VERSION ""

NS_ :

BS_:

BU_: MVS RCR_R RCR_L SNR ADAS ADAS_GW ENM THM CHR BAT BEV BEV_GW MET C_ECU C_ECU_GW

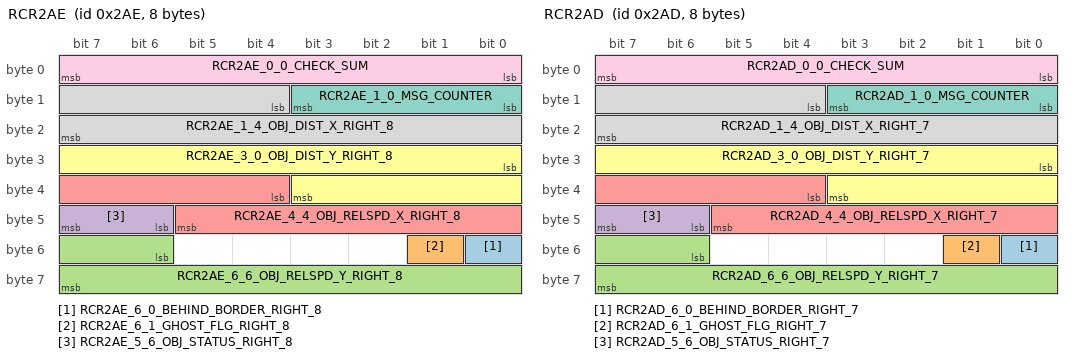
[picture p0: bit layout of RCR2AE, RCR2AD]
BO_ 686 RCR2AE: 8 RCR_R
 SG_ RCR2AE_6_0_BEHIND_BORDER_RIGHT_8 : 48|1@1+ (1,0) [0|1] ""  ADAS
 SG_ RCR2AE_6_1_GHOST_FLG_RIGHT_8 : 49|1@1+ (1,0) [0|1] ""  ADAS
 SG_ RCR2AE_6_6_OBJ_RELSPD_Y_RIGHT_8 : 54|10@1- (0.1,0) [-51.2|51.1] "m/s"  ADAS
 SG_ RCR2AE_5_6_OBJ_STATUS_RIGHT_8 : 46|2@1+ (1,0) [0|3] ""  ADAS
 SG_ RCR2AE_4_4_OBJ_RELSPD_X_RIGHT_8 : 36|10@1- (0.1,0) [-51.2|51.1] "m/s"  ADAS
 SG_ RCR2AE_3_0_OBJ_DIST_Y_RIGHT_8 : 24|12@1- (0.1,0) [-204.8|204.7] "m"  ADAS
 SG_ RCR2AE_1_0_MSG_COUNTER : 8|4@1+ (1,0) [0|15] ""  ADAS
 SG_ RCR2AE_1_4_OBJ_DIST_X_RIGHT_8 : 12|12@1- (0.1,0) [-204.8|204.7] "m"  ADAS
 SG_ RCR2AE_0_0_CHECK_SUM : 0|8@1+ (1,0) [0|255] ""  ADAS

BO_ 685 RCR2AD: 8 RCR_R
 SG_ RCR2AD_6_0_BEHIND_BORDER_RIGHT_7 : 48|1@1+ (1,0) [0|1] ""  ADAS
 SG_ RCR2AD_6_1_GHOST_FLG_RIGHT_7 : 49|1@1+ (1,0) [0|1] ""  ADAS
 SG_ RCR2AD_6_6_OBJ_RELSPD_Y_RIGHT_7 : 54|10@1- (0.1,0) [-51.2|51.1] "m/s"  ADAS
 SG_ RCR2AD_5_6_OBJ_STATUS_RIGHT_7 : 46|2@1+ (1,0) [0|3] ""  ADAS
 SG_ RCR2AD_4_4_OBJ_RELSPD_X_RIGHT_7 : 36|10@1- (0.1,0) [-51.2|51.1] "m/s"  ADAS
 SG_ RCR2AD_3_0_OBJ_DIST_Y_RIGHT_7 : 24|12@1- (0.1,0) [-204.8|204.7] "m"  ADAS
 SG_ RCR2AD_1_0_MSG_COUNTER : 8|4@1+ (1,0) [0|15] ""  ADAS
 SG_ RCR2AD_1_4_OBJ_DIST_X_RIGHT_7 : 12|12@1- (0.1,0) [-204.8|204.7] "m"  ADAS
 SG_ RCR2AD_0_0_CHECK_SUM : 0|8@1+ (1,0) [0|255] ""  ADAS

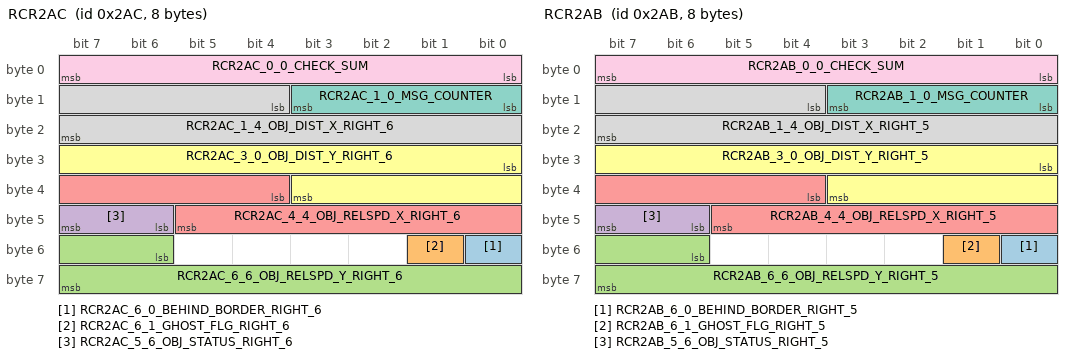
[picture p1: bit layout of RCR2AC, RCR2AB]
BO_ 684 RCR2AC: 8 RCR_R
 SG_ RCR2AC_6_0_BEHIND_BORDER_RIGHT_6 : 48|1@1+ (1,0) [0|1] ""  ADAS
 SG_ RCR2AC_6_1_GHOST_FLG_RIGHT_6 : 49|1@1+ (1,0) [0|1] ""  ADAS
 SG_ RCR2AC_6_6_OBJ_RELSPD_Y_RIGHT_6 : 54|10@1- (0.1,0) [-51.2|51.1] "m/s"  ADAS
 SG_ RCR2AC_5_6_OBJ_STATUS_RIGHT_6 : 46|2@1+ (1,0) [0|3] ""  ADAS
 SG_ RCR2AC_4_4_OBJ_RELSPD_X_RIGHT_6 : 36|10@1- (0.1,0) [-51.2|51.1] "m/s"  ADAS
 SG_ RCR2AC_3_0_OBJ_DIST_Y_RIGHT_6 : 24|12@1- (0.1,0) [-204.8|204.7] "m"  ADAS
 SG_ RCR2AC_1_0_MSG_COUNTER : 8|4@1+ (1,0) [0|15] ""  ADAS
 SG_ RCR2AC_1_4_OBJ_DIST_X_RIGHT_6 : 12|12@1- (0.1,0) [-204.8|204.7] "m"  ADAS
 SG_ RCR2AC_0_0_CHECK_SUM : 0|8@1+ (1,0) [0|255] ""  ADAS

BO_ 683 RCR2AB: 8 RCR_R
 SG_ RCR2AB_6_0_BEHIND_BORDER_RIGHT_5 : 48|1@1+ (1,0) [0|1] ""  ADAS
 SG_ RCR2AB_6_1_GHOST_FLG_RIGHT_5 : 49|1@1+ (1,0) [0|1] ""  ADAS
 SG_ RCR2AB_6_6_OBJ_RELSPD_Y_RIGHT_5 : 54|10@1- (0.1,0) [-51.2|51.1] "m/s"  ADAS
 SG_ RCR2AB_5_6_OBJ_STATUS_RIGHT_5 : 46|2@1+ (1,0) [0|3] ""  ADAS
 SG_ RCR2AB_4_4_OBJ_RELSPD_X_RIGHT_5 : 36|10@1- (0.1,0) [-51.2|51.1] "m/s"  ADAS
 SG_ RCR2AB_3_0_OBJ_DIST_Y_RIGHT_5 : 24|12@1- (0.1,0) [-204.8|204.7] "m"  ADAS
 SG_ RCR2AB_1_0_MSG_COUNTER : 8|4@1+ (1,0) [0|15] ""  ADAS
 SG_ RCR2AB_1_4_OBJ_DIST_X_RIGHT_5 : 12|12@1- (0.1,0) [-204.8|204.7] "m"  ADAS
 SG_ RCR2AB_0_0_CHECK_SUM : 0|8@1+ (1,0) [0|255] ""  ADAS

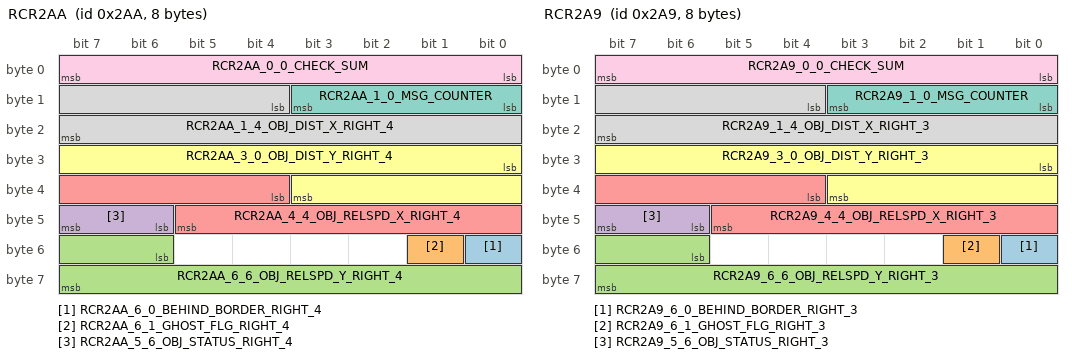
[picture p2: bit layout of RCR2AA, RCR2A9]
BO_ 682 RCR2AA: 8 RCR_R
 SG_ RCR2AA_6_0_BEHIND_BORDER_RIGHT_4 : 48|1@1+ (1,0) [0|1] ""  ADAS
 SG_ RCR2AA_6_1_GHOST_FLG_RIGHT_4 : 49|1@1+ (1,0) [0|1] ""  ADAS
 SG_ RCR2AA_6_6_OBJ_RELSPD_Y_RIGHT_4 : 54|10@1- (0.1,0) [-51.2|51.1] "m/s"  ADAS
 SG_ RCR2AA_5_6_OBJ_STATUS_RIGHT_4 : 46|2@1+ (1,0) [0|3] ""  ADAS
 SG_ RCR2AA_4_4_OBJ_RELSPD_X_RIGHT_4 : 36|10@1- (0.1,0) [-51.2|51.1] "m/s"  ADAS
 SG_ RCR2AA_3_0_OBJ_DIST_Y_RIGHT_4 : 24|12@1- (0.1,0) [-204.8|204.7] "m"  ADAS
 SG_ RCR2AA_1_0_MSG_COUNTER : 8|4@1+ (1,0) [0|15] ""  ADAS
 SG_ RCR2AA_1_4_OBJ_DIST_X_RIGHT_4 : 12|12@1- (0.1,0) [-204.8|204.7] "m"  ADAS
 SG_ RCR2AA_0_0_CHECK_SUM : 0|8@1+ (1,0) [0|255] ""  ADAS

BO_ 681 RCR2A9: 8 RCR_R
 SG_ RCR2A9_6_0_BEHIND_BORDER_RIGHT_3 : 48|1@1+ (1,0) [0|1] ""  ADAS
 SG_ RCR2A9_6_1_GHOST_FLG_RIGHT_3 : 49|1@1+ (1,0) [0|1] ""  ADAS
 SG_ RCR2A9_6_6_OBJ_RELSPD_Y_RIGHT_3 : 54|10@1- (0.1,0) [-51.2|51.1] "m/s"  ADAS
 SG_ RCR2A9_5_6_OBJ_STATUS_RIGHT_3 : 46|2@1+ (1,0) [0|3] ""  ADAS
 SG_ RCR2A9_4_4_OBJ_RELSPD_X_RIGHT_3 : 36|10@1- (0.1,0) [-51.2|51.1] "m/s"  ADAS
 SG_ RCR2A9_3_0_OBJ_DIST_Y_RIGHT_3 : 24|12@1- (0.1,0) [-204.8|204.7] "m"  ADAS
 SG_ RCR2A9_1_0_MSG_COUNTER : 8|4@1+ (1,0) [0|15] ""  ADAS
 SG_ RCR2A9_1_4_OBJ_DIST_X_RIGHT_3 : 12|12@1- (0.1,0) [-204.8|204.7] "m"  ADAS
 SG_ RCR2A9_0_0_CHECK_SUM : 0|8@1+ (1,0) [0|255] ""  ADAS

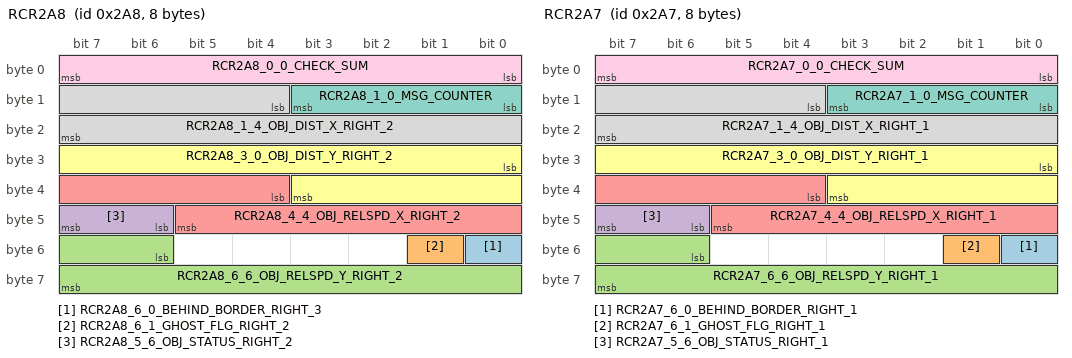
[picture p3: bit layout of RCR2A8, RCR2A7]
BO_ 680 RCR2A8: 8 RCR_R
 SG_ RCR2A8_6_0_BEHIND_BORDER_RIGHT_3 : 48|1@1+ (1,0) [0|1] ""  ADAS
 SG_ RCR2A8_6_1_GHOST_FLG_RIGHT_2 : 49|1@1+ (1,0) [0|1] ""  ADAS
 SG_ RCR2A8_6_6_OBJ_RELSPD_Y_RIGHT_2 : 54|10@1- (0.1,0) [-51.2|51.1] "m/s"  ADAS
 SG_ RCR2A8_5_6_OBJ_STATUS_RIGHT_2 : 46|2@1+ (1,0) [0|3] ""  ADAS
 SG_ RCR2A8_4_4_OBJ_RELSPD_X_RIGHT_2 : 36|10@1- (0.1,0) [-51.2|51.1] "m/s"  ADAS
 SG_ RCR2A8_3_0_OBJ_DIST_Y_RIGHT_2 : 24|12@1- (0.1,0) [-204.8|204.7] "m"  ADAS
 SG_ RCR2A8_1_0_MSG_COUNTER : 8|4@1+ (1,0) [0|15] ""  ADAS
 SG_ RCR2A8_1_4_OBJ_DIST_X_RIGHT_2 : 12|12@1- (0.1,0) [-204.8|204.7] "m"  ADAS
 SG_ RCR2A8_0_0_CHECK_SUM : 0|8@1+ (1,0) [0|255] ""  ADAS

BO_ 679 RCR2A7: 8 RCR_R
 SG_ RCR2A7_6_0_BEHIND_BORDER_RIGHT_1 : 48|1@1+ (1,0) [0|1] ""  ADAS
 SG_ RCR2A7_6_1_GHOST_FLG_RIGHT_1 : 49|1@1+ (1,0) [0|1] ""  ADAS
 SG_ RCR2A7_6_6_OBJ_RELSPD_Y_RIGHT_1 : 54|10@1- (0.1,0) [-51.2|51.1] "m/s"  ADAS
 SG_ RCR2A7_5_6_OBJ_STATUS_RIGHT_1 : 46|2@1+ (1,0) [0|3] ""  ADAS
 SG_ RCR2A7_4_4_OBJ_RELSPD_X_RIGHT_1 : 36|10@1- (0.1,0) [-51.2|51.1] "m/s"  ADAS
 SG_ RCR2A7_3_0_OBJ_DIST_Y_RIGHT_1 : 24|12@1- (0.1,0) [-204.8|204.7] "m"  ADAS
 SG_ RCR2A7_1_0_MSG_COUNTER : 8|4@1+ (1,0) [0|15] ""  ADAS
 SG_ RCR2A7_1_4_OBJ_DIST_X_RIGHT_1 : 12|12@1- (0.1,0) [-204.8|204.7] "m"  ADAS
 SG_ RCR2A7_0_0_CHECK_SUM : 0|8@1+ (1,0) [0|255] ""  ADAS

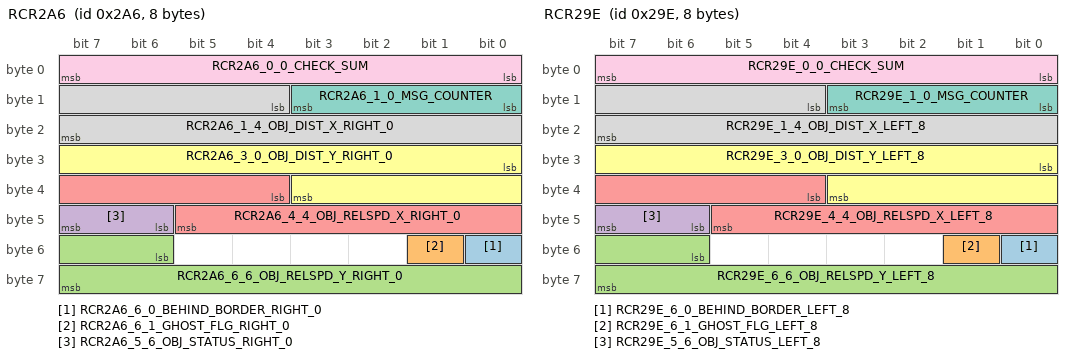
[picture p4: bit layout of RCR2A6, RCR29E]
BO_ 678 RCR2A6: 8 RCR_R
 SG_ RCR2A6_6_0_BEHIND_BORDER_RIGHT_0 : 48|1@1+ (1,0) [0|1] ""  ADAS
 SG_ RCR2A6_6_1_GHOST_FLG_RIGHT_0 : 49|1@1+ (1,0) [0|1] ""  ADAS
 SG_ RCR2A6_6_6_OBJ_RELSPD_Y_RIGHT_0 : 54|10@1- (0.1,0) [-51.2|51.1] "m/s"  ADAS
 SG_ RCR2A6_5_6_OBJ_STATUS_RIGHT_0 : 46|2@1+ (1,0) [0|3] ""  ADAS
 SG_ RCR2A6_4_4_OBJ_RELSPD_X_RIGHT_0 : 36|10@1- (0.1,0) [-51.2|51.1] "m/s"  ADAS
 SG_ RCR2A6_3_0_OBJ_DIST_Y_RIGHT_0 : 24|12@1- (0.1,0) [-204.8|204.7] "m"  ADAS
 SG_ RCR2A6_1_0_MSG_COUNTER : 8|4@1+ (1,0) [0|15] ""  ADAS
 SG_ RCR2A6_1_4_OBJ_DIST_X_RIGHT_0 : 12|12@1- (0.1,0) [-204.8|204.7] "m"  ADAS
 SG_ RCR2A6_0_0_CHECK_SUM : 0|8@1+ (1,0) [0|255] ""  ADAS

BO_ 670 RCR29E: 8 RCR_L
 SG_ RCR29E_6_0_BEHIND_BORDER_LEFT_8 : 48|1@1+ (1,0) [0|1] ""  ADAS
 SG_ RCR29E_6_1_GHOST_FLG_LEFT_8 : 49|1@1+ (1,0) [0|1] ""  ADAS
 SG_ RCR29E_6_6_OBJ_RELSPD_Y_LEFT_8 : 54|10@1- (0.1,0) [-51.2|51.1] "m/s"  ADAS
 SG_ RCR29E_5_6_OBJ_STATUS_LEFT_8 : 46|2@1+ (1,0) [0|3] ""  ADAS
 SG_ RCR29E_4_4_OBJ_RELSPD_X_LEFT_8 : 36|10@1- (0.1,0) [-51.2|51.1] "m/s"  ADAS
 SG_ RCR29E_3_0_OBJ_DIST_Y_LEFT_8 : 24|12@1- (0.1,0) [-204.8|204.7] "m"  ADAS
 SG_ RCR29E_1_0_MSG_COUNTER : 8|4@1+ (1,0) [0|15] ""  ADAS
 SG_ RCR29E_1_4_OBJ_DIST_X_LEFT_8 : 12|12@1- (0.1,0) [-204.8|204.7] "m"  ADAS
 SG_ RCR29E_0_0_CHECK_SUM : 0|8@1+ (1,0) [0|255] ""  ADAS

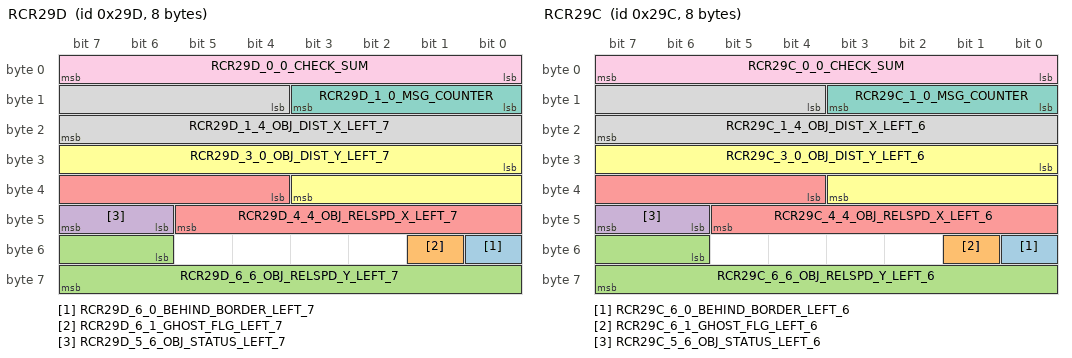
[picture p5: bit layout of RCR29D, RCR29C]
BO_ 669 RCR29D: 8 RCR_L
 SG_ RCR29D_6_0_BEHIND_BORDER_LEFT_7 : 48|1@1+ (1,0) [0|1] ""  ADAS
 SG_ RCR29D_6_1_GHOST_FLG_LEFT_7 : 49|1@1+ (1,0) [0|1] ""  ADAS
 SG_ RCR29D_6_6_OBJ_RELSPD_Y_LEFT_7 : 54|10@1- (0.1,0) [-51.2|51.1] "m/s"  ADAS
 SG_ RCR29D_5_6_OBJ_STATUS_LEFT_7 : 46|2@1+ (1,0) [0|3] ""  ADAS
 SG_ RCR29D_4_4_OBJ_RELSPD_X_LEFT_7 : 36|10@1- (0.1,0) [-51.2|51.1] "m/s"  ADAS
 SG_ RCR29D_3_0_OBJ_DIST_Y_LEFT_7 : 24|12@1- (0.1,0) [-204.8|204.7] "m"  ADAS
 SG_ RCR29D_1_0_MSG_COUNTER : 8|4@1+ (1,0) [0|15] ""  ADAS
 SG_ RCR29D_1_4_OBJ_DIST_X_LEFT_7 : 12|12@1- (0.1,0) [-204.8|204.7] "m"  ADAS
 SG_ RCR29D_0_0_CHECK_SUM : 0|8@1+ (1,0) [0|255] ""  ADAS

BO_ 668 RCR29C: 8 RCR_L
 SG_ RCR29C_6_0_BEHIND_BORDER_LEFT_6 : 48|1@1+ (1,0) [0|1] ""  ADAS
 SG_ RCR29C_6_1_GHOST_FLG_LEFT_6 : 49|1@1+ (1,0) [0|1] ""  ADAS
 SG_ RCR29C_6_6_OBJ_RELSPD_Y_LEFT_6 : 54|10@1- (0.1,0) [-51.2|51.1] "m/s"  ADAS
 SG_ RCR29C_5_6_OBJ_STATUS_LEFT_6 : 46|2@1+ (1,0) [0|3] ""  ADAS
 SG_ RCR29C_4_4_OBJ_RELSPD_X_LEFT_6 : 36|10@1- (0.1,0) [-51.2|51.1] "m/s"  ADAS
 SG_ RCR29C_3_0_OBJ_DIST_Y_LEFT_6 : 24|12@1- (0.1,0) [-204.8|204.7] "m"  ADAS
 SG_ RCR29C_1_0_MSG_COUNTER : 8|4@1+ (1,0) [0|15] ""  ADAS
 SG_ RCR29C_1_4_OBJ_DIST_X_LEFT_6 : 12|12@1- (0.1,0) [-204.8|204.7] "m"  ADAS
 SG_ RCR29C_0_0_CHECK_SUM : 0|8@1+ (1,0) [0|255] ""  ADAS

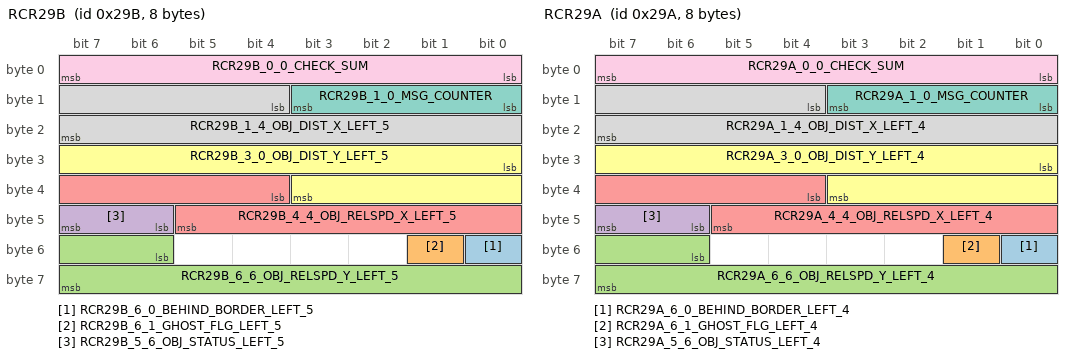
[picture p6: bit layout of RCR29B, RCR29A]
BO_ 667 RCR29B: 8 RCR_L
 SG_ RCR29B_6_0_BEHIND_BORDER_LEFT_5 : 48|1@1+ (1,0) [0|1] ""  ADAS
 SG_ RCR29B_6_1_GHOST_FLG_LEFT_5 : 49|1@1+ (1,0) [0|1] ""  ADAS
 SG_ RCR29B_6_6_OBJ_RELSPD_Y_LEFT_5 : 54|10@1- (0.1,0) [-51.2|51.1] "m/s"  ADAS
 SG_ RCR29B_5_6_OBJ_STATUS_LEFT_5 : 46|2@1+ (1,0) [0|3] ""  ADAS
 SG_ RCR29B_4_4_OBJ_RELSPD_X_LEFT_5 : 36|10@1- (0.1,0) [-51.2|51.1] "m/s"  ADAS
 SG_ RCR29B_3_0_OBJ_DIST_Y_LEFT_5 : 24|12@1- (0.1,0) [-204.8|204.7] "m"  ADAS
 SG_ RCR29B_1_0_MSG_COUNTER : 8|4@1+ (1,0) [0|15] ""  ADAS
 SG_ RCR29B_1_4_OBJ_DIST_X_LEFT_5 : 12|12@1- (0.1,0) [-204.8|204.7] "m"  ADAS
 SG_ RCR29B_0_0_CHECK_SUM : 0|8@1+ (1,0) [0|255] ""  ADAS

BO_ 666 RCR29A: 8 RCR_L
 SG_ RCR29A_6_0_BEHIND_BORDER_LEFT_4 : 48|1@1+ (1,0) [0|1] ""  ADAS
 SG_ RCR29A_6_1_GHOST_FLG_LEFT_4 : 49|1@1+ (1,0) [0|1] ""  ADAS
 SG_ RCR29A_6_6_OBJ_RELSPD_Y_LEFT_4 : 54|10@1- (0.1,0) [-51.2|51.1] "m/s"  ADAS
 SG_ RCR29A_5_6_OBJ_STATUS_LEFT_4 : 46|2@1+ (1,0) [0|3] ""  ADAS
 SG_ RCR29A_4_4_OBJ_RELSPD_X_LEFT_4 : 36|10@1- (0.1,0) [-51.2|51.1] "m/s"  ADAS
 SG_ RCR29A_3_0_OBJ_DIST_Y_LEFT_4 : 24|12@1- (0.1,0) [-204.8|204.7] "m"  ADAS
 SG_ RCR29A_1_0_MSG_COUNTER : 8|4@1+ (1,0) [0|15] ""  ADAS
 SG_ RCR29A_1_4_OBJ_DIST_X_LEFT_4 : 12|12@1- (0.1,0) [-204.8|204.7] "m"  ADAS
 SG_ RCR29A_0_0_CHECK_SUM : 0|8@1+ (1,0) [0|255] ""  ADAS

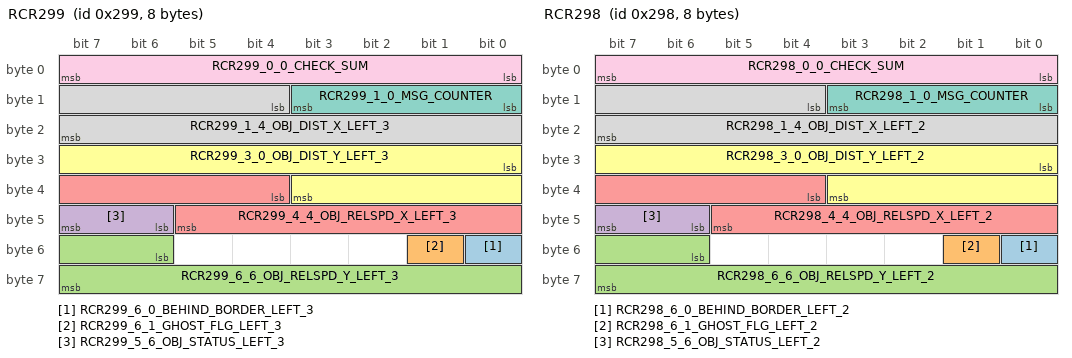
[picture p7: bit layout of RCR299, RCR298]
BO_ 665 RCR299: 8 RCR_L
 SG_ RCR299_6_0_BEHIND_BORDER_LEFT_3 : 48|1@1+ (1,0) [0|1] ""  ADAS
 SG_ RCR299_6_1_GHOST_FLG_LEFT_3 : 49|1@1+ (1,0) [0|1] ""  ADAS
 SG_ RCR299_6_6_OBJ_RELSPD_Y_LEFT_3 : 54|10@1- (0.1,0) [-51.2|51.1] "m/s"  ADAS
 SG_ RCR299_5_6_OBJ_STATUS_LEFT_3 : 46|2@1+ (1,0) [0|3] ""  ADAS
 SG_ RCR299_4_4_OBJ_RELSPD_X_LEFT_3 : 36|10@1- (0.1,0) [-51.2|51.1] "m/s"  ADAS
 SG_ RCR299_3_0_OBJ_DIST_Y_LEFT_3 : 24|12@1- (0.1,0) [-204.8|204.7] "m"  ADAS
 SG_ RCR299_1_0_MSG_COUNTER : 8|4@1+ (1,0) [0|15] ""  ADAS
 SG_ RCR299_1_4_OBJ_DIST_X_LEFT_3 : 12|12@1- (0.1,0) [-204.8|204.7] "m"  ADAS
 SG_ RCR299_0_0_CHECK_SUM : 0|8@1+ (1,0) [0|255] ""  ADAS

BO_ 664 RCR298: 8 RCR_L
 SG_ RCR298_6_0_BEHIND_BORDER_LEFT_2 : 48|1@1+ (1,0) [0|1] ""  ADAS
 SG_ RCR298_6_1_GHOST_FLG_LEFT_2 : 49|1@1+ (1,0) [0|1] ""  ADAS
 SG_ RCR298_6_6_OBJ_RELSPD_Y_LEFT_2 : 54|10@1- (0.1,0) [-51.2|51.1] "m/s"  ADAS
 SG_ RCR298_5_6_OBJ_STATUS_LEFT_2 : 46|2@1+ (1,0) [0|3] ""  ADAS
 SG_ RCR298_4_4_OBJ_RELSPD_X_LEFT_2 : 36|10@1- (0.1,0) [-51.2|51.1] "m/s"  ADAS
 SG_ RCR298_3_0_OBJ_DIST_Y_LEFT_2 : 24|12@1- (0.1,0) [-204.8|204.7] "m"  ADAS
 SG_ RCR298_1_0_MSG_COUNTER : 8|4@1+ (1,0) [0|15] ""  ADAS
 SG_ RCR298_1_4_OBJ_DIST_X_LEFT_2 : 12|12@1- (0.1,0) [-204.8|204.7] "m"  ADAS
 SG_ RCR298_0_0_CHECK_SUM : 0|8@1+ (1,0) [0|255] ""  ADAS

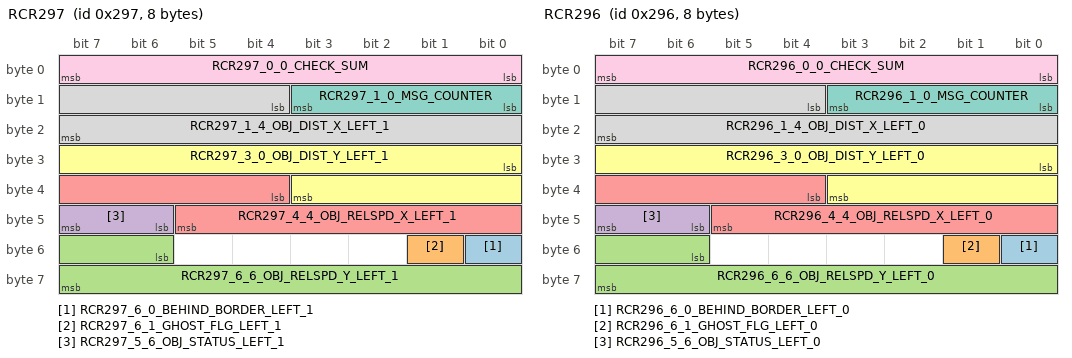
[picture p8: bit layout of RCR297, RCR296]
BO_ 663 RCR297: 8 RCR_L
 SG_ RCR297_6_0_BEHIND_BORDER_LEFT_1 : 48|1@1+ (1,0) [0|1] ""  ADAS
 SG_ RCR297_6_1_GHOST_FLG_LEFT_1 : 49|1@1+ (1,0) [0|1] ""  ADAS
 SG_ RCR297_6_6_OBJ_RELSPD_Y_LEFT_1 : 54|10@1- (0.1,0) [-51.2|51.1] "m/s"  ADAS
 SG_ RCR297_5_6_OBJ_STATUS_LEFT_1 : 46|2@1+ (1,0) [0|3] ""  ADAS
 SG_ RCR297_4_4_OBJ_RELSPD_X_LEFT_1 : 36|10@1- (0.1,0) [-51.2|51.1] "m/s"  ADAS
 SG_ RCR297_3_0_OBJ_DIST_Y_LEFT_1 : 24|12@1- (0.1,0) [-204.8|204.7] "m"  ADAS
 SG_ RCR297_1_0_MSG_COUNTER : 8|4@1+ (1,0) [0|15] ""  ADAS
 SG_ RCR297_1_4_OBJ_DIST_X_LEFT_1 : 12|12@1- (0.1,0) [-204.8|204.7] "m"  ADAS
 SG_ RCR297_0_0_CHECK_SUM : 0|8@1+ (1,0) [0|255] ""  ADAS

BO_ 662 RCR296: 8 RCR_L
 SG_ RCR296_6_0_BEHIND_BORDER_LEFT_0 : 48|1@1+ (1,0) [0|1] ""  ADAS
 SG_ RCR296_6_1_GHOST_FLG_LEFT_0 : 49|1@1+ (1,0) [0|1] ""  ADAS
 SG_ RCR296_6_6_OBJ_RELSPD_Y_LEFT_0 : 54|10@1- (0.1,0) [-51.2|51.1] "m/s"  ADAS
 SG_ RCR296_5_6_OBJ_STATUS_LEFT_0 : 46|2@1+ (1,0) [0|3] ""  ADAS
 SG_ RCR296_4_4_OBJ_RELSPD_X_LEFT_0 : 36|10@1- (0.1,0) [-51.2|51.1] "m/s"  ADAS
 SG_ RCR296_3_0_OBJ_DIST_Y_LEFT_0 : 24|12@1- (0.1,0) [-204.8|204.7] "m"  ADAS
 SG_ RCR296_1_0_MSG_COUNTER : 8|4@1+ (1,0) [0|15] ""  ADAS
 SG_ RCR296_1_4_OBJ_DIST_X_LEFT_0 : 12|12@1- (0.1,0) [-204.8|204.7] "m"  ADAS
 SG_ RCR296_0_0_CHECK_SUM : 0|8@1+ (1,0) [0|255] ""  ADAS

BO_ 552 RDR228: 8 RCR_L
 SG_ RDR228_7_0_EYE_TIMEOUT_ERROR_FLG : 56|1@1+ (1,0) [0|1] ""  C_ECU_GW
 SG_ RDR228_7_1_BLOCKAGE_FORMING_2 : 57|1@1+ (1,0) [0|1] ""  C_ECU_GW
 SG_ RDR228_7_2_WARN_LCA_R_1ST : 58|1@1+ (1,0) [0|1] ""  ADAS,MET,C_ECU_GW
 SG_ RDR228_7_3_WARN_LCA_L_1ST : 59|1@1+ (1,0) [0|1] ""  ADAS,MET,C_ECU_GW
 SG_ RDR228_7_4_WARN_LCA_R_2ND : 60|1@1+ (1,0) [0|1] ""  MET,C_ECU_GW
 SG_ RDR228_7_5_WARN_LCA_L_2ND : 61|1@1+ (1,0) [0|1] ""  MET,C_ECU_GW
 SG_ RDR228_7_6_WARN_RCTA_R : 62|1@1+ (1,0) [0|1] ""  MVS,MET,C_ECU_GW
 SG_ RDR228_7_7_WARN_RCTA_L : 63|1@1+ (1,0) [0|1] ""  MVS,MET,C_ECU_GW
 SG_ RDR228_6_0_WARN_BSD_R_1ST : 48|1@1+ (1,0) [0|1] ""  ADAS,MET,C_ECU_GW
 SG_ RDR228_6_1_WARN_BSD_L_1ST : 49|1@1+ (1,0) [0|1] ""  ADAS,MET,C_ECU_GW
 SG_ RDR228_6_2_WARN_BSD_R_2ND : 50|1@1+ (1,0) [0|1] ""  MET,C_ECU_GW
 SG_ RDR228_6_3_WARN_BSD_L_2ND : 51|1@1+ (1,0) [0|1] ""  MET,C_ECU_GW
 SG_ RDR228_6_5_BLOCKAGE_STS : 53|3@1+ (1,0) [0|5] ""  ADAS,C_ECU_GW
 SG_ RDR228_5_0_BSD_R_E : 40|1@1+ (1,0) [0|1] ""  ADAS,C_ECU_GW
 SG_ RDR228_5_1_BSD_L_E : 41|1@1+ (1,0) [0|1] ""  ADAS,C_ECU_GW
 SG_ RDR228_5_2_LCA_R_E : 42|1@1+ (1,0) [0|1] ""  ADAS,C_ECU_GW
 SG_ RDR228_5_3_LCA_L_E : 43|1@1+ (1,0) [0|1] ""  ADAS,C_ECU_GW
 SG_ RDR228_5_4_BSD_R_A : 44|1@1+ (1,0) [0|1] ""  ADAS,C_ECU_GW
 SG_ RDR228_5_5_BSD_L_A : 45|1@1+ (1,0) [0|1] ""  ADAS,C_ECU_GW
 SG_ RDR228_5_6_LCA_R_A : 46|1@1+ (1,0) [0|1] ""  ADAS,C_ECU_GW
 SG_ RDR228_5_7_LCA_L_A : 47|1@1+ (1,0) [0|1] ""  ADAS,C_ECU_GW
 SG_ RDR228_4_0_DOW_ACTIVELAMP : 32|1@1+ (1,0) [0|1] ""  C_ECU_GW
 SG_ RDR228_4_1_WARN_DOW_1ST_R : 33|1@1+ (1,0) [0|1] ""  C_ECU_GW
 SG_ RDR228_4_2_WARN_DOW_1ST_L : 34|1@1+ (1,0) [0|1] ""  C_ECU_GW
 SG_ RDR228_4_3_WARN_DOW_2ST_R : 35|1@1+ (1,0) [0|1] ""  C_ECU_GW
 SG_ RDR228_4_4_WARN_DOW_2ST_L : 36|1@1+ (1,0) [0|1] ""  C_ECU_GW
 SG_ RDR228_4_5_CSTM_STS_SRVD : 37|1@1+ (1,0) [0|1] ""  C_ECU_GW
 SG_ RDR228_4_6_CSTM_STS_BSD_LCA_2ND : 38|1@1+ (1,0) [0|1] ""  C_ECU_GW
 SG_ RDR228_4_7_CSTM_STS_RCTA : 39|1@1+ (1,0) [0|1] ""  C_ECU_GW
 SG_ RDR228_3_0_WARN_BSD_LCA_R_2ND : 24|1@1+ (1,0) [0|1] ""  MET,C_ECU_GW
 SG_ RDR228_3_1_WARN_BSD_LCA_L_2ND : 25|1@1+ (1,0) [0|1] ""  MET,C_ECU_GW
 SG_ RDR228_3_2_CSTM_STS_DOW : 26|1@1+ (1,0) [0|1] ""  C_ECU_GW
 SG_ RDR228_3_3_CSTM_STS_DOW_SFT_POS : 27|1@1+ (1,0) [0|1] ""  C_ECU_GW
 SG_ RDR228_3_5_CSTM_DSP_BSD_LCA : 29|1@1+ (1,0) [0|1] ""  C_ECU_GW
 SG_ RDR228_3_6_CSTM_DSP_BSD_LCA_2ND : 30|1@1+ (1,0) [0|1] ""  C_ECU_GW
 SG_ RDR228_3_7_CSTM_DSP_RCTA : 31|1@1+ (1,0) [0|1] ""  C_ECU_GW
 SG_ RDR228_2_0_CSTM_DSP_DOW : 16|1@1+ (1,0) [0|1] ""  C_ECU_GW
 SG_ RDR228_2_1_EYE_LOCAL_BUS1_FAIL : 17|1@1+ (1,0) [0|1] ""  C_ECU_GW
 SG_ RDR228_2_2_CSTM_DSP_DOW_SFT_POS : 18|1@1+ (1,0) [0|1] ""  C_ECU_GW
 SG_ RDR228_2_3_ELK_STOP_REQ_FLG : 19|1@1+ (1,0) [0|1] ""  C_ECU_GW
 SG_ RDR228_2_4_FAIL_RDRSYS : 20|1@1+ (1,0) [0|1] ""  ADAS,MET,C_ECU_GW
 SG_ RDR228_2_5_STOP_RDRSYS : 21|1@1+ (1,0) [0|1] ""  ADAS,MET,C_ECU_GW
 SG_ RDR228_2_6_ON_OFF_RDRSYS : 22|1@1+ (1,0) [0|1] ""  ADAS,MET,C_ECU_GW
 SG_ RDR228_2_7_BLOCKAGE_FORMING : 23|1@1+ (1,0) [0|1] ""  ADAS,MET,C_ECU_GW
 SG_ RDR228_1_0_MSG_COUNTER : 8|4@1+ (1,0) [0|15] ""  MVS,ADAS,MET,C_ECU_GW
 SG_ RDR228_1_4_BATT_OFF_CAUSE : 12|1@1+ (1,0) [0|1] ""  C_ECU_GW
 SG_ RDR228_1_5_CSTM_GLO_1 : 13|1@1+ (1,0) [0|1] ""  C_ECU_GW
 SG_ RDR228_1_6_CSTM_GLO_3 : 14|1@1+ (1,0) [0|1] ""  C_ECU_GW
 SG_ RDR228_1_7_CSTM_GLO_2 : 15|1@1+ (1,0) [0|1] ""  C_ECU_GW
 SG_ RDR228_0_0_CHECK_SUM : 0|8@1+ (1,0) [0|255] ""  MVS,ADAS,MET,C_ECU_GW

BO_ 1372 RCR55C: 8 RCR_R
 SG_ RCR55C_7_0_NETWORK_STATUS : 7|64@0+ (1,0) [0|0] ""  C_ECU

BO_ 1371 RCR55B: 8 RCR_L
 SG_ RCR55B_7_0_NETWORK_STATUS : 7|64@0+ (1,0) [0|0] ""  C_ECU

BO_ 1359 SNR54F: 8 SNR
 SG_ SNR54F_0_0_NETWORK_STATUS : 0|64@1+ (1,0) [0|0] ""  C_ECU

BO_ 966 EYE3C6: 8 C_ECU_GW
 SG_ EYE3C6_7_0_VEHICLE_DIST_L_LANE1 : 56|7@1+ (1,0) [0|27] ""  MET
 SG_ EYE3C6_7_7_VEHICLE_L_LANE1 : 63|1@1+ (1,0) [0|1] ""  MET
 SG_ EYE3C6_6_0_VEHICLE_DIST_R_LANE1 : 48|7@1+ (1,0) [0|27] ""  MET
 SG_ EYE3C6_6_7_VEHICLE_R_LANE1 : 55|1@1+ (1,0) [0|1] ""  MET
 SG_ EYE3C6_5_0_VEHICLE_DIST_WY_WAY1 : 40|7@1+ (1,0) [0|27] ""  MET
 SG_ EYE3C6_5_7_VEHICLE_MY_WAY1 : 47|1@1+ (1,0) [0|1] ""  MET
 SG_ EYE3C6_4_0_SIDE_MOVEMENT : 32|8@1- (1,0) [-100|100] ""  MET
 SG_ EYE3C6_3_0_RADER_RR : 24|2@1+ (1,0) [0|3] ""  MET
 SG_ EYE3C6_3_2_RADER_RL : 26|2@1+ (1,0) [0|3] ""  MET
 SG_ EYE3C6_3_4_RADER_FR : 28|2@1+ (1,0) [0|3] "" Vector__XXX
 SG_ EYE3C6_3_6_RADER_FL : 30|2@1+ (1,0) [0|3] "" Vector__XXX
 SG_ EYE3C6_2_0_RADER_R : 16|2@1+ (1,0) [0|3] ""  MET
 SG_ EYE3C6_2_2_MY_WAY_LANE_CAR_COLOR : 18|2@1+ (1,0) [0|3] ""  MET
 SG_ EYE3C6_2_4_TARGET_CAR : 20|3@1+ (1,0) [0|7] ""  MET
 SG_ EYE3C6_2_7_ALC_STS : 23|1@1+ (1,0) [0|1] ""  MET
 SG_ EYE3C6_1_0_MSG_COUNTER : 8|4@1+ (1,0) [0|15] ""  MET
 SG_ EYE3C6_1_4_L_LANE_CAR_COLOR : 12|2@1+ (1,0) [0|3] ""  MET
 SG_ EYE3C6_1_6_R_LANE_CAR_COLOR : 14|2@1+ (1,0) [0|3] ""  MET
 SG_ EYE3C6_0_0_CHECK_SUM : 0|8@1+ (1,0) [0|255] ""  MET

BO_ 965 EYE3C5: 8 C_ECU_GW
 SG_ EYE3C5_7_0_GSR_AEBS_FUNC_INFO : 56|1@1+ (1,0) [0|1] ""  MET
 SG_ EYE3C5_7_1_CSTM_CRV_ADJUST : 57|2@1+ (1,0) [0|3] "" Vector__XXX
 SG_ EYE3C5_7_3_BRAKE_HAPTIC_CURR : 59|2@1+ (1,0) [0|3] "" Vector__XXX
 SG_ EYE3C5_7_5_SAFETY_MODE_FUNC_INFO : 61|1@1+ (1,0) [0|1] "" Vector__XXX
 SG_ EYE3C5_7_6_SAFETY_MODE_CURR : 62|1@1+ (1,0) [0|1] "" Vector__XXX
 SG_ EYE3C5_7_7_GSR_DDAW_FUNC_INFO : 63|1@1+ (1,0) [0|1] ""  MET
 SG_ EYE3C5_6_0_IND_SAFETY_MODE : 48|1@1+ (1,0) [0|1] ""  MET
 SG_ EYE3C5_6_1_ALC_ACTIVE_L : 49|1@1+ (1,0) [0|1] ""  MET
 SG_ EYE3C5_6_2_FLASHING_IND_SAFETY : 50|1@1+ (1,0) [0|1] ""  MET
 SG_ EYE3C5_6_3_OVERTAKE_FUNC_INFO : 51|1@1+ (1,0) [0|1] "" Vector__XXX
 SG_ EYE3C5_6_4_CRV_ADJUST_FUNC_INFO : 52|1@1+ (1,0) [0|1] "" Vector__XXX
 SG_ EYE3C5_6_5_STRG_TOUCHSENSOR_WRNG : 53|1@1+ (1,0) [0|1] ""  MET
 SG_ EYE3C5_6_6_ALC_ACTIVE_R : 54|1@1+ (1,0) [0|1] ""  MET
 SG_ EYE3C5_6_7_CSTM_GSR_ISA : 55|1@1+ (1,0) [0|1] ""  MET
 SG_ EYE3C5_5_0_LANE_COLOR_R : 40|2@1+ (1,0) [0|3] ""  MET
 SG_ EYE3C5_5_2_LINE_LANE_R : 42|2@1+ (1,0) [0|3] ""  MET
 SG_ EYE3C5_5_4_LANE_COLOR_L : 44|2@1+ (1,0) [0|3] ""  MET
 SG_ EYE3C5_5_6_LINE_LANE_L : 46|2@1+ (1,0) [0|3] ""  MET
 SG_ EYE3C5_4_0_ROAD_SHAPE_CURVE : 32|4@1+ (1,0) [0|15] ""  MET
 SG_ EYE3C5_4_4_ROAD_SHAPE_DIRECTION : 36|1@1+ (1,0) [0|1] ""  MET
 SG_ EYE3C5_4_5_CSTM_GSR_ELKS : 37|1@1+ (1,0) [0|1] ""  MET
 SG_ EYE3C5_4_6_MY_WAY_COLOR : 38|2@1+ (1,0) [0|3] ""  MET
 SG_ EYE3C5_3_0_AD_DRV_ICON : 24|2@1+ (1,0) [0|3] ""  MET
 SG_ EYE3C5_3_2_AUTO_HANDLE_ICON : 26|2@1+ (1,0) [0|3] ""  MET
 SG_ EYE3C5_3_4_WITH_HANDS_ICON : 28|1@1+ (1,0) [0|1] ""  MET
 SG_ EYE3C5_3_5_STRG_HAPTIC_WRNG : 29|1@1+ (1,0) [0|1] ""  MET
 SG_ EYE3C5_3_6_BRK_HPTC_FUNC_INFO : 30|1@1+ (1,0) [0|1] "" Vector__XXX
 SG_ EYE3C5_3_7_SPECIAL_DISP_INFO : 31|1@1+ (1,0) [0|1] "" Vector__XXX
 SG_ EYE3C5_2_0_SLOWDWN_CURVE_ICON : 16|3@1+ (1,0) [0|7] ""  MET
 SG_ EYE3C5_2_3_FLASHING_IND : 19|1@1+ (1,0) [0|1] ""  MET
 SG_ EYE3C5_2_4_ATTENTION_TOLLGATE : 20|2@1+ (1,0) [0|3] ""  MET
 SG_ EYE3C5_2_6_MAPLOCATOR_IND : 22|2@1+ (1,0) [0|3] ""  MET
 SG_ EYE3C5_1_0_MSG_COUNTER : 8|4@1+ (1,0) [0|15] ""  MET
 SG_ EYE3C5_1_4_ISA_FAIL_IND : 12|1@1+ (1,0) [0|1] ""  MET
 SG_ EYE3C5_1_5_SLWF_OFF_IND : 13|1@1+ (1,0) [0|1] ""  MET
 SG_ EYE3C5_1_6_CSTM_SLWF_SET : 14|1@1+ (1,0) [0|1] "" Vector__XXX
 SG_ EYE3C5_1_7_CSTM_TSR_SOUND_SET : 15|1@1+ (1,0) [0|1] "" Vector__XXX
 SG_ EYE3C5_0_0_CHECK_SUM : 0|8@1+ (1,0) [0|255] ""  MET

BO_ 964 EYE3C4: 8 C_ECU_GW
 SG_ EYE3C4_7_0_PCR_FAIL_OFF_IND : 56|2@1+ (1,0) [0|3] ""  MET
 SG_ EYE3C4_7_2_AES_FAIL_OFF_IND : 58|2@1+ (1,0) [0|3] ""  MET
 SG_ EYE3C4_7_4_LDP_FAIL_OFF_IND : 60|2@1+ (1,0) [0|3] ""  MET
 SG_ EYE3C4_7_6_ELK_FAIL_OFF_IND : 62|2@1+ (1,0) [0|3] ""  MET
 SG_ EYE3C4_6_0_MCAM_SYS_FAIL_HALT : 48|2@1+ (1,0) [0|3] ""  MET
 SG_ EYE3C4_6_2_MCAM_FUNC_INFO : 50|1@1+ (1,0) [0|1] "" Vector__XXX
 SG_ EYE3C4_6_3_EYE_DRV_ACTION_REQ : 51|3@1+ (1,0) [0|7] ""  MET
 SG_ EYE3C4_6_6_LDW_SND_OFF_FAIL_IND : 54|2@1+ (1,0) [0|3] ""  MET
 SG_ EYE3C4_5_0_EAM_GREEN : 40|2@1+ (1,0) [0|3] "" Vector__XXX
 SG_ EYE3C4_5_2_EAM_BLUE : 42|2@1+ (1,0) [0|3] "" Vector__XXX
 SG_ EYE3C4_5_4_EAM_GREEN_2 : 44|2@1+ (1,0) [0|3] "" Vector__XXX
 SG_ EYE3C4_5_6_FCW_SND_OFF_FAIL_IND : 46|2@1+ (1,0) [0|3] ""  MET
 SG_ EYE3C4_4_0_EAM_YELLOW : 32|4@1+ (1,0) [0|15] "" Vector__XXX
 SG_ EYE3C4_4_4_EAM_RED : 36|4@1+ (1,0) [0|15] "" Vector__XXX
 SG_ EYE3C4_3_0_CODE_NO_BUZZER : 24|8@1+ (1,0) [0|255] ""  MET
 SG_ EYE3C4_2_0_CODE_WARN : 16|8@1+ (1,0) [0|255] ""  MET
 SG_ EYE3C4_1_0_MSG_COUNTER : 8|4@1+ (1,0) [0|15] ""  MET
 SG_ EYE3C4_1_5_SNR_DRV_ACTION_REQ : 13|3@1+ (1,0) [0|7] ""  MET
 SG_ EYE3C4_0_0_CHECK_SUM : 0|8@1+ (1,0) [0|255] ""  MET

BO_ 805 EYE325: 8 C_ECU_GW
 SG_ EYE325_6_5_SONAR_DISP_INT : 53|1@1+ (1,0) [0|1] ""  MET
 SG_ EYE325_5_0_SONAR_R_L_CORNER_4LVL : 40|3@1+ (1,0) [0|7] ""  MET
 SG_ EYE325_5_3_SONAR_R_R_CORNER_4LVL : 43|3@1+ (1,0) [0|7] ""  MET
 SG_ EYE325_4_0_SONAR_R_CENTER : 32|3@1+ (1,0) [0|7] ""  MET
 SG_ EYE325_4_3_SONAR_LEVEL : 35|3@1+ (1,0) [0|7] ""  MET
 SG_ EYE325_4_6_RAB_WARNING : 38|2@1+ (1,0) [0|3] ""  MET
 SG_ EYE325_3_0_SONAR_R_L_CORNER : 24|2@1+ (1,0) [0|3] "" Vector__XXX
 SG_ EYE325_3_2_SONAR_R_R_CORNER : 26|2@1+ (1,0) [0|3] "" Vector__XXX
 SG_ EYE325_3_4_SONAR_R_L_SIDE : 28|2@1+ (1,0) [0|3] "" Vector__XXX
 SG_ EYE325_3_6_SONAR_R_R_SIDE : 30|2@1+ (1,0) [0|3] "" Vector__XXX
 SG_ EYE325_2_0_RAB_OFF : 16|1@1+ (1,0) [0|1] ""  MET
 SG_ EYE325_2_1_SONAR_OFF : 17|1@1+ (1,0) [0|1] ""  MET
 SG_ EYE325_2_2_SONAR_SYS_HALT : 18|2@1+ (1,0) [0|3] ""  MET
 SG_ EYE325_2_4_SONAR_SYS_FAIL : 20|2@1+ (1,0) [0|3] ""  MET
 SG_ EYE325_2_6_RAB_DISABLE : 22|1@1+ (1,0) [0|1] "" Vector__XXX
 SG_ EYE325_2_7_SONAR_DISABLE : 23|1@1+ (1,0) [0|1] "" Vector__XXX
 SG_ EYE325_1_0_MSG_COUNTER : 8|4@1+ (1,0) [0|15] ""  MET
 SG_ EYE325_1_4_CSTM_RAB_SET : 12|1@1+ (1,0) [0|1] "" Vector__XXX
 SG_ EYE325_1_5_CSTM_CLR_SNR_SET : 13|1@1+ (1,0) [0|1] "" Vector__XXX
 SG_ EYE325_1_6_RAB : 14|1@1+ (1,0) [0|1] ""  MET
 SG_ EYE325_1_7_SONAR_NO_DISP : 15|1@1+ (1,0) [0|1] "" Vector__XXX
 SG_ EYE325_0_0_CHECK_SUM : 0|8@1+ (1,0) [0|255] ""  MET

BO_ 804 EYE324: 8 C_ECU_GW
 SG_ EYE324_7_5_TSR_MODE_DISP : 61|2@1+ (1,0) [0|3] ""  MET
 SG_ EYE324_7_7_ICON_IND : 63|1@1+ (1,0) [0|1] "" Vector__XXX
 SG_ EYE324_6_0_COMPLEMENTARY_IND_C : 48|4@1+ (1,0) [0|15] ""  MET
 SG_ EYE324_6_4_COMPLEMENTARY_IND_D : 52|4@1+ (1,0) [0|15] ""  MET
 SG_ EYE324_5_0_SPEEDLIMIT_B : 40|8@1+ (1,0) [0|255] ""  MET
 SG_ EYE324_4_0_TRAFFIC_SIGN_B : 32|5@1+ (1,0) [0|31] ""  MET
 SG_ EYE324_4_5_FLASHING_IND_B : 37|1@1+ (1,0) [0|1] ""  MET
 SG_ EYE324_4_6_FRAME_COLOR_B : 38|2@1+ (1,0) [0|3] ""  MET
 SG_ EYE324_3_0_SPEEDLIMIT_A : 24|8@1+ (1,0) [0|255] ""  MET
 SG_ EYE324_2_0_TRAFFIC_SIGN_A : 16|5@1+ (1,0) [0|31] ""  MET
 SG_ EYE324_2_5_FLASHING_IND_A : 21|1@1+ (1,0) [0|1] ""  MET
 SG_ EYE324_2_6_FRAME_COLOR_A : 22|2@1+ (1,0) [0|3] ""  MET
 SG_ EYE324_1_0_MSG_COUNTER : 8|4@1+ (1,0) [0|15] ""  MET
 SG_ EYE324_1_4_FLASHING_IND_D : 12|1@1+ (1,0) [0|1] ""  MET
 SG_ EYE324_1_5_FLASHING_IND_C : 13|1@1+ (1,0) [0|1] ""  MET
 SG_ EYE324_1_6_ICON_COLOR : 14|2@1+ (1,0) [0|3] ""  MET
 SG_ EYE324_0_0_CHECK_SUM : 0|8@1+ (1,0) [0|255] ""  MET

BO_ 803 EYE323: 8 C_ECU_GW
 SG_ EYE323_7_0_ISA_OFFSET_CURR : 56|5@1+ (1,-10) [-10|10] "" Vector__XXX
 SG_ EYE323_7_5_SLIF_FUNC_INFO : 61|1@1+ (1,0) [0|1] ""  MET
 SG_ EYE323_7_6_ISA_FUNC_INFO : 62|1@1+ (1,0) [0|1] "" Vector__XXX
 SG_ EYE323_7_7_ISA_CUSTOMIZE_CURR : 63|1@1+ (1,0) [0|1] ""  MET
 SG_ EYE323_6_0_LDW_OFFSW_INFO : 48|1@1+ (1,0) [0|1] "" Vector__XXX
 SG_ EYE323_6_1_LDW_ON_OFF_SET : 49|1@1+ (1,0) [0|1] "" Vector__XXX
 SG_ EYE323_6_2_CSTM_DDAW_WARN_SET : 50|1@1+ (1,0) [0|1] "" Vector__XXX
 SG_ EYE323_6_3_IACC_FUNC_INFO : 51|1@1+ (1,0) [0|1] ""  MET
 SG_ EYE323_6_5_CSTM_LDW_TIMING_SET : 53|1@1+ (1,0) [0|1] "" Vector__XXX
 SG_ EYE323_6_6_CSTM_LDW_TIMING : 54|1@1+ (1,0) [0|1] "" Vector__XXX
 SG_ EYE323_6_7_SLOWDOWNL_FUNC_INFO : 55|1@1+ (1,0) [0|1] "" Vector__XXX
 SG_ EYE323_5_0_CNG_GRN_CONT_CURR : 40|1@1+ (1,0) [0|1] "" Vector__XXX
 SG_ EYE323_5_1_TRAFFIC_FUNC_INFO : 41|1@1+ (1,0) [0|1] "" Vector__XXX
 SG_ EYE323_5_2_FCW_OFFSW_INFO : 42|1@1+ (1,0) [0|1] "" Vector__XXX
 SG_ EYE323_5_3_FCW_ON_OFF_SET : 43|1@1+ (1,0) [0|1] "" Vector__XXX
 SG_ EYE323_5_4_WARNING_SEL_CURR : 44|1@1+ (1,0) [0|1] "" Vector__XXX
 SG_ EYE323_5_5_HAPT_FUNC_INFO : 45|1@1+ (1,0) [0|1] "" Vector__XXX
 SG_ EYE323_5_6_TOLLGATE_CONT_CURR : 46|1@1+ (1,0) [0|1] "" Vector__XXX
 SG_ EYE323_5_7_CURVE_CONT_CURR : 47|1@1+ (1,0) [0|1] "" Vector__XXX
 SG_ EYE323_4_0_FCTB_ICON_L : 32|2@1+ (1,0) [0|3] ""  MVS
 SG_ EYE323_4_2_FCTB_ICON_R : 34|2@1+ (1,0) [0|3] ""  MVS
 SG_ EYE323_4_4_FCW_CONT_CURR : 36|2@1+ (1,0) [0|3] "" Vector__XXX
 SG_ EYE323_4_6_FCW_DISPLAY_SEL : 38|2@1+ (1,0) [0|3] "" Vector__XXX
 SG_ EYE323_3_0_AES_FUNC_INFO : 24|1@1+ (1,0) [0|1] ""  MET
 SG_ EYE323_3_1_CSTM_TSR_NO_ENTRY_SET : 25|1@1+ (1,0) [0|1] "" Vector__XXX
 SG_ EYE323_3_2_CSTM_TSR_STOP_SET : 26|1@1+ (1,0) [0|1] "" Vector__XXX
 SG_ EYE323_3_3_CSTM_TSR_GIVE_WAY_SET : 27|1@1+ (1,0) [0|1] "" Vector__XXX
 SG_ EYE323_3_4_WILDERNESS : 28|1@1+ (1,0) [0|1] "" Vector__XXX
 SG_ EYE323_3_5_AES_OFF : 29|1@1+ (1,0) [0|1] ""  MET
 SG_ EYE323_3_6_FCTB_IND : 30|2@1+ (1,0) [0|3] ""  MET
 SG_ EYE323_2_0_CSTM_LDW_ALK_B : 16|2@1+ (1,0) [0|3] "" Vector__XXX
 SG_ EYE323_2_2_CSTM_P_CR : 18|1@1+ (1,0) [0|1] "" Vector__XXX
 SG_ EYE323_2_3_SLOWDOWN_FUNC_INFO2 : 19|1@1+ (1,0) [0|1] "" Vector__XXX
 SG_ EYE323_2_4_CID_CODE_WARN : 20|4@1+ (1,0) [0|15] "" Vector__XXX
 SG_ EYE323_1_0_MSG_COUNTER : 8|4@1+ (1,0) [0|15] ""  MVS,MET
 SG_ EYE323_1_4_DISP_FOLLOW_FORWARD : 12|1@1+ (1,0) [0|1] ""  MET
 SG_ EYE323_1_5_KEEP_LINE_SENTER_ACT : 13|1@1+ (1,0) [0|1] ""  MET
 SG_ EYE323_1_6_DDAW_FAIL_OFF : 14|2@1+ (1,0) [0|3] ""  MET
 SG_ EYE323_0_0_CHECK_SUM : 0|8@1+ (1,0) [0|255] ""  MVS,MET

BO_ 802 EYE322: 8 C_ECU_GW
 SG_ EYE322_7_0_CSTM_ACC_CONT_SET : 56|2@1+ (1,0) [0|3] "" Vector__XXX
 SG_ EYE322_7_2_ELK_OFF_IND : 58|1@1+ (1,0) [0|1] ""  MET
 SG_ EYE322_7_3_LIGHT_EAM_YELLOW : 59|2@1+ (1,0) [0|3] "" Vector__XXX
 SG_ EYE322_7_5_BROKEN_LINE_L : 61|1@1+ (1,0) [0|1] ""  MET
 SG_ EYE322_7_6_TJA_ACTIVE : 62|1@1+ (1,0) [0|1] "" Vector__XXX
 SG_ EYE322_7_7_BROKEN_LINE_R : 63|1@1+ (1,0) [0|1] ""  MET
 SG_ EYE322_6_0_CSTM_MIS_AT_START : 48|2@1+ (1,0) [0|3] ""  MET
 SG_ EYE322_6_2_CSTM_ALK_TJA_SET : 50|1@1+ (1,0) [0|1] "" Vector__XXX
 SG_ EYE322_6_3_CSTM_LANE_SET : 51|1@1+ (1,0) [0|1] "" Vector__XXX
 SG_ EYE322_6_4_LDP_OFF_IND : 52|1@1+ (1,0) [0|1] ""  MET
 SG_ EYE322_6_5_INDICATOR_MODE_L : 53|2@1+ (1,0) [0|3] "" Vector__XXX
 SG_ EYE322_6_7_CSTM_ELK_SET : 55|1@1+ (1,0) [0|1] "" Vector__XXX
 SG_ EYE322_5_0_CSTM_MIS_AT_BACK : 40|1@1+ (1,0) [0|1] "" Vector__XXX
 SG_ EYE322_5_1_CSTM_ALK_TJA : 41|1@1+ (1,0) [0|1] "" Vector__XXX
 SG_ EYE322_5_2_CSTM_SAS : 42|1@1+ (1,0) [0|1] "" Vector__XXX
 SG_ EYE322_5_3_CSTM_HBA : 43|1@1+ (1,0) [0|1] "" Vector__XXX
 SG_ EYE322_5_4_CSTM_ACC_CONT : 44|1@1+ (1,0) [0|1] "" Vector__XXX
 SG_ EYE322_5_5_CSTM_LANE : 45|1@1+ (1,0) [0|1] "" Vector__XXX
 SG_ EYE322_5_6_LDW_SOUND_OFF_IND : 46|1@1+ (1,0) [0|1] ""  MET
 SG_ EYE322_5_7_CSTM_ELK_SET : 47|1@1+ (1,0) [0|1] "" Vector__XXX
 SG_ EYE322_4_0_CODE_WARN : 32|5@1+ (1,0) [0|31] "" Vector__XXX
 SG_ EYE322_4_5_CSTM_GSR : 37|1@1+ (1,0) [0|1] "" Vector__XXX
 SG_ EYE322_3_0_LANE_L : 24|2@1+ (1,0) [0|3] ""  MET
 SG_ EYE322_3_2_LANE_R : 26|2@1+ (1,0) [0|3] ""  MET
 SG_ EYE322_3_4_LANE_L_COLOR : 28|2@1+ (1,0) [0|3] ""  MET
 SG_ EYE322_3_6_LANE_R_COLOR : 30|2@1+ (1,0) [0|3] ""  MET
 SG_ EYE322_2_0_FCW_OFF_IND : 16|1@1+ (1,0) [0|1] ""  MET
 SG_ EYE322_2_1_MOV_EYESIGHT_SCREEN : 17|1@1+ (1,0) [0|1] ""  MET
 SG_ EYE322_2_2_ALK_ICON : 18|2@1+ (1,0) [0|3] ""  MET
 SG_ EYE322_2_4_INDICATOR_CTRL_REQ : 20|1@1+ (1,0) [0|1] "" Vector__XXX
 SG_ EYE322_2_5_INDICATOR_MODE_R : 21|2@1+ (1,0) [0|3] "" Vector__XXX
 SG_ EYE322_2_7_LIMITER_BACK_SPEED : 23|1@1+ (1,0) [0|1] ""  MET
 SG_ EYE322_1_0_MSG_COUNTER : 8|4@1+ (1,0) [0|15] ""  MET
 SG_ EYE322_1_4_CODE_NO_BUZZER : 12|3@1+ (1,0) [0|7] "" Vector__XXX
 SG_ EYE322_1_7_DISTWARN_DMS : 15|1@1+ (1,0) [0|1] "" Vector__XXX
 SG_ EYE322_0_0_CHECK_SUM : 0|8@1+ (1,0) [0|255] ""  MET

BO_ 801 EYE321: 8 C_ECU_GW
 SG_ EYE321_7_0_INFO_DIST_FORWARD : 56|4@1+ (1,0) [0|15] "" Vector__XXX
 SG_ EYE321_7_4_INFO_KEEP_STOP : 60|1@1+ (1,0) [0|1] ""  MET
 SG_ EYE321_7_5_INFO_READY : 61|1@1+ (1,0) [0|1] ""  MET
 SG_ EYE321_7_6_INFO_SET_CC : 62|1@1+ (1,0) [0|1] "" Vector__XXX
 SG_ EYE321_7_7_INFO_OFF : 63|1@1+ (1,0) [0|1] ""  MET
 SG_ EYE321_6_0_FAIL_EYESIGHT : 48|1@1+ (1,0) [0|1] ""  MET
 SG_ EYE321_6_1_MOV_EYESIGHT_SCREEN : 49|1@1+ (1,0) [0|1] ""  MET
 SG_ EYE321_6_2_IND_VEHICLE : 50|1@1+ (1,0) [0|1] ""  MET
 SG_ EYE321_6_3_BRAKELAMP_VEHICLE : 51|1@1+ (1,0) [0|1] ""  MET
 SG_ EYE321_6_4_IND_FORWARD_VECL : 52|1@1+ (1,0) [0|1] ""  MET
 SG_ EYE321_6_5_BRAKELAMP_FORWARD : 53|1@1+ (1,0) [0|1] "" Vector__XXX
 SG_ EYE321_6_6_CC_OR_LIM_SON : 54|1@1+ (1,0) [0|1] ""  MET
 SG_ EYE321_6_7_TEMP_OFF_STATE : 55|1@1+ (1,0) [0|1] ""  RCR_L
 SG_ EYE321_5_0_INFO_SET_SPD : 40|8@1+ (1,0) [0|255] "km/h or MPH"  MET
 SG_ EYE321_4_0_ACC_MODE : 32|2@1+ (1,0) [0|3] ""  MET
 SG_ EYE321_4_2_SRVD_LASTMEM_ST_REQ : 34|1@1+ (1,0) [0|1] ""  RCR_R,RCR_L
 SG_ EYE321_4_3_INFO_MAIN_CC : 35|2@1+ (1,0) [0|3] ""  MET
 SG_ EYE321_4_5_TRAFFIC_LIGHT : 37|3@1+ (1,0) [0|7] ""  MET
 SG_ EYE321_3_0_CODE_HALT : 24|3@1+ (1,0) [0|7] ""  MET
 SG_ EYE321_3_3_ELK_EQUIP : 27|1@1+ (1,0) [0|1] ""  MET
 SG_ EYE321_3_4_SET_DIST : 28|3@1+ (1,0) [0|7] ""  MET
 SG_ EYE321_3_7_TJA : 31|1@1+ (1,0) [0|1] ""  MET
 SG_ EYE321_2_0_ACC_CANCEL_OR_CSTM : 16|4@1+ (1,0) [0|15] ""  MET
 SG_ EYE321_2_4_ALK_CANCEL_OR_CSTM : 20|3@1+ (1,0) [0|7] ""  MET
 SG_ EYE321_2_7_ALK_CANCEL_DISP_TYPE : 23|1@1+ (1,0) [0|1] ""  MET
 SG_ EYE321_1_0_MSG_COUNTER : 8|4@1+ (1,0) [0|15] ""  RCR_R,RCR_L,MET
 SG_ EYE321_1_4_PRECRASH_BRAKE_OFF : 12|1@1+ (1,0) [0|1] ""  MET
 SG_ EYE321_1_5_LANE_DEPARTURE_OFF : 13|1@1+ (1,0) [0|1] ""  MET
 SG_ EYE321_1_6_MET_AD_DRV_ASS : 14|1@1+ (1,0) [0|1] ""  MET
 SG_ EYE321_1_7_ALC_EQUIP : 15|1@1+ (1,0) [0|1] "" Vector__XXX
 SG_ EYE321_0_0_CHECK_SUM : 0|8@1+ (1,0) [0|255] ""  RCR_R,RCR_L,MET

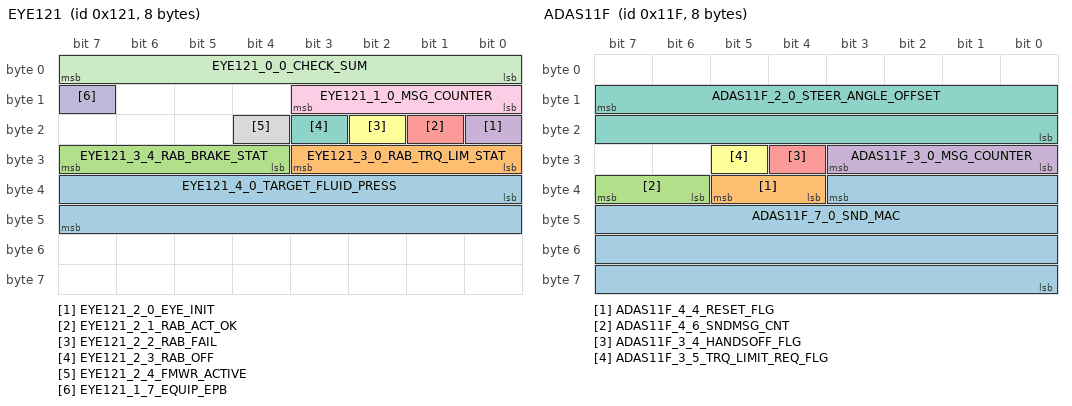
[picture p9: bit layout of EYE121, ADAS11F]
BO_ 289 EYE121: 8 ADAS
 SG_ EYE121_4_0_TARGET_FLUID_PRESS : 32|16@1+ (0.005,0) [0|15] "MPa"  SNR
 SG_ EYE121_3_0_RAB_TRQ_LIM_STAT : 24|4@1+ (1,0) [0|15] ""  SNR
 SG_ EYE121_3_4_RAB_BRAKE_STAT : 28|4@1+ (1,0) [0|15] ""  SNR
 SG_ EYE121_2_0_EYE_INIT : 16|1@1+ (1,0) [0|1] ""  SNR
 SG_ EYE121_2_1_RAB_ACT_OK : 17|1@1+ (1,0) [0|1] ""  SNR
 SG_ EYE121_2_2_RAB_FAIL : 18|1@1+ (1,0) [0|1] ""  SNR
 SG_ EYE121_2_3_RAB_OFF : 19|1@1+ (1,0) [0|1] ""  SNR
 SG_ EYE121_2_4_FMWR_ACTIVE : 20|1@1+ (1,0) [0|1] ""  SNR
 SG_ EYE121_1_0_MSG_COUNTER : 8|4@1+ (1,0) [0|15] ""  SNR
 SG_ EYE121_1_7_EQUIP_EPB : 15|1@1+ (1,0) [0|1] ""  SNR
 SG_ EYE121_0_0_CHECK_SUM : 0|8@1+ (1,0) [0|255] ""  SNR

BO_ 1352 EYE548: 8 ADAS
 SG_ EYE548_7_0_NETWORK_STATUS : 7|64@0+ (1,0) [0|0] ""  C_ECU

BO_ 287 ADAS11F: 8 ADAS
 SG_ ADAS11F_7_0_SND_MAC : 35|28@0+ (1,0) [0|268435455] ""  C_ECU_GW
 SG_ ADAS11F_4_4_RESET_FLG : 37|2@0+ (1,0) [0|3] ""  C_ECU_GW
 SG_ ADAS11F_4_6_SNDMSG_CNT : 39|2@0+ (1,0) [0|3] ""  C_ECU_GW
 SG_ ADAS11F_3_0_MSG_COUNTER : 27|4@0+ (1,0) [0|15] ""  C_ECU_GW
 SG_ ADAS11F_3_4_HANDSOFF_FLG : 28|1@0+ (1,0) [0|1] ""  C_ECU_GW
 SG_ ADAS11F_3_5_TRQ_LIMIT_REQ_FLG : 29|1@0+ (1,0) [0|1] ""  C_ECU_GW
 SG_ ADAS11F_2_0_STEER_ANGLE_OFFSET : 15|16@0- (0.01,0) [-327.67|327.67] "deg"  C_ECU_GW

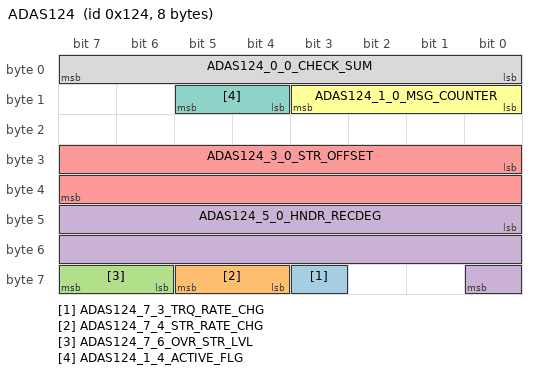
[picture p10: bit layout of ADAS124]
BO_ 292 ADAS124: 8 ADAS
 SG_ ADAS124_7_3_TRQ_RATE_CHG : 59|1@1+ (1,0) [0|1] ""  C_ECU_GW
 SG_ ADAS124_7_4_STR_RATE_CHG : 60|2@1+ (1,0) [0|3] ""  C_ECU_GW
 SG_ ADAS124_7_6_OVR_STR_LVL : 62|2@1+ (1,0) [0|3] ""  C_ECU_GW
 SG_ ADAS124_5_0_HNDR_RECDEG : 40|17@1- (0.01,0) [-655|655] "deg"  C_ECU_GW
 SG_ ADAS124_3_0_STR_OFFSET : 24|16@1- (0.01,0) [-327.67|327.67] "deg"  C_ECU_GW
 SG_ ADAS124_1_0_MSG_COUNTER : 8|4@1+ (1,0) [0|15] ""  C_ECU_GW
 SG_ ADAS124_1_4_ACTIVE_FLG : 12|2@1+ (1,0) [0|3] ""  C_ECU_GW
 SG_ ADAS124_0_0_CHECK_SUM : 0|8@1+ (1,0) [0|255] ""  C_ECU_GW

BO_ 471 MVS1D7: 32 MVS
 SG_ MVS1D7_15_0_Y_CRD4 : 120|8@1- (0.05,0) [-6.4|6.35] "m"  SNR
 SG_ MVS1D7_14_0_X_CRD4 : 112|8@1+ (0.05,0) [0|12.75] "m"  SNR
 SG_ MVS1D7_13_0_UD_CNT4 : 104|2@1+ (1,0) [0|3] ""  SNR
 SG_ MVS1D7_13_2_CAM_LVL4 : 106|2@1+ (1,0) [0|3] ""  SNR
 SG_ MVS1D7_13_4_TRG_ID4 : 108|4@1+ (1,0) [0|15] ""  SNR
 SG_ MVS1D7_12_0_Y_CRD3 : 96|8@1- (0.05,0) [-6.4|6.35] "m"  SNR
 SG_ MVS1D7_11_0_X_CRD3 : 88|8@1+ (0.05,0) [0|12.75] "m"  SNR
 SG_ MVS1D7_10_0_UD_CNT3 : 80|2@1+ (1,0) [0|3] ""  SNR
 SG_ MVS1D7_10_2_CAM_LVL3 : 82|2@1+ (1,0) [0|3] ""  SNR
 SG_ MVS1D7_10_4_TRG_ID3 : 84|4@1+ (1,0) [0|15] ""  SNR
 SG_ MVS1D7_8_0_Y_CRD2 : 64|8@1- (0.05,0) [-6.4|6.35] "m"  SNR
 SG_ MVS1D7_7_0_X_CRD2 : 56|8@1+ (0.05,0) [0|12.75] "m"  SNR
 SG_ MVS1D7_6_0_UD_CNT2 : 48|2@1+ (1,0) [0|3] ""  SNR
 SG_ MVS1D7_6_2_CAM_LVL2 : 50|2@1+ (1,0) [0|3] ""  SNR
 SG_ MVS1D7_6_4_TRG_ID2 : 52|4@1+ (1,0) [0|15] ""  SNR
 SG_ MVS1D7_5_0_Y_CRD1 : 40|8@1- (0.05,0) [-6.4|6.35] "m"  SNR
 SG_ MVS1D7_4_0_X_CRD1 : 32|8@1+ (0.05,0) [0|12.75] "m"  SNR
 SG_ MVS1D7_3_0_UD_CNT1 : 24|2@1+ (1,0) [0|3] ""  SNR
 SG_ MVS1D7_3_2_CAM_LVL1 : 26|2@1+ (1,0) [0|3] ""  SNR
 SG_ MVS1D7_3_4_TRG_ID1 : 28|4@1+ (1,0) [0|15] ""  SNR
 SG_ MVS1D7_2_0_E2E_COUNTER : 16|8@1+ (1,0) [0|255] ""  SNR
 SG_ MVS1D7_0_0_E2E_CRC : 0|16@1+ (1,0) [0|65535] ""  SNR

BO_ 470 MVS1D6: 32 MVS
 SG_ MVS1D6_16_4_CMDHALT : 132|2@1+ (1,0) [0|3] ""  SNR
 SG_ MVS1D6_16_6_CMDFAIL : 134|2@1+ (1,0) [0|3] ""  SNR
 SG_ MVS1D6_15_0_Y_CRD4 : 120|8@1- (0.05,0) [-6.4|6.35] "m"  SNR
 SG_ MVS1D6_14_0_X_CRD4 : 112|8@1+ (0.05,0) [0|12.75] "m"  SNR
 SG_ MVS1D6_13_0_UD_CNT4 : 104|2@1+ (1,0) [0|3] ""  SNR
 SG_ MVS1D6_13_2_CAM_LVL4 : 106|2@1+ (1,0) [0|3] ""  SNR
 SG_ MVS1D6_13_4_TRG_ID4 : 108|4@1+ (1,0) [0|15] ""  SNR
 SG_ MVS1D6_12_0_Y_CRD3 : 96|8@1- (0.05,0) [-6.4|6.35] "m"  SNR
 SG_ MVS1D6_11_0_X_CRD3 : 88|8@1+ (0.05,0) [0|12.75] "m"  SNR
 SG_ MVS1D6_10_0_UD_CNT3 : 80|2@1+ (1,0) [0|3] ""  SNR
 SG_ MVS1D6_10_2_CAM_LVL3 : 82|2@1+ (1,0) [0|3] ""  SNR
 SG_ MVS1D6_10_4_TRG_ID3 : 84|4@1+ (1,0) [0|15] ""  SNR
 SG_ MVS1D6_8_0_Y_CRD2 : 64|8@1- (0.05,0) [-6.4|6.35] "m"  SNR
 SG_ MVS1D6_7_0_X_CRD2 : 56|8@1+ (0.05,0) [0|12.75] "m"  SNR
 SG_ MVS1D6_6_0_UD_CNT2 : 48|2@1+ (1,0) [0|3] ""  SNR
 SG_ MVS1D6_6_2_CAM_LVL2 : 50|2@1+ (1,0) [0|3] ""  SNR
 SG_ MVS1D6_6_4_TRG_ID2 : 52|4@1+ (1,0) [0|15] ""  SNR
 SG_ MVS1D6_5_0_Y_CRD1 : 40|8@1- (0.05,0) [-6.4|6.35] "m"  SNR
 SG_ MVS1D6_4_0_X_CRD1 : 32|8@1+ (0.05,0) [0|12.75] "m"  SNR
 SG_ MVS1D6_3_0_UD_CNT1 : 24|2@1+ (1,0) [0|3] ""  SNR
 SG_ MVS1D6_3_2_CAM_LVL1 : 26|2@1+ (1,0) [0|3] ""  SNR
 SG_ MVS1D6_3_4_TRG_ID1 : 28|4@1+ (1,0) [0|15] ""  SNR
 SG_ MVS1D6_2_0_E2E_COUNTER : 16|8@1+ (1,0) [0|255] ""  SNR
 SG_ MVS1D6_0_0_E2E_CRC : 0|16@1+ (1,0) [0|65535] ""  SNR

BO_ 279 SNR117: 32 SNR
 SG_ SNR117_16_0_CSTM_SNR_DSPREEQ : 128|2@1+ (1,0) [0|3] ""  ADAS,C_ECU_GW
 SG_ SNR117_16_2_CSTM_RAB_DSPREQ : 130|2@1+ (1,0) [0|3] ""  ADAS,C_ECU_GW
 SG_ SNR117_16_4_CSTM_PED_DSPREQ : 132|2@1+ (1,0) [0|3] ""  ADAS,C_ECU_GW
 SG_ SNR117_16_6_CSTM_PEDTIM_DSPREQ : 134|2@1+ (1,0) [0|3] ""  ADAS,C_ECU_GW
 SG_ SNR117_15_0_CSTM_SNR_CLEAR : 120|1@1+ (1,0) [0|1] ""  ADAS,C_ECU_GW
 SG_ SNR117_15_1_CSTM_RAB : 121|1@1+ (1,0) [0|1] ""  ADAS,C_ECU_GW
 SG_ SNR117_15_2_CSTM_RAB_PED : 122|1@1+ (1,0) [0|1] ""  ADAS,C_ECU_GW
 SG_ SNR117_15_3_CSTM_RAB_PED_TIMING : 123|2@1+ (1,0) [0|3] ""  ADAS,C_ECU_GW
 SG_ SNR117_14_0_RAB_WARNING : 112|3@1+ (1,0) [0|7] ""  ADAS,C_ECU_GW
 SG_ SNR117_14_3_SONAR_LEVEL : 115|5@1+ (1,0) [0|8] ""  ADAS,C_ECU_GW
 SG_ SNR117_13_0_PED_WARN_CENTER : 104|1@1+ (1,0) [0|1] ""  ADAS,C_ECU_GW
 SG_ SNR117_13_1_PED_WARN_LEFT : 105|1@1+ (1,0) [0|1] ""  ADAS,C_ECU_GW
 SG_ SNR117_13_2_PED_WARN_RIGHT : 106|1@1+ (1,0) [0|1] ""  ADAS,C_ECU_GW
 SG_ SNR117_13_3_RAB_TRIG_TYPE : 107|2@1+ (1,0) [0|3] ""  ADAS,C_ECU_GW
 SG_ SNR117_13_4_RAB_TRIG_TYPE : 108|1@1+ (1,0) [0|0] ""  MVS,C_ECU_GW
 SG_ SNR117_9_0_SONAR_R_R_CORNER_4LV : 72|3@1+ (1,0) [0|7] ""  ADAS,C_ECU_GW
 SG_ SNR117_8_0_SONAR_DISP_INT : 64|1@1+ (1,0) [0|1] ""  ADAS,C_ECU_GW
 SG_ SNR117_8_1_SONAR_R_CENTER : 65|3@1+ (1,0) [0|7] ""  ADAS,C_ECU_GW
 SG_ SNR117_8_4_SONAR_R_L_CORNER_4LV : 68|3@1+ (1,0) [0|7] ""  ADAS,C_ECU_GW
 SG_ SNR117_7_0_SONAR_SYS_FAIL : 56|2@1+ (1,0) [0|3] ""  ADAS,C_ECU_GW
 SG_ SNR117_7_2_RAB_HALT : 58|2@1+ (1,0) [0|3] ""  ADAS,C_ECU_GW
 SG_ SNR117_7_4_CAMERA_FAIL : 60|2@1+ (1,0) [0|3] ""  ADAS,C_ECU_GW
 SG_ SNR117_7_6_RAB_PED_HALT : 62|2@1+ (1,0) [0|3] ""  ADAS,C_ECU_GW
 SG_ SNR117_6_0_REQ_ACT_EPB : 48|1@1+ (1,0) [0|1] ""  ADAS,C_ECU_GW
 SG_ SNR117_6_1_STOP_HOJI_BUZ_ACT : 49|1@1+ (1,0) [0|1] ""  ADAS,C_ECU_GW
 SG_ SNR117_6_2_RAB_OFF : 50|1@1+ (1,0) [0|1] ""  ADAS,C_ECU_GW
 SG_ SNR117_6_3_SONAR_OFF : 51|1@1+ (1,0) [0|1] ""  ADAS,C_ECU_GW
 SG_ SNR117_6_4_RAB_PED_OFF : 52|1@1+ (1,0) [0|1] ""  ADAS,C_ECU_GW
 SG_ SNR117_6_5_SONAR_HALT : 53|2@1+ (1,0) [0|3] ""  ADAS,C_ECU_GW
 SG_ SNR117_5_0_YOATSU_ACT : 40|1@1+ (1,0) [0|1] ""  ADAS,C_ECU_GW
 SG_ SNR117_5_1_TORQUE_LIM_ACT : 41|1@1+ (1,0) [0|1] ""  ADAS,C_ECU_GW
 SG_ SNR117_5_2_TORQUE_LIM_VAL : 42|6@1+ (0.01,0) [0|0.63] "G"  ADAS,C_ECU_GW
 SG_ SNR117_4_0_RAB_ACT : 32|1@1+ (1,0) [0|1] ""  ADAS,C_ECU_GW
 SG_ SNR117_4_1_RAB_VAL : 33|7@1+ (0.01,0) [0|1.27] "G"  ADAS,C_ECU_GW
 SG_ SNR117_3_0_RAB : 24|1@1+ (1,0) [0|1] ""  ADAS,C_ECU_GW
 SG_ SNR117_3_1_RAB_PED : 25|1@1+ (1,0) [0|1] ""  ADAS,C_ECU_GW
 SG_ SNR117_2_0_E2E_COUNTER : 16|8@1+ (1,0) [0|255] ""  MVS,ADAS,C_ECU_GW
 SG_ SNR117_0_0_E2E_CRC : 0|16@1+ (1,0) [0|65535] ""  MVS,ADAS,C_ECU_GW

BO_ 845 ADAS34D: 32 ADAS
 SG_ ADAS34D_16_0_CSTM_SNR_DSPREEQ : 128|2@1+ (1,0) [0|3] ""  C_ECU_GW
 SG_ ADAS34D_16_2_CSTM_RAB_DSPREQ : 130|2@1+ (1,0) [0|3] ""  C_ECU_GW
 SG_ ADAS34D_16_4_CSTM_PED_DSPREQ : 132|2@1+ (1,0) [0|3] ""  C_ECU_GW
 SG_ ADAS34D_16_6_CSTM_PEDTIM_DSPREQ : 134|2@1+ (1,0) [0|3] ""  C_ECU_GW
 SG_ ADAS34D_15_0_CSTM_SNR_CLEAR : 120|1@1+ (1,0) [0|1] ""  C_ECU_GW
 SG_ ADAS34D_15_1_CSTM_RAB : 121|1@1+ (1,0) [0|1] ""  C_ECU_GW
 SG_ ADAS34D_15_2_CSTM_RAB_PED : 122|1@1+ (1,0) [0|1] ""  C_ECU_GW
 SG_ ADAS34D_15_3_CSTM_RAB_PED_TIMING : 123|2@1+ (1,0) [0|3] ""  C_ECU_GW
 SG_ ADAS34D_15_5_CSTM_TEMP_OFF : 125|2@1+ (1,0) [0|3] ""  C_ECU_GW
 SG_ ADAS34D_15_7_TEMP_OFF_STATE : 127|1@1+ (1,0) [0|1] ""  C_ECU_GW
 SG_ ADAS34D_14_0_RAB_WARNING : 112|3@1+ (1,0) [0|7] ""  C_ECU_GW
 SG_ ADAS34D_14_3_SONAR_LEVEL : 115|5@1+ (1,0) [0|8] ""  C_ECU_GW
 SG_ ADAS34D_13_0_PED_WARN_CENTER : 104|1@1+ (1,0) [0|1] ""  MVS,C_ECU_GW
 SG_ ADAS34D_13_1_PED_WARN_LEFT : 105|1@1+ (1,0) [0|1] ""  MVS,C_ECU_GW
 SG_ ADAS34D_13_2_PED_WARN_RIGHT : 106|1@1+ (1,0) [0|1] ""  MVS,C_ECU_GW
 SG_ ADAS34D_13_3_RAB_TRIG_TYPE : 107|2@1+ (1,0) [0|3] ""  C_ECU_GW
 SG_ ADAS34D_9_0_SONAR_R_R_CORNER_4LV : 72|3@1+ (1,0) [0|7] ""  MVS,C_ECU_GW
 SG_ ADAS34D_8_0_SONAR_DISP_INT : 64|1@1+ (1,0) [0|1] ""  C_ECU_GW
 SG_ ADAS34D_8_1_SONAR_R_CENTER : 65|3@1+ (1,0) [0|7] ""  MVS,C_ECU_GW
 SG_ ADAS34D_8_4_SONAR_R_L_CORNER_4LV : 68|3@1+ (1,0) [0|7] ""  MVS,C_ECU_GW
 SG_ ADAS34D_7_0_SONAR_SYS_FAIL : 56|2@1+ (1,0) [0|3] ""  C_ECU_GW
 SG_ ADAS34D_7_2_RAB_HALT : 58|2@1+ (1,0) [0|3] ""  C_ECU_GW
 SG_ ADAS34D_7_4_CAMERA_FAIL : 60|2@1+ (1,0) [0|3] ""  C_ECU_GW
 SG_ ADAS34D_7_6_RAB_PED_HALT : 62|2@1+ (1,0) [0|3] ""  C_ECU_GW
 SG_ ADAS34D_6_0_REQ_ACT_EPB : 48|1@1+ (1,0) [0|1] ""  C_ECU_GW
 SG_ ADAS34D_6_1_STOP_HOJI_BUZ_ACT : 49|1@1+ (1,0) [0|1] ""  C_ECU_GW
 SG_ ADAS34D_6_2_RAB_OFF : 50|1@1+ (1,0) [0|1] ""  C_ECU_GW
 SG_ ADAS34D_6_3_SONAR_OFF : 51|1@1+ (1,0) [0|1] ""  C_ECU_GW
 SG_ ADAS34D_6_4_RAB_PED_OFF : 52|1@1+ (1,0) [0|1] ""  C_ECU_GW
 SG_ ADAS34D_6_5_SONAR_HALT : 53|2@1+ (1,0) [0|3] ""  C_ECU_GW
 SG_ ADAS34D_5_0_YOATSU_ACT : 40|1@1+ (1,0) [0|1] ""  C_ECU_GW
 SG_ ADAS34D_5_1_TORQUE_LIM_ACT : 41|1@1+ (1,0) [0|1] ""  C_ECU_GW
 SG_ ADAS34D_5_2_TORQUE_LIM_VAL : 42|6@1+ (0.01,0) [0|0.63] "G"  C_ECU_GW
 SG_ ADAS34D_4_0_RAB_ACT : 32|1@1+ (1,0) [0|1] ""  C_ECU_GW
 SG_ ADAS34D_4_1_RAB_VAL : 33|7@1+ (0.01,0) [0|1.27] "G"  C_ECU_GW
 SG_ ADAS34D_3_0_RAB : 24|1@1+ (1,0) [0|1] ""  MET,C_ECU_GW
 SG_ ADAS34D_3_1_RAB_PED : 25|1@1+ (1,0) [0|1] ""  MET,C_ECU_GW
 SG_ ADAS34D_2_0_E2E_COUNTER : 16|8@1+ (1,0) [0|255] ""  MVS,MET,C_ECU_GW
 SG_ ADAS34D_0_0_E2E_CRC : 0|16@1+ (1,0) [0|65535] ""  MVS,MET,C_ECU_GW

BO_ 844 ADAS34C: 32 ADAS
 SG_ ADAS34C_25_0_CSTM_ADDON_DISP_CNT : 200|1@1+ (1,0) [0|1] ""  C_ECU_GW
 SG_ ADAS34C_25_1_CSTM_LANE_SET_CONT : 201|1@1+ (1,0) [0|1] ""  C_ECU_GW
 SG_ ADAS34C_24_0_CSTM_LSW : 192|1@1+ (1,0) [0|1] ""  C_ECU_GW
 SG_ ADAS34C_24_1_CSTM_GREEN_LIGHT : 193|1@1+ (1,0) [0|1] ""  C_ECU_GW
 SG_ ADAS34C_24_2_CSTM_LANE_SET : 194|1@1+ (1,0) [0|1] ""  C_ECU_GW
 SG_ ADAS34C_24_3_CSTM_PROPOSAL_HMI : 195|1@1+ (1,0) [0|1] ""  C_ECU_GW
 SG_ ADAS34C_24_4_CSTM_V2N : 196|1@1+ (1,0) [0|1] ""  C_ECU_GW
 SG_ ADAS34C_24_5_CSTM_DATA_COLLECT : 197|1@1+ (1,0) [0|1] ""  C_ECU_GW
 SG_ ADAS34C_24_6_CSTM_COLLECT_IMAGE : 198|1@1+ (1,0) [0|1] ""  C_ECU_GW
 SG_ ADAS34C_24_7_CSTM_COLLECT_LOC : 199|1@1+ (1,0) [0|1] ""  C_ECU_GW
 SG_ ADAS34C_22_0_DATA_COLLECT_DISP : 176|2@1+ (1,0) [0|3] ""  C_ECU_GW
 SG_ ADAS34C_22_2_COLLECT_IMAGE_DISP : 178|2@1+ (1,0) [0|3] ""  C_ECU_GW
 SG_ ADAS34C_22_4_COLLECT_LOC_DISP : 180|2@1+ (1,0) [0|3] ""  C_ECU_GW
 SG_ ADAS34C_21_0_LSW_DISP_CONT : 168|2@1+ (1,0) [0|3] ""  C_ECU_GW
 SG_ ADAS34C_21_2_GREEN_LIGHT_DISP : 170|2@1+ (1,0) [0|3] ""  C_ECU_GW
 SG_ ADAS34C_21_4_LANE_SET_DISP_CONT : 172|2@1+ (1,0) [0|3] ""  C_ECU_GW
 SG_ ADAS34C_21_6_PROPOSAL_HMI_DISP : 174|2@1+ (1,0) [0|3] ""  C_ECU_GW
 SG_ ADAS34C_20_0_ADD_ON_DISP_CONT : 160|2@1+ (1,0) [0|3] ""  C_ECU_GW
 SG_ ADAS34C_20_2_V2N_DISP_CONT : 162|2@1+ (1,0) [0|3] ""  C_ECU_GW
 SG_ ADAS34C_20_4_LANE_SET_PTN_DISP : 164|2@1+ (1,0) [0|3] ""  C_ECU_GW
 SG_ ADAS34C_18_0_CSTM_SUPPRESS_SPEED : 144|1@1+ (1,0) [0|1] ""  C_ECU_GW
 SG_ ADAS34C_18_1_SUPPRESS_SPD_LEVEL : 145|2@1+ (1,0) [0|3] ""  C_ECU_GW
 SG_ ADAS34C_18_3_ACTIVE_AVOIDANCE : 147|1@1+ (1,0) [0|1] ""  C_ECU_GW
 SG_ ADAS34C_18_4_ACTIVE_AVOIDANCE_LV : 148|2@1+ (1,0) [0|3] ""  C_ECU_GW
 SG_ ADAS34C_17_0_CSTM_PDA_CURR : 136|1@1+ (1,0) [0|1] ""  C_ECU_GW
 SG_ ADAS34C_17_1_TARGET_VEHICLE : 137|1@1+ (1,0) [0|1] ""  C_ECU_GW
 SG_ ADAS34C_17_2_TARGET_SURROUNDING : 138|1@1+ (1,0) [0|1] ""  C_ECU_GW
 SG_ ADAS34C_17_3_TARGET_SLOPE_DOWN : 139|1@1+ (1,0) [0|1] ""  C_ECU_GW
 SG_ ADAS34C_17_4_CUS_SUPPRESS_SPDTGT : 140|1@1+ (1,0) [0|1] ""  C_ECU_GW
 SG_ ADAS34C_15_0_A_AVOIDANCE_DISP : 120|2@1+ (1,0) [0|3] ""  C_ECU_GW
 SG_ ADAS34C_15_2_A_AVOIDANCE_LV_DISP : 122|2@1+ (1,0) [0|3] ""  C_ECU_GW
 SG_ ADAS34C_15_4_A_AVOIDANCE_LV_PTN : 124|2@1+ (1,0) [0|3] ""  C_ECU_GW
 SG_ ADAS34C_14_0_SUPPRESS_SPDTGT_DSP : 112|2@1+ (1,0) [0|3] ""  C_ECU_GW
 SG_ ADAS34C_14_2_TARGET_VEHICLE_DISP : 114|2@1+ (1,0) [0|3] ""  C_ECU_GW
 SG_ ADAS34C_14_4_TARGET_SURROUND_DSP : 116|2@1+ (1,0) [0|3] ""  C_ECU_GW
 SG_ ADAS34C_14_6_TGT_SLOPE_DOWN_DSP : 118|2@1+ (1,0) [0|3] ""  C_ECU_GW
 SG_ ADAS34C_13_0_PDA_DISP_CONT : 104|2@1+ (1,0) [0|3] ""  C_ECU_GW
 SG_ ADAS34C_13_2_SUPPRESS_SPD_DISP : 106|2@1+ (1,0) [0|3] ""  C_ECU_GW
 SG_ ADAS34C_13_4_SUPPRESS_SPDLV_DISP : 108|2@1+ (1,0) [0|3] ""  C_ECU_GW
 SG_ ADAS34C_13_6_SUPPRESS_SPD_LV_PTN : 110|2@1+ (1,0) [0|3] ""  C_ECU_GW
 SG_ ADAS34C_11_0_ISA_OFS_U50_DISP : 88|2@1+ (1,0) [0|3] ""  C_ECU_GW
 SG_ ADAS34C_11_2_ISA_OFS_OV50_DISP : 90|2@1+ (1,0) [0|3] ""  C_ECU_GW
 SG_ ADAS34C_10_0_SLWF_OFFSET_OV50 : 80|5@1+ (1,0) [0|31] ""  C_ECU_GW
 SG_ ADAS34C_9_0_SLWF_OFFSET_U50 : 72|5@1+ (1,0) [0|31] ""  C_ECU_GW
 SG_ ADAS34C_9_5_CSTM_SLWF : 77|1@1+ (1,0) [0|1] ""  C_ECU_GW
 SG_ ADAS34C_9_6_CSTM_SLWF_OFS_CONT : 78|1@1+ (1,0) [0|1] ""  C_ECU_GW
 SG_ ADAS34C_9_7_ISA_IACC_OFS_CONT : 79|1@1+ (1,0) [0|1] ""  C_ECU_GW
 SG_ ADAS34C_8_0_ISA_IACC_OFFSET_OV50 : 64|5@1+ (1,0) [0|31] ""  C_ECU_GW
 SG_ ADAS34C_8_5_SIGN_SWITCH_SOUND : 69|1@1+ (1,0) [0|1] ""  C_ECU_GW
 SG_ ADAS34C_8_6_CSTM_LOADSIGNS_SYS : 70|1@1+ (1,0) [0|1] ""  C_ECU_GW
 SG_ ADAS34C_8_7_CSTM_ISA_IACC_CONT : 71|1@1+ (1,0) [0|1] ""  C_ECU_GW
 SG_ ADAS34C_7_0_ISA_IACC_OFFSET_U50 : 56|5@1+ (1,0) [0|31] ""  C_ECU_GW
 SG_ ADAS34C_7_5_CSTM_LOADSIGNS_ADD : 61|1@1+ (1,0) [0|1] ""  C_ECU_GW
 SG_ ADAS34C_7_6_CSTM_ISA_IACC_ACCEPT : 62|2@1+ (1,0) [0|3] ""  C_ECU_GW
 SG_ ADAS34C_6_0_ISA_IACC_PTN_DISP : 48|2@1+ (1,0) [0|3] ""  C_ECU_GW
 SG_ ADAS34C_6_2_SLWF_OFS_U50_DISP : 50|2@1+ (1,0) [0|3] ""  C_ECU_GW
 SG_ ADAS34C_6_4_SLWF_OFS_OV50_DISP : 52|2@1+ (1,0) [0|3] ""  C_ECU_GW
 SG_ ADAS34C_5_0_SLWF_DISP_CONT : 40|2@1+ (1,0) [0|3] ""  C_ECU_GW
 SG_ ADAS34C_5_2_ISA_IACC_OFSET_DISP : 42|2@1+ (1,0) [0|3] ""  C_ECU_GW
 SG_ ADAS34C_5_4_SLWF_OFSET_DISP : 44|2@1+ (1,0) [0|3] ""  C_ECU_GW
 SG_ ADAS34C_5_6_SIGNSWITCH_SND_DISP : 46|2@1+ (1,0) [0|3] ""  C_ECU_GW
 SG_ ADAS34C_4_0_LOADSIGN_DISP_CONT : 32|2@1+ (1,0) [0|3] ""  C_ECU_GW
 SG_ ADAS34C_4_2_LOADSIGN_ADD_DISP : 34|2@1+ (1,0) [0|3] ""  C_ECU_GW
 SG_ ADAS34C_4_4_ISA_IACC_ACCEPT_DISP : 36|2@1+ (1,0) [0|3] ""  C_ECU_GW
 SG_ ADAS34C_4_6_ISA_IACC_ACCEPT_PTN : 38|2@1+ (1,0) [0|3] ""  C_ECU_GW
 SG_ ADAS34C_3_0_EYE_VALID : 24|1@1+ (1,0) [0|1] ""  C_ECU_GW
 SG_ ADAS34C_2_0_E2E_COUNTER : 16|8@1+ (1,0) [0|255] ""  C_ECU_GW
 SG_ ADAS34C_0_0_E2E_CRC : 0|16@1+ (1,0) [0|65535] ""  C_ECU_GW

BO_ 843 ADAS34B: 32 ADAS
 SG_ ADAS34B_31_0_CSTM_ACC_FUNC_CONT : 248|1@1+ (1,0) [0|1] ""  C_ECU_GW
 SG_ ADAS34B_30_0_CSTM_ACC_CONT_SET : 240|2@1+ (1,0) [0|3] ""  C_ECU_GW
 SG_ ADAS34B_30_2_CSTM_ACC_OVERTAKE : 242|1@1+ (1,0) [0|1] ""  C_ECU_GW
 SG_ ADAS34B_30_3_CSTM_ACC_TARGET_OPT : 243|1@1+ (1,0) [0|1] ""  C_ECU_GW
 SG_ ADAS34B_30_4_CSTM_ACC_STOP_CONT : 244|1@1+ (1,0) [0|1] ""  C_ECU_GW
 SG_ ADAS34B_30_5_CSTM_ACC_SLOWDOWN : 245|1@1+ (1,0) [0|1] ""  C_ECU_GW
 SG_ ADAS34B_30_6_CSTM_ACC_HIGHWAY : 246|1@1+ (1,0) [0|1] ""  C_ECU_GW
 SG_ ADAS34B_30_7_CSTM_ACC_SYS : 247|1@1+ (1,0) [0|1] ""  C_ECU_GW
 SG_ ADAS34B_28_0_ACC_TARGET_OPT_DISP : 224|2@1+ (1,0) [0|3] ""  C_ECU_GW
 SG_ ADAS34B_28_2_ACC_STOP_DISP : 226|2@1+ (1,0) [0|3] ""  C_ECU_GW
 SG_ ADAS34B_28_4_ACC_SLOWDOWN_DISP : 228|2@1+ (1,0) [0|3] ""  C_ECU_GW
 SG_ ADAS34B_28_6_ACC_HIGHWAY_DISP : 230|2@1+ (1,0) [0|3] ""  C_ECU_GW
 SG_ ADAS34B_27_0_ACC_DISP_CONT : 216|2@1+ (1,0) [0|3] ""  C_ECU_GW
 SG_ ADAS34B_27_2_ACC_LEVEL_DISP_CONT : 218|2@1+ (1,0) [0|3] ""  C_ECU_GW
 SG_ ADAS34B_27_4_ACC_OVERTAKE_DISP : 220|2@1+ (1,0) [0|3] ""  C_ECU_GW
 SG_ ADAS34B_27_6_ACC_LEVEL_PTN_DISP : 222|2@1+ (1,0) [0|3] ""  C_ECU_GW
 SG_ ADAS34B_25_0_CSTM_ACTIVE_LKS : 200|1@1+ (1,0) [0|1] ""  C_ECU_GW
 SG_ ADAS34B_25_1_CSTM_A_LKS_AUTOPASS : 201|1@1+ (1,0) [0|1] ""  C_ECU_GW
 SG_ ADAS34B_25_2_CSTM_A_LKS_NAVI : 202|1@1+ (1,0) [0|1] ""  C_ECU_GW
 SG_ ADAS34B_25_3_CSTM_A_LKS_OFFSET : 203|1@1+ (1,0) [0|1] ""  C_ECU_GW
 SG_ ADAS34B_25_4_CSTM_A_LKS_OPT_CONT : 204|1@1+ (1,0) [0|1] ""  C_ECU_GW
 SG_ ADAS34B_23_0_A_LKS_OPTION_DISP : 184|2@1+ (1,0) [0|3] ""  C_ECU_GW
 SG_ ADAS34B_23_2_A_LKS_AUTOPASS_DISP : 186|2@1+ (1,0) [0|3] ""  C_ECU_GW
 SG_ ADAS34B_23_4_A_LKS_NAVI_DISP : 188|2@1+ (1,0) [0|3] ""  C_ECU_GW
 SG_ ADAS34B_23_6_A_LKS_OFFSET_DISP : 190|2@1+ (1,0) [0|3] ""  C_ECU_GW
 SG_ ADAS34B_22_0_ACTIVE_LKS_DISP : 176|2@1+ (1,0) [0|3] ""  C_ECU_GW
 SG_ ADAS34B_21_0_CSTM_LDW_TMG_CNT : 168|1@1+ (1,0) [0|1] ""  C_ECU_GW
 SG_ ADAS34B_21_1_CSTM_LDPTARGET_CONT : 169|1@1+ (1,0) [0|1] ""  C_ECU_GW
 SG_ ADAS34B_21_2_ELK_ASSISTTYPE_CONT : 170|1@1+ (1,0) [0|1] ""  C_ECU_GW
 SG_ ADAS34B_20_0_CSTM_ELK : 160|1@1+ (1,0) [0|1] ""  C_ECU_GW
 SG_ ADAS34B_20_1_CSTM_ELK_SOUND : 161|1@1+ (1,0) [0|1] ""  C_ECU_GW
 SG_ ADAS34B_20_2_CSTM_ELK_VIB : 162|1@1+ (1,0) [0|1] ""  C_ECU_GW
 SG_ ADAS34B_20_3_CSTM_ELK_CTRL : 163|1@1+ (1,0) [0|1] ""  C_ECU_GW
 SG_ ADAS34B_20_4_CSTM_LDW_TIMING : 164|2@1+ (1,0) [0|3] ""  C_ECU_GW
 SG_ ADAS34B_20_6_LDW_SOUND_ON_OFF_SW : 166|1@1+ (1,0) [0|1] ""  C_ECU_GW
 SG_ ADAS34B_20_7_CSTM_LD_ASSISTTYPE : 167|1@1+ (1,0) [0|1] ""  C_ECU_GW
 SG_ ADAS34B_19_0_CSTM_LANE_DEPARTURE : 152|1@1+ (1,0) [0|1] ""  C_ECU_GW
 SG_ ADAS34B_19_1_CSTM_LDW_SOUND : 153|1@1+ (1,0) [0|1] ""  C_ECU_GW
 SG_ ADAS34B_19_2_CSTM_LDW_VIB : 154|1@1+ (1,0) [0|1] ""  C_ECU_GW
 SG_ ADAS34B_19_3_CSTM_LDP : 155|1@1+ (1,0) [0|1] ""  C_ECU_GW
 SG_ ADAS34B_19_4_LDP_TGT_SOLIDLINE : 156|1@1+ (1,0) [0|1] ""  C_ECU_GW
 SG_ ADAS34B_19_5_LDP_TGT_DASHLINE : 157|1@1+ (1,0) [0|1] ""  C_ECU_GW
 SG_ ADAS34B_19_6_LDP_TGT_SIDE_OBJ : 158|1@1+ (1,0) [0|1] ""  C_ECU_GW
 SG_ ADAS34B_19_7_LDP_TGT_SIDE_VHCL : 159|1@1+ (1,0) [0|1] ""  C_ECU_GW
 SG_ ADAS34B_17_0_ELK_ASSISTTYPE_DISP : 136|2@1+ (1,0) [0|3] ""  C_ECU_GW
 SG_ ADAS34B_17_2_ELK_SOUND_DISP_CONT : 138|2@1+ (1,0) [0|3] ""  C_ECU_GW
 SG_ ADAS34B_17_4_ELK_VIB_DISP_CONT : 140|2@1+ (1,0) [0|3] ""  C_ECU_GW
 SG_ ADAS34B_17_6_ELK_CTRL_DISP_CONT : 142|2@1+ (1,0) [0|3] ""  C_ECU_GW
 SG_ ADAS34B_16_0_LDW_TIMING_DISP : 128|2@1+ (1,0) [0|3] ""  C_ECU_GW
 SG_ ADAS34B_16_2_LDW_TIMING_PTN : 130|3@1+ (1,0) [0|7] ""  C_ECU_GW
 SG_ ADAS34B_16_6_LDW_TIMING_PTN_DISP : 134|2@1+ (1,0) [0|3] ""  C_ECU_GW
 SG_ ADAS34B_15_0_TGT_SOLIDLINE_DISP : 120|2@1+ (1,0) [0|3] ""  C_ECU_GW
 SG_ ADAS34B_15_2_TGT_DASHLINE_DISP : 122|2@1+ (1,0) [0|3] ""  C_ECU_GW
 SG_ ADAS34B_15_4_TGT_SIDE_OBJ_DISP : 124|2@1+ (1,0) [0|3] ""  C_ECU_GW
 SG_ ADAS34B_15_6_TGT_SIDE_VHCL_DISP : 126|2@1+ (1,0) [0|3] ""  C_ECU_GW
 SG_ ADAS34B_14_0_LD_ASSISTTYPE_DISP : 112|2@1+ (1,0) [0|3] ""  C_ECU_GW
 SG_ ADAS34B_14_2_LDW_SOUND_DISP_CONT : 114|2@1+ (1,0) [0|3] ""  C_ECU_GW
 SG_ ADAS34B_14_4_LDW_VIB_DISP_CONT : 116|2@1+ (1,0) [0|3] ""  C_ECU_GW
 SG_ ADAS34B_14_6_LDP_DISP_CONT : 118|2@1+ (1,0) [0|3] ""  C_ECU_GW
 SG_ ADAS34B_13_0_LANE_DEPARTURE_DISP : 104|2@1+ (1,0) [0|3] ""  C_ECU_GW
 SG_ ADAS34B_13_2_LDPTARGET_DISP_CONT : 106|2@1+ (1,0) [0|3] ""  C_ECU_GW
 SG_ ADAS34B_13_4_LDW_SOUND_SW_DISP : 108|2@1+ (1,0) [0|3] ""  C_ECU_GW
 SG_ ADAS34B_13_6_ELK_DISP_CONT : 110|2@1+ (1,0) [0|3] ""  C_ECU_GW
 SG_ ADAS34B_11_0_CSTM_MIS_AT_BACK : 88|1@1+ (1,0) [0|1] ""  C_ECU_GW
 SG_ ADAS34B_11_1_MIS_AT_BACK_SPD_LIM : 89|2@1+ (1,0) [0|3] ""  C_ECU_GW
 SG_ ADAS34B_11_3_CSTM_FCW_TYPE_CONT : 91|1@1+ (1,0) [0|1] ""  C_ECU_GW
 SG_ ADAS34B_11_4_FCTI_NOTICE_CONT : 92|1@1+ (1,0) [0|1] ""  C_ECU_GW
 SG_ ADAS34B_11_5_CSTM_SAFTY_MOD_SENS : 93|1@1+ (1,0) [0|1] ""  C_ECU_GW
 SG_ ADAS34B_11_6_MIS_AT_BACK_CONT : 94|1@1+ (1,0) [0|1] ""  C_ECU_GW
 SG_ ADAS34B_10_0_CSTM_FCTI_CONT : 80|1@1+ (1,0) [0|1] ""  C_ECU_GW
 SG_ ADAS34B_10_1_CSTM_FCTI_SOUND : 81|1@1+ (1,0) [0|1] ""  C_ECU_GW
 SG_ ADAS34B_10_2_CSTM_FCTI_PULSE : 82|1@1+ (1,0) [0|1] ""  C_ECU_GW
 SG_ ADAS34B_10_3_CSTM_SAFTY_MODE : 83|1@1+ (1,0) [0|1] ""  C_ECU_GW
 SG_ ADAS34B_10_4_CSTM_SAFTY_MODE_LV : 84|2@1+ (1,0) [0|3] ""  C_ECU_GW
 SG_ ADAS34B_10_6_CSTM_BRK_TIMING_CUR : 86|1@1+ (1,0) [0|1] ""  C_ECU_GW
 SG_ ADAS34B_10_7_CSTM_FCW_CONT_CUR : 87|1@1+ (1,0) [0|1] ""  C_ECU_GW
 SG_ ADAS34B_9_0_CSTM_P_CR : 72|1@1+ (1,0) [0|1] ""  C_ECU_GW
 SG_ ADAS34B_9_1_FCW_SOUND_ON_OFF_SW : 73|1@1+ (1,0) [0|1] ""  C_ECU_GW
 SG_ ADAS34B_9_2_CSTM_FCW_TIMING : 74|2@1+ (1,0) [0|3] ""  C_ECU_GW
 SG_ ADAS34B_9_4_CSTM_FCW_TYPE_SOUND : 76|1@1+ (1,0) [0|1] ""  C_ECU_GW
 SG_ ADAS34B_9_5_CSTM_FCW_TYPE_PULSE : 77|1@1+ (1,0) [0|1] ""  C_ECU_GW
 SG_ ADAS34B_9_6_CSTM_BRAKE_TIMING : 78|2@1+ (1,0) [0|3] ""  C_ECU_GW
 SG_ ADAS34B_8_0_SAFTY_MODE_SENS_DISP : 64|2@1+ (1,0) [0|3] ""  C_ECU_GW
 SG_ ADAS34B_8_2_MIS_AT_BACK_PTN_DISP : 66|2@1+ (1,0) [0|3] ""  C_ECU_GW
 SG_ ADAS34B_7_0_MIS_AT_BACK_DISP : 56|2@1+ (1,0) [0|3] ""  C_ECU_GW
 SG_ ADAS34B_7_2_MIS_AT_BACK_LIM_DISP : 58|2@1+ (1,0) [0|3] ""  C_ECU_GW
 SG_ ADAS34B_7_4_BRK_TIMING_PTN_DISP : 60|2@1+ (1,0) [0|3] ""  C_ECU_GW
 SG_ ADAS34B_7_6_FCW_TIMING_PTN_DISP : 62|2@1+ (1,0) [0|3] ""  C_ECU_GW
 SG_ ADAS34B_6_0_SAFTY_MODE_DISP_CONT : 48|2@1+ (1,0) [0|3] ""  C_ECU_GW
 SG_ ADAS34B_6_2_SAFTY_MODE_LV_DISP : 50|2@1+ (1,0) [0|3] ""  C_ECU_GW
 SG_ ADAS34B_6_4_SAFTY_MODE_LV_PTN : 52|3@1+ (1,0) [0|7] ""  C_ECU_GW
 SG_ ADAS34B_5_0_FCTI_DISP_CONT : 40|2@1+ (1,0) [0|3] ""  C_ECU_GW
 SG_ ADAS34B_5_2_FCTI_NOTICE_DISP : 42|2@1+ (1,0) [0|3] ""  C_ECU_GW
 SG_ ADAS34B_5_4_FCTI_SOUND_DISP_CONT : 44|2@1+ (1,0) [0|3] ""  C_ECU_GW
 SG_ ADAS34B_5_6_FCTI_PULSE_DISP_CONT : 46|2@1+ (1,0) [0|3] ""  C_ECU_GW
 SG_ ADAS34B_4_0_FCW_TYPE_DISP_CONT : 32|2@1+ (1,0) [0|3] ""  C_ECU_GW
 SG_ ADAS34B_4_2_FCW_TYPE_SOUND_DISP : 34|2@1+ (1,0) [0|3] ""  C_ECU_GW
 SG_ ADAS34B_4_4_FCW_TYPE_PULSE_DISP : 36|2@1+ (1,0) [0|3] ""  C_ECU_GW
 SG_ ADAS34B_4_6_FCW_SOUND_SW_DISP : 38|2@1+ (1,0) [0|3] ""  C_ECU_GW
 SG_ ADAS34B_3_0_P_CR_DISP_CONT : 24|2@1+ (1,0) [0|3] ""  C_ECU_GW
 SG_ ADAS34B_3_2_BRAKE_TIMING_DISP : 26|2@1+ (1,0) [0|3] ""  C_ECU_GW
 SG_ ADAS34B_3_4_FCW_DISP_CONT : 28|2@1+ (1,0) [0|3] ""  C_ECU_GW
 SG_ ADAS34B_3_6_FCW_TIMING_DISP_PTN : 30|2@1+ (1,0) [0|3] ""  C_ECU_GW
 SG_ ADAS34B_2_0_E2E_COUNTER : 16|8@1+ (1,0) [0|255] ""  C_ECU_GW
 SG_ ADAS34B_0_0_E2E_CRC : 0|16@1+ (1,0) [0|65535] ""  C_ECU_GW

BO_ 841 ADAS349: 32 ADAS
 SG_ ADAS349_4_0_AAOS_AEB_STATE : 32|2@1+ (1,0) [0|4] ""  C_ECU_GW
 SG_ ADAS349_3_0_CID_MRM_DISP : 24|4@1+ (1,0) [0|9] ""  C_ECU_GW
 SG_ ADAS349_2_0_E2E_COUNTER : 16|8@1+ (1,0) [0|255] ""  C_ECU_GW
 SG_ ADAS349_0_0_E2E_CRC : 0|16@1+ (1,0) [0|65535] ""  C_ECU_GW

BO_ 833 ADAS341: 32 ADAS
 SG_ ADAS341_2_0_E2E_COUNTER : 16|8@1+ (1,0) [0|255] ""  MET
 SG_ ADAS341_0_0_E2E_CRC : 0|16@1+ (1,0) [0|65535] ""  MET

BO_ 832 ADAS340: 32 ADAS
 SG_ ADAS340_11_0_ANGLE : 88|3@1+ (1,0) [0|0] ""  MET
 SG_ ADAS340_11_5_VIEW_DISP : 93|3@1+ (1,0) [0|0] ""  MET
 SG_ ADAS340_10_0_TARGET_DIST_RANGE : 80|11@1+ (0.1,0) [0|0] "m"  MET
 SG_ ADAS340_9_3_TARGET_DIST : 75|1@1+ (1,0) [0|0] ""  MET
 SG_ ADAS340_9_6_DIST4 : 78|11@1+ (0.1,0) [0|0] "m"  MET
 SG_ ADAS340_7_1_DIST3 : 57|11@1+ (0.1,0) [0|0] "m"  MET
 SG_ ADAS340_6_4_DIST2 : 52|11@1+ (0.1,0) [0|0] "m"  MET
 SG_ ADAS340_5_7_DIST1 : 47|11@1+ (0.1,0) [0|0] "m"  MET
 SG_ ADAS340_3_2_DIST_SET_COLOR : 26|3@1+ (1,0) [0|0] ""  MET
 SG_ ADAS340_3_5_DIST_SET : 29|3@1+ (1,0) [0|0] ""  MET
 SG_ ADAS340_2_0_E2E_COUNTER : 16|8@1+ (1,0) [0|255] ""  MET
 SG_ ADAS340_0_0_E2E_CRC : 0|16@1+ (1,0) [0|65535] ""  MET

BO_ 825 ADAS339: 32 ADAS
 SG_ ADAS339_22_0_OBJECT20_WINKER : 176|2@1+ (1,0) [0|0] ""  MET
 SG_ ADAS339_22_2_OBJECT20_BRAKE : 178|1@1+ (1,0) [0|0] ""  MET
 SG_ ADAS339_22_3_OBJECT20_BLINK : 179|2@1+ (1,0) [0|0] ""  MET
 SG_ ADAS339_22_5_OBJECT20_Z : 181|11@1+ (0.1,-20) [0|0] "m"  MET
 SG_ ADAS339_20_0_OBJECT20_X : 160|9@1+ (0.1,-15) [0|0] "m"  MET
 SG_ ADAS339_19_1_OBJECT20_ANGLE : 153|7@1+ (5,0) [0|0] "deg"  MET
 SG_ ADAS339_18_0_OBJECT20_COLOR : 144|4@1+ (1,0) [0|0] ""  MET
 SG_ ADAS339_18_4_OBJECT20_SHAPE : 148|4@1+ (1,0) [0|0] ""  MET
 SG_ ADAS339_17_0_OBJECT19_WINKER : 136|2@1+ (1,0) [0|0] ""  MET
 SG_ ADAS339_17_2_OBJECT19_BRAKE : 138|1@1+ (1,0) [0|0] ""  MET
 SG_ ADAS339_17_3_OBJECT19_BLINK : 139|2@1+ (1,0) [0|0] ""  MET
 SG_ ADAS339_17_5_OBJECT19_Z : 141|11@1+ (0.1,-20) [0|0] "m"  MET
 SG_ ADAS339_15_0_OBJECT19_X : 120|9@1+ (0.1,-15) [0|0] "m"  MET
 SG_ ADAS339_14_1_OBJECT19_ANGLE : 113|7@1+ (5,0) [0|0] "deg"  MET
 SG_ ADAS339_13_0_OBJECT19_COLOR : 104|4@1+ (1,0) [0|0] ""  MET
 SG_ ADAS339_13_4_OBJECT19_SHAPE : 108|4@1+ (1,0) [0|0] ""  MET
 SG_ ADAS339_12_0_OBJECT18_WINKER : 96|2@1+ (1,0) [0|0] ""  MET
 SG_ ADAS339_12_2_OBJECT18_BRAKE : 98|1@1+ (1,0) [0|0] ""  MET
 SG_ ADAS339_12_3_OBJECT18_BLINK : 99|2@1+ (1,0) [0|0] ""  MET
 SG_ ADAS339_12_5_OBJECT18_Z : 101|11@1+ (0.1,-20) [0|0] "m"  MET
 SG_ ADAS339_10_0_OBJECT18_X : 80|9@1+ (0.1,-15) [0|0] "m"  MET
 SG_ ADAS339_9_1_OBJECT18_ANGLE : 73|7@1+ (5,0) [0|0] "deg"  MET
 SG_ ADAS339_8_0_OBJECT18_COLOR : 64|4@1+ (1,0) [0|0] ""  MET
 SG_ ADAS339_8_4_OBJECT18_SHAPE : 68|4@1+ (1,0) [0|0] ""  MET
 SG_ ADAS339_7_0_OBJECT17_WINKER : 56|2@1+ (1,0) [0|0] ""  MET
 SG_ ADAS339_7_2_OBJECT17_BRAKE : 58|1@1+ (1,0) [0|0] ""  MET
 SG_ ADAS339_7_3_OBJECT17_BLINK : 59|2@1+ (1,0) [0|0] ""  MET
 SG_ ADAS339_7_5_OBJECT17_Z : 61|11@1+ (0.1,-20) [0|0] "m"  MET
 SG_ ADAS339_5_0_OBJECT17_X : 40|9@1+ (0.1,-15) [0|0] "m"  MET
 SG_ ADAS339_4_1_OBJECT17_ANGLE : 33|7@1+ (5,0) [0|0] "deg"  MET
 SG_ ADAS339_3_0_OBJECT17_COLOR : 24|4@1+ (1,0) [0|0] ""  MET
 SG_ ADAS339_3_4_OBJECT17_SHAPE : 28|4@1+ (1,0) [0|0] ""  MET
 SG_ ADAS339_2_0_E2E_COUNTER : 16|8@1+ (1,0) [0|255] ""  MET
 SG_ ADAS339_0_0_E2E_CRC : 0|16@1+ (1,0) [0|65535] ""  MET

CM_ SG_ 686 RCR2AE_6_0_BEHIND_BORDER_RIGHT_8 "ﾛｰﾄﾞﾎﾞｰﾀﾞｰ裏ﾌﾗｸﾞ_右8
";
CM_ SG_ 686 RCR2AE_6_1_GHOST_FLG_RIGHT_8 "ｺﾞｰｽﾄﾌﾗｸﾞ_右8
";
CM_ SG_ 686 RCR2AE_6_6_OBJ_RELSPD_Y_RIGHT_8 "ｵﾌﾞｼﾞｪｸﾄ横相対速_右8
";
CM_ SG_ 686 RCR2AE_5_6_OBJ_STATUS_RIGHT_8 "ｵﾌﾞｼﾞｪｸﾄｽﾃｰﾀｽ_右8
";
CM_ SG_ 686 RCR2AE_4_4_OBJ_RELSPD_X_RIGHT_8 "ｵﾌﾞｼﾞｪｸﾄ縦相対速_右8
";
CM_ SG_ 686 RCR2AE_3_0_OBJ_DIST_Y_RIGHT_8 "ｵﾌﾞｼﾞｪｸﾄ横距離_右8
";
CM_ SG_ 686 RCR2AE_1_0_MSG_COUNTER "ﾒｯｾｰｼﾞｶｳﾝﾀ
";
CM_ SG_ 686 RCR2AE_1_4_OBJ_DIST_X_RIGHT_8 "ｵﾌﾞｼﾞｪｸﾄ縦距離_右8
";
CM_ SG_ 686 RCR2AE_0_0_CHECK_SUM "ﾁｪｯｸｻﾑ
";
CM_ SG_ 685 RCR2AD_6_0_BEHIND_BORDER_RIGHT_7 "ﾛｰﾄﾞﾎﾞｰﾀﾞｰ裏ﾌﾗｸﾞ_右7
";
CM_ SG_ 685 RCR2AD_6_1_GHOST_FLG_RIGHT_7 "ｺﾞｰｽﾄﾌﾗｸﾞ_右7
";
CM_ SG_ 685 RCR2AD_6_6_OBJ_RELSPD_Y_RIGHT_7 "ｵﾌﾞｼﾞｪｸﾄ横相対速_右7
";
CM_ SG_ 685 RCR2AD_5_6_OBJ_STATUS_RIGHT_7 "ｵﾌﾞｼﾞｪｸﾄｽﾃｰﾀｽ_右7
";
CM_ SG_ 685 RCR2AD_4_4_OBJ_RELSPD_X_RIGHT_7 "ｵﾌﾞｼﾞｪｸﾄ縦相対速_右7
";
CM_ SG_ 685 RCR2AD_3_0_OBJ_DIST_Y_RIGHT_7 "ｵﾌﾞｼﾞｪｸﾄ横距離_右7
";
CM_ SG_ 685 RCR2AD_1_0_MSG_COUNTER "ﾒｯｾｰｼﾞｶｳﾝﾀ
";
CM_ SG_ 685 RCR2AD_1_4_OBJ_DIST_X_RIGHT_7 "ｵﾌﾞｼﾞｪｸﾄ縦距離_右7
";
CM_ SG_ 685 RCR2AD_0_0_CHECK_SUM "ﾁｪｯｸｻﾑ
";
CM_ SG_ 684 RCR2AC_6_0_BEHIND_BORDER_RIGHT_6 "ﾛｰﾄﾞﾎﾞｰﾀﾞｰ裏ﾌﾗｸﾞ_右6
";
CM_ SG_ 684 RCR2AC_6_1_GHOST_FLG_RIGHT_6 "ｺﾞｰｽﾄﾌﾗｸﾞ_右6
";
CM_ SG_ 684 RCR2AC_6_6_OBJ_RELSPD_Y_RIGHT_6 "ｵﾌﾞｼﾞｪｸﾄ横相対速_右6
";
CM_ SG_ 684 RCR2AC_5_6_OBJ_STATUS_RIGHT_6 "ｵﾌﾞｼﾞｪｸﾄｽﾃｰﾀｽ_右6
";
CM_ SG_ 684 RCR2AC_4_4_OBJ_RELSPD_X_RIGHT_6 "ｵﾌﾞｼﾞｪｸﾄ縦相対速_右6
";
CM_ SG_ 684 RCR2AC_3_0_OBJ_DIST_Y_RIGHT_6 "ｵﾌﾞｼﾞｪｸﾄ横距離_右6
";
CM_ SG_ 684 RCR2AC_1_0_MSG_COUNTER "ﾒｯｾｰｼﾞｶｳﾝﾀ
";
CM_ SG_ 684 RCR2AC_1_4_OBJ_DIST_X_RIGHT_6 "ｵﾌﾞｼﾞｪｸﾄ縦距離_右6
";
CM_ SG_ 684 RCR2AC_0_0_CHECK_SUM "ﾁｪｯｸｻﾑ
";
CM_ SG_ 683 RCR2AB_6_0_BEHIND_BORDER_RIGHT_5 "ﾛｰﾄﾞﾎﾞｰﾀﾞｰ裏ﾌﾗｸﾞ_右5
";
CM_ SG_ 683 RCR2AB_6_1_GHOST_FLG_RIGHT_5 "ｺﾞｰｽﾄﾌﾗｸﾞ_右5
";
CM_ SG_ 683 RCR2AB_6_6_OBJ_RELSPD_Y_RIGHT_5 "ｵﾌﾞｼﾞｪｸﾄ横相対速_右5
";
CM_ SG_ 683 RCR2AB_5_6_OBJ_STATUS_RIGHT_5 "ｵﾌﾞｼﾞｪｸﾄｽﾃｰﾀｽ_右5
";
CM_ SG_ 683 RCR2AB_4_4_OBJ_RELSPD_X_RIGHT_5 "ｵﾌﾞｼﾞｪｸﾄ縦相対速_右5
";
CM_ SG_ 683 RCR2AB_3_0_OBJ_DIST_Y_RIGHT_5 "ｵﾌﾞｼﾞｪｸﾄ横距離_右5
";
CM_ SG_ 683 RCR2AB_1_0_MSG_COUNTER "ﾒｯｾｰｼﾞｶｳﾝﾀ
";
CM_ SG_ 683 RCR2AB_1_4_OBJ_DIST_X_RIGHT_5 "ｵﾌﾞｼﾞｪｸﾄ縦距離_右5
";
CM_ SG_ 683 RCR2AB_0_0_CHECK_SUM "ﾁｪｯｸｻﾑ
";
CM_ SG_ 682 RCR2AA_6_0_BEHIND_BORDER_RIGHT_4 "ﾛｰﾄﾞﾎﾞｰﾀﾞｰ裏ﾌﾗｸﾞ_右4
";
CM_ SG_ 682 RCR2AA_6_1_GHOST_FLG_RIGHT_4 "ｺﾞｰｽﾄﾌﾗｸﾞ_右4
";
CM_ SG_ 682 RCR2AA_6_6_OBJ_RELSPD_Y_RIGHT_4 "ｵﾌﾞｼﾞｪｸﾄ横相対速_右4
";
CM_ SG_ 682 RCR2AA_5_6_OBJ_STATUS_RIGHT_4 "ｵﾌﾞｼﾞｪｸﾄｽﾃｰﾀｽ_右4
";
CM_ SG_ 682 RCR2AA_4_4_OBJ_RELSPD_X_RIGHT_4 "ｵﾌﾞｼﾞｪｸﾄ縦相対速_右4
";
CM_ SG_ 682 RCR2AA_3_0_OBJ_DIST_Y_RIGHT_4 "ｵﾌﾞｼﾞｪｸﾄ横距離_右4
";
CM_ SG_ 682 RCR2AA_1_0_MSG_COUNTER "ﾒｯｾｰｼﾞｶｳﾝﾀ
";
CM_ SG_ 682 RCR2AA_1_4_OBJ_DIST_X_RIGHT_4 "ｵﾌﾞｼﾞｪｸﾄ縦距離_右4
";
CM_ SG_ 682 RCR2AA_0_0_CHECK_SUM "ﾁｪｯｸｻﾑ
";
CM_ SG_ 681 RCR2A9_6_0_BEHIND_BORDER_RIGHT_3 "ﾛｰﾄﾞﾎﾞｰﾀﾞｰ裏ﾌﾗｸﾞ_右3
";
CM_ SG_ 681 RCR2A9_6_1_GHOST_FLG_RIGHT_3 "ｺﾞｰｽﾄﾌﾗｸﾞ_右3
";
CM_ SG_ 681 RCR2A9_6_6_OBJ_RELSPD_Y_RIGHT_3 "ｵﾌﾞｼﾞｪｸﾄ横相対速_右3
";
CM_ SG_ 681 RCR2A9_5_6_OBJ_STATUS_RIGHT_3 "ｵﾌﾞｼﾞｪｸﾄｽﾃｰﾀｽ_右3
";
CM_ SG_ 681 RCR2A9_4_4_OBJ_RELSPD_X_RIGHT_3 "ｵﾌﾞｼﾞｪｸﾄ縦相対速_右3
";
CM_ SG_ 681 RCR2A9_3_0_OBJ_DIST_Y_RIGHT_3 "ｵﾌﾞｼﾞｪｸﾄ横距離_右
";
CM_ SG_ 681 RCR2A9_1_0_MSG_COUNTER "ﾒｯｾｰｼﾞｶｳﾝﾀ
";
CM_ SG_ 681 RCR2A9_1_4_OBJ_DIST_X_RIGHT_3 "ｵﾌﾞｼﾞｪｸﾄ縦距離_右3
";
CM_ SG_ 681 RCR2A9_0_0_CHECK_SUM "ﾁｪｯｸｻﾑ
";
CM_ SG_ 680 RCR2A8_6_0_BEHIND_BORDER_RIGHT_3 "ﾛｰﾄﾞﾎﾞｰﾀﾞｰ裏ﾌﾗｸﾞ_右3
";
CM_ SG_ 680 RCR2A8_6_1_GHOST_FLG_RIGHT_2 "ｺﾞｰｽﾄﾌﾗｸﾞ_右2
";
CM_ SG_ 680 RCR2A8_6_6_OBJ_RELSPD_Y_RIGHT_2 "ｵﾌﾞｼﾞｪｸﾄ横相対速_右2
";
CM_ SG_ 680 RCR2A8_5_6_OBJ_STATUS_RIGHT_2 "ｵﾌﾞｼﾞｪｸﾄｽﾃｰﾀｽ_右2
";
CM_ SG_ 680 RCR2A8_4_4_OBJ_RELSPD_X_RIGHT_2 "ｵﾌﾞｼﾞｪｸﾄ縦相対速_右2
";
CM_ SG_ 680 RCR2A8_3_0_OBJ_DIST_Y_RIGHT_2 "ｵﾌﾞｼﾞｪｸﾄ横距離_右2
";
CM_ SG_ 680 RCR2A8_1_0_MSG_COUNTER "ﾒｯｾｰｼﾞｶｳﾝﾀ
";
CM_ SG_ 680 RCR2A8_1_4_OBJ_DIST_X_RIGHT_2 "ｵﾌﾞｼﾞｪｸﾄ縦距離_右2
";
CM_ SG_ 680 RCR2A8_0_0_CHECK_SUM "ﾁｪｯｸｻﾑ
";
CM_ SG_ 679 RCR2A7_6_0_BEHIND_BORDER_RIGHT_1 "ﾛｰﾄﾞﾎﾞｰﾀﾞｰ裏ﾌﾗｸﾞ_右1
";
CM_ SG_ 679 RCR2A7_6_1_GHOST_FLG_RIGHT_1 "ｺﾞｰｽﾄﾌﾗｸﾞ_右1
";
CM_ SG_ 679 RCR2A7_6_6_OBJ_RELSPD_Y_RIGHT_1 "ｵﾌﾞｼﾞｪｸﾄ横相対速_右1
";
CM_ SG_ 679 RCR2A7_5_6_OBJ_STATUS_RIGHT_1 "ｵﾌﾞｼﾞｪｸﾄｽﾃｰﾀｽ_右1
";
CM_ SG_ 679 RCR2A7_4_4_OBJ_RELSPD_X_RIGHT_1 "ｵﾌﾞｼﾞｪｸﾄ縦相対速_右1
";
CM_ SG_ 679 RCR2A7_3_0_OBJ_DIST_Y_RIGHT_1 "ｵﾌﾞｼﾞｪｸﾄ横距離_右1
";
CM_ SG_ 679 RCR2A7_1_0_MSG_COUNTER "ﾒｯｾｰｼﾞｶｳﾝﾀ
";
CM_ SG_ 679 RCR2A7_1_4_OBJ_DIST_X_RIGHT_1 "ｵﾌﾞｼﾞｪｸﾄ縦距離_右1
";
CM_ SG_ 679 RCR2A7_0_0_CHECK_SUM "ﾁｪｯｸｻﾑ
";
CM_ SG_ 678 RCR2A6_6_0_BEHIND_BORDER_RIGHT_0 "ﾛｰﾄﾞﾎﾞｰﾀﾞｰ裏ﾌﾗｸﾞ_右0
";
CM_ SG_ 678 RCR2A6_6_1_GHOST_FLG_RIGHT_0 "ｺﾞｰｽﾄﾌﾗｸﾞ_右0
";
CM_ SG_ 678 RCR2A6_6_6_OBJ_RELSPD_Y_RIGHT_0 "ｵﾌﾞｼﾞｪｸﾄ横相対速_右0
";
CM_ SG_ 678 RCR2A6_5_6_OBJ_STATUS_RIGHT_0 "ｵﾌﾞｼﾞｪｸﾄｽﾃｰﾀｽ_右0
";
CM_ SG_ 678 RCR2A6_4_4_OBJ_RELSPD_X_RIGHT_0 "ｵﾌﾞｼﾞｪｸﾄ縦相対速_右0
";
CM_ SG_ 678 RCR2A6_3_0_OBJ_DIST_Y_RIGHT_0 "ｵﾌﾞｼﾞｪｸﾄ横距離_右0
";
CM_ SG_ 678 RCR2A6_1_0_MSG_COUNTER "ﾒｯｾｰｼﾞｶｳﾝﾀ
";
CM_ SG_ 678 RCR2A6_1_4_OBJ_DIST_X_RIGHT_0 "ｵﾌﾞｼﾞｪｸﾄ縦距離_右0
";
CM_ SG_ 678 RCR2A6_0_0_CHECK_SUM "ﾁｪｯｸｻﾑ
";
CM_ SG_ 670 RCR29E_6_0_BEHIND_BORDER_LEFT_8 "ﾛｰﾄﾞﾎﾞｰﾀﾞｰ裏ﾌﾗｸﾞ_左8
";
CM_ SG_ 670 RCR29E_6_1_GHOST_FLG_LEFT_8 "ｺﾞｰｽﾄﾌﾗｸﾞ_左8
";
CM_ SG_ 670 RCR29E_6_6_OBJ_RELSPD_Y_LEFT_8 "ｵﾌﾞｼﾞｪｸﾄ横相対速_左8
";
CM_ SG_ 670 RCR29E_5_6_OBJ_STATUS_LEFT_8 "ｵﾌﾞｼﾞｪｸﾄｽﾃｰﾀｽ_左8
";
CM_ SG_ 670 RCR29E_4_4_OBJ_RELSPD_X_LEFT_8 "ｵﾌﾞｼﾞｪｸﾄ縦相対速_左8
";
CM_ SG_ 670 RCR29E_3_0_OBJ_DIST_Y_LEFT_8 "ｵﾌﾞｼﾞｪｸﾄ横距離_左8
";
CM_ SG_ 670 RCR29E_1_0_MSG_COUNTER "ﾒｯｾｰｼﾞｶｳﾝﾀ
";
CM_ SG_ 670 RCR29E_1_4_OBJ_DIST_X_LEFT_8 "ｵﾌﾞｼﾞｪｸﾄ縦距離_左8
";
CM_ SG_ 670 RCR29E_0_0_CHECK_SUM "ﾁｪｯｸｻﾑ
";
CM_ SG_ 669 RCR29D_6_0_BEHIND_BORDER_LEFT_7 "ﾛｰﾄﾞﾎﾞｰﾀﾞｰ裏ﾌﾗｸﾞ_左7
";
CM_ SG_ 669 RCR29D_6_1_GHOST_FLG_LEFT_7 "ｺﾞｰｽﾄﾌﾗｸﾞ_左7
";
CM_ SG_ 669 RCR29D_6_6_OBJ_RELSPD_Y_LEFT_7 "ｵﾌﾞｼﾞｪｸﾄ横相対速_左7
";
CM_ SG_ 669 RCR29D_5_6_OBJ_STATUS_LEFT_7 "ｵﾌﾞｼﾞｪｸﾄｽﾃｰﾀｽ_左7
";
CM_ SG_ 669 RCR29D_4_4_OBJ_RELSPD_X_LEFT_7 "ｵﾌﾞｼﾞｪｸﾄ縦相対速_左7
";
CM_ SG_ 669 RCR29D_3_0_OBJ_DIST_Y_LEFT_7 "ｵﾌﾞｼﾞｪｸﾄ横距離_左7
";
CM_ SG_ 669 RCR29D_1_0_MSG_COUNTER "ﾒｯｾｰｼﾞｶｳﾝﾀ
";
CM_ SG_ 669 RCR29D_1_4_OBJ_DIST_X_LEFT_7 "ｵﾌﾞｼﾞｪｸﾄ縦距離_左7
";
CM_ SG_ 669 RCR29D_0_0_CHECK_SUM "ﾁｪｯｸｻﾑ
";
CM_ SG_ 668 RCR29C_6_0_BEHIND_BORDER_LEFT_6 "ﾛｰﾄﾞﾎﾞｰﾀﾞｰ裏ﾌﾗｸﾞ_左6
";
CM_ SG_ 668 RCR29C_6_1_GHOST_FLG_LEFT_6 "ｺﾞｰｽﾄﾌﾗｸﾞ_左6
";
CM_ SG_ 668 RCR29C_6_6_OBJ_RELSPD_Y_LEFT_6 "ｵﾌﾞｼﾞｪｸﾄ横相対速_左6
";
CM_ SG_ 668 RCR29C_5_6_OBJ_STATUS_LEFT_6 "ｵﾌﾞｼﾞｪｸﾄｽﾃｰﾀｽ_左6
";
CM_ SG_ 668 RCR29C_4_4_OBJ_RELSPD_X_LEFT_6 "ｵﾌﾞｼﾞｪｸﾄ縦相対速_左6
";
CM_ SG_ 668 RCR29C_3_0_OBJ_DIST_Y_LEFT_6 "ｵﾌﾞｼﾞｪｸﾄ横距離_左6
";
CM_ SG_ 668 RCR29C_1_0_MSG_COUNTER "ﾒｯｾｰｼﾞｶｳﾝﾀ
";
CM_ SG_ 668 RCR29C_1_4_OBJ_DIST_X_LEFT_6 "ｵﾌﾞｼﾞｪｸﾄ縦距離_左6
";
CM_ SG_ 668 RCR29C_0_0_CHECK_SUM "ﾁｪｯｸｻﾑ
";
CM_ SG_ 667 RCR29B_6_0_BEHIND_BORDER_LEFT_5 "ﾛｰﾄﾞﾎﾞｰﾀﾞｰ裏ﾌﾗｸﾞ_左5
";
CM_ SG_ 667 RCR29B_6_1_GHOST_FLG_LEFT_5 "ｺﾞｰｽﾄﾌﾗｸﾞ_左5
";
CM_ SG_ 667 RCR29B_6_6_OBJ_RELSPD_Y_LEFT_5 "ｵﾌﾞｼﾞｪｸﾄ横相対速_左5
";
CM_ SG_ 667 RCR29B_5_6_OBJ_STATUS_LEFT_5 "ｵﾌﾞｼﾞｪｸﾄｽﾃｰﾀｽ_左5
";
CM_ SG_ 667 RCR29B_4_4_OBJ_RELSPD_X_LEFT_5 "ｵﾌﾞｼﾞｪｸﾄ縦相対速_左5
";
CM_ SG_ 667 RCR29B_3_0_OBJ_DIST_Y_LEFT_5 "ｵﾌﾞｼﾞｪｸﾄ横距離_左5
";
CM_ SG_ 667 RCR29B_1_0_MSG_COUNTER "ﾒｯｾｰｼﾞｶｳﾝﾀ
";
CM_ SG_ 667 RCR29B_1_4_OBJ_DIST_X_LEFT_5 "ｵﾌﾞｼﾞｪｸﾄ縦距離_左5
";
CM_ SG_ 667 RCR29B_0_0_CHECK_SUM "ﾁｪｯｸｻﾑ
";
CM_ SG_ 666 RCR29A_6_0_BEHIND_BORDER_LEFT_4 "ﾛｰﾄﾞﾎﾞｰﾀﾞｰ裏ﾌﾗｸﾞ_左4
";
CM_ SG_ 666 RCR29A_6_1_GHOST_FLG_LEFT_4 "ｺﾞｰｽﾄﾌﾗｸﾞ_左4
";
CM_ SG_ 666 RCR29A_6_6_OBJ_RELSPD_Y_LEFT_4 "ｵﾌﾞｼﾞｪｸﾄ横相対速_左4
";
CM_ SG_ 666 RCR29A_5_6_OBJ_STATUS_LEFT_4 "ｵﾌﾞｼﾞｪｸﾄｽﾃｰﾀｽ_左4
";
CM_ SG_ 666 RCR29A_4_4_OBJ_RELSPD_X_LEFT_4 "ｵﾌﾞｼﾞｪｸﾄ縦相対速_左4
";
CM_ SG_ 666 RCR29A_3_0_OBJ_DIST_Y_LEFT_4 "ｵﾌﾞｼﾞｪｸﾄ横距離_左4
";
CM_ SG_ 666 RCR29A_1_0_MSG_COUNTER "ﾒｯｾｰｼﾞｶｳﾝﾀ
";
CM_ SG_ 666 RCR29A_1_4_OBJ_DIST_X_LEFT_4 "ｵﾌﾞｼﾞｪｸﾄ縦距離_左4
";
CM_ SG_ 666 RCR29A_0_0_CHECK_SUM "ﾁｪｯｸｻﾑ
";
CM_ SG_ 665 RCR299_6_0_BEHIND_BORDER_LEFT_3 "ﾛｰﾄﾞﾎﾞｰﾀﾞｰ裏ﾌﾗｸﾞ_左3
";
CM_ SG_ 665 RCR299_6_1_GHOST_FLG_LEFT_3 "ｺﾞｰｽﾄﾌﾗｸﾞ_左3
";
CM_ SG_ 665 RCR299_6_6_OBJ_RELSPD_Y_LEFT_3 "ｵﾌﾞｼﾞｪｸﾄ横相対速_左3
";
CM_ SG_ 665 RCR299_5_6_OBJ_STATUS_LEFT_3 "ｵﾌﾞｼﾞｪｸﾄｽﾃｰﾀｽ_左3
";
CM_ SG_ 665 RCR299_4_4_OBJ_RELSPD_X_LEFT_3 "ｵﾌﾞｼﾞｪｸﾄ縦相対速_左3
";
CM_ SG_ 665 RCR299_3_0_OBJ_DIST_Y_LEFT_3 "ｵﾌﾞｼﾞｪｸﾄ横距離_左3
";
CM_ SG_ 665 RCR299_1_0_MSG_COUNTER "ﾒｯｾｰｼﾞｶｳﾝﾀ
";
CM_ SG_ 665 RCR299_1_4_OBJ_DIST_X_LEFT_3 "ｵﾌﾞｼﾞｪｸﾄ縦距離_左3
";
CM_ SG_ 665 RCR299_0_0_CHECK_SUM "ﾁｪｯｸｻﾑ
";
CM_ SG_ 664 RCR298_6_0_BEHIND_BORDER_LEFT_2 "ﾛｰﾄﾞﾎﾞｰﾀﾞｰ裏ﾌﾗｸﾞ_左2
";
CM_ SG_ 664 RCR298_6_1_GHOST_FLG_LEFT_2 "ｺﾞｰｽﾄﾌﾗｸﾞ_左2
";
CM_ SG_ 664 RCR298_6_6_OBJ_RELSPD_Y_LEFT_2 "ｵﾌﾞｼﾞｪｸﾄ横相対速_左2
";
CM_ SG_ 664 RCR298_5_6_OBJ_STATUS_LEFT_2 "ｵﾌﾞｼﾞｪｸﾄｽﾃｰﾀｽ_左2
";
CM_ SG_ 664 RCR298_4_4_OBJ_RELSPD_X_LEFT_2 "ｵﾌﾞｼﾞｪｸﾄ縦相対速_左2
";
CM_ SG_ 664 RCR298_3_0_OBJ_DIST_Y_LEFT_2 "ｵﾌﾞｼﾞｪｸﾄ横距離_左2
";
CM_ SG_ 664 RCR298_1_0_MSG_COUNTER "ﾒｯｾｰｼﾞｶｳﾝﾀ
";
CM_ SG_ 664 RCR298_1_4_OBJ_DIST_X_LEFT_2 "ｵﾌﾞｼﾞｪｸﾄ縦距離_左2
";
CM_ SG_ 664 RCR298_0_0_CHECK_SUM "ﾁｪｯｸｻﾑ
";
CM_ SG_ 663 RCR297_6_0_BEHIND_BORDER_LEFT_1 "ﾛｰﾄﾞﾎﾞｰﾀﾞｰ裏ﾌﾗｸﾞ_左1
";
CM_ SG_ 663 RCR297_6_1_GHOST_FLG_LEFT_1 "ｺﾞｰｽﾄﾌﾗｸﾞ_左1
";
CM_ SG_ 663 RCR297_6_6_OBJ_RELSPD_Y_LEFT_1 "ｵﾌﾞｼﾞｪｸﾄ横相対速_左1
";
CM_ SG_ 663 RCR297_5_6_OBJ_STATUS_LEFT_1 "ｵﾌﾞｼﾞｪｸﾄｽﾃｰﾀｽ_左1
";
CM_ SG_ 663 RCR297_4_4_OBJ_RELSPD_X_LEFT_1 "ｵﾌﾞｼﾞｪｸﾄ縦相対速_左1
";
CM_ SG_ 663 RCR297_3_0_OBJ_DIST_Y_LEFT_1 "ｵﾌﾞｼﾞｪｸﾄ横距離_左1
";
CM_ SG_ 663 RCR297_1_0_MSG_COUNTER "ﾒｯｾｰｼﾞｶｳﾝﾀ
";
CM_ SG_ 663 RCR297_1_4_OBJ_DIST_X_LEFT_1 "ｵﾌﾞｼﾞｪｸﾄ縦距離_左1
";
CM_ SG_ 663 RCR297_0_0_CHECK_SUM "ﾁｪｯｸｻﾑ
";
CM_ SG_ 662 RCR296_6_0_BEHIND_BORDER_LEFT_0 "ﾛｰﾄﾞﾎﾞｰﾀﾞｰ裏ﾌﾗｸﾞ_左0
";
CM_ SG_ 662 RCR296_6_1_GHOST_FLG_LEFT_0 "ｺﾞｰｽﾄﾌﾗｸﾞ_左0
";
CM_ SG_ 662 RCR296_6_6_OBJ_RELSPD_Y_LEFT_0 "ｵﾌﾞｼﾞｪｸﾄ横相対速_左0
";
CM_ SG_ 662 RCR296_5_6_OBJ_STATUS_LEFT_0 "ｵﾌﾞｼﾞｪｸﾄｽﾃｰﾀｽ_左0
";
CM_ SG_ 662 RCR296_4_4_OBJ_RELSPD_X_LEFT_0 "ｵﾌﾞｼﾞｪｸﾄ縦相対速_左0
";
CM_ SG_ 662 RCR296_3_0_OBJ_DIST_Y_LEFT_0 "ｵﾌﾞｼﾞｪｸﾄ横距離_左0
";
CM_ SG_ 662 RCR296_1_0_MSG_COUNTER "ﾒｯｾｰｼﾞｶｳﾝﾀ
";
CM_ SG_ 662 RCR296_1_4_OBJ_DIST_X_LEFT_0 "ｵﾌﾞｼﾞｪｸﾄ縦距離_左0
";
CM_ SG_ 662 RCR296_0_0_CHECK_SUM "ﾁｪｯｸｻﾑ
";
CM_ SG_ 552 RDR228_7_0_EYE_TIMEOUT_ERROR_FLG "後側方ﾚｰﾀﾞ ｱｲｻｲﾄﾃﾞｰﾀ未着・異常検知ﾌﾗｸﾞ
";
CM_ SG_ 552 RDR228_7_1_BLOCKAGE_FORMING_2 "ﾌﾞﾛｯｹｰｼﾞ2条件成立ﾌﾗｸﾞ
";
CM_ SG_ 552 RDR228_7_2_WARN_LCA_R_1ST "右側LCA警報1次ﾌﾗｸﾞ（注意喚起）
";
CM_ SG_ 552 RDR228_7_3_WARN_LCA_L_1ST "左側LCA警報1次ﾌﾗｸﾞ（注意喚起）
";
CM_ SG_ 552 RDR228_7_4_WARN_LCA_R_2ND "右側LCA警報2次ﾌﾗｸﾞ（ｳｨﾝｶｰON）
";
CM_ SG_ 552 RDR228_7_5_WARN_LCA_L_2ND "左側LCA警報2次ﾌﾗｸﾞ（ｳｨﾝｶｰON）
";
CM_ SG_ 552 RDR228_7_6_WARN_RCTA_R "右RCTA警報ﾌﾗｸﾞ
";
CM_ SG_ 552 RDR228_7_7_WARN_RCTA_L "左RCTA警報ﾌﾗｸﾞ
";
CM_ SG_ 552 RDR228_6_0_WARN_BSD_R_1ST "右側BSD警報ﾌﾗｸﾞ(注意喚起)
";
CM_ SG_ 552 RDR228_6_1_WARN_BSD_L_1ST "左側BSD警報ﾌﾗｸﾞ(注意喚起)
";
CM_ SG_ 552 RDR228_6_2_WARN_BSD_R_2ND "右側BSD警報2次ﾌﾗｸﾞ(ｳｨﾝｶｰON)
";
CM_ SG_ 552 RDR228_6_3_WARN_BSD_L_2ND "左側BSD警報2次ﾌﾗｸﾞ(ｳｨﾝｶｰON)
";
CM_ SG_ 552 RDR228_6_5_BLOCKAGE_STS "ﾌﾞﾛｯｹｰｼﾞｽﾃｰﾀｽ
";
CM_ SG_ 552 RDR228_5_0_BSD_R_E "右側BSDﾌﾗｸﾞ(EYE-ELK用)
";
CM_ SG_ 552 RDR228_5_1_BSD_L_E "左側BSDﾌﾗｸﾞ(EYE-ELK用)
";
CM_ SG_ 552 RDR228_5_2_LCA_R_E "右側LCAﾌﾗｸﾞ(EYE-ELK用)
";
CM_ SG_ 552 RDR228_5_3_LCA_L_E "左側LCAﾌﾗｸﾞ(EYE-ELK用)
";
CM_ SG_ 552 RDR228_5_4_BSD_R_A "右側BSDﾌﾗｸﾞ(EYE-AES用)
";
CM_ SG_ 552 RDR228_5_5_BSD_L_A "左側BSDﾌﾗｸﾞ(EYE-AES用)
";
CM_ SG_ 552 RDR228_5_6_LCA_R_A "右側LCAﾌﾗｸﾞ(EYE-AES用)
";
CM_ SG_ 552 RDR228_5_7_LCA_L_A "左側LCAﾌﾗｸﾞ(EYE-AES用)
";
CM_ SG_ 552 RDR228_4_0_DOW_ACTIVELAMP "DOW Active灯表示ﾌﾗｸﾞ
";
CM_ SG_ 552 RDR228_4_1_WARN_DOW_1ST_R "右側DOW警報1次ﾌﾗｸﾞ
";
CM_ SG_ 552 RDR228_4_2_WARN_DOW_1ST_L "左側DOW警報1次ﾌﾗｸﾞ
";
CM_ SG_ 552 RDR228_4_3_WARN_DOW_2ST_R "右側DOW警報2次ﾌﾗｸﾞ
";
CM_ SG_ 552 RDR228_4_4_WARN_DOW_2ST_L "左側DOW警報2次ﾌﾗｸﾞ
";
CM_ SG_ 552 RDR228_4_5_CSTM_STS_SRVD "ｶｽﾀﾏｲｽﾞ状態－BSD/LCA警報ON-OFF
";
CM_ SG_ 552 RDR228_4_6_CSTM_STS_BSD_LCA_2ND "ｶｽﾀﾏｲｽﾞ状態－BSD/LCA2次ﾌﾞｻﾞｰON-OFF
";
CM_ SG_ 552 RDR228_4_7_CSTM_STS_RCTA "ｶｽﾀﾏｲｽﾞ状態－RCTA　ON-OFF
";
CM_ SG_ 552 RDR228_3_0_WARN_BSD_LCA_R_2ND "右側BSD/LCA2次ﾌﾞｻﾞｰﾌﾗｸﾞ
";
CM_ SG_ 552 RDR228_3_1_WARN_BSD_LCA_L_2ND "左側BSD/LCA2次ﾌﾞｻﾞｰﾌﾗｸﾞ
";
CM_ SG_ 552 RDR228_3_2_CSTM_STS_DOW "ｶｽﾀﾏｲｽﾞ状態－DOW　ON-OFF
";
CM_ SG_ 552 RDR228_3_3_CSTM_STS_DOW_SFT_POS "ｶｽﾀﾏｲｽﾞ状態－DOW有効ｼﾌﾄﾎﾟｼﾞｼｮﾝ
";
CM_ SG_ 552 RDR228_3_5_CSTM_DSP_BSD_LCA "ｶｽﾀﾏｲｽﾞ表示有効－BSD/LCA警報
";
CM_ SG_ 552 RDR228_3_6_CSTM_DSP_BSD_LCA_2ND "ｶｽﾀﾏｲｽﾞ表示有効－BSD/LCA2次ﾌﾞｻﾞｰ
";
CM_ SG_ 552 RDR228_3_7_CSTM_DSP_RCTA "ｶｽﾀﾏｲｽﾞ表示有効－RCTA
";
CM_ SG_ 552 RDR228_2_0_CSTM_DSP_DOW "ｶｽﾀﾏｲｽﾞ表示有効－DOW
";
CM_ SG_ 552 RDR228_2_1_EYE_LOCAL_BUS1_FAIL "後側方ﾚｰﾀﾞ ｱｲｻｲﾄﾛｰｶﾙBUS1異常検知ﾌﾗｸﾞ
";
CM_ SG_ 552 RDR228_2_2_CSTM_DSP_DOW_SFT_POS "ｶｽﾀﾏｲｽﾞ表示有効－DOW有効ｼﾌﾄﾎﾟｼﾞｼｮﾝ
";
CM_ SG_ 552 RDR228_2_3_ELK_STOP_REQ_FLG "後側方ﾚｰﾀﾞELK停止要求ﾌﾗｸﾞ
";
CM_ SG_ 552 RDR228_2_4_FAIL_RDRSYS "後側方ﾚｰﾀﾞｼｽﾃﾑﾌｪｰﾙﾌﾗｸﾞ
";
CM_ SG_ 552 RDR228_2_5_STOP_RDRSYS "後側方ﾚｰﾀﾞｼｽﾃﾑ一時停止ﾌﾗｸﾞ
";
CM_ SG_ 552 RDR228_2_6_ON_OFF_RDRSYS "後側方ﾚｰﾀﾞｼｽﾃﾑON-OFFﾌﾗｸﾞ
";
CM_ SG_ 552 RDR228_2_7_BLOCKAGE_FORMING "ﾌﾞﾛｯｹｰｼﾞ条件成立ﾌﾗｸﾞ
";
CM_ SG_ 552 RDR228_1_0_MSG_COUNTER "ﾒｯｾｰｼﾞｶｳﾝﾀ
";
CM_ SG_ 552 RDR228_1_4_BATT_OFF_CAUSE "DOW電源OFF要求ﾌﾗｸﾞ
";
CM_ SG_ 552 RDR228_1_5_CSTM_GLO_1 "ｶｽﾀﾏｲｽﾞ表示ｸﾞﾚｰｱｳﾄ－1
";
CM_ SG_ 552 RDR228_1_6_CSTM_GLO_3 "ｶｽﾀﾏｲｽﾞ表示ｸﾞﾚｰｱｳﾄ－3
";
CM_ SG_ 552 RDR228_1_7_CSTM_GLO_2 "ｶｽﾀﾏｲｽﾞ表示ｸﾞﾚｰｱｳﾄ－2
";
CM_ SG_ 552 RDR228_0_0_CHECK_SUM "ﾁｪｯｸｻﾑ
";
CM_ SG_ 1372 RCR55C_7_0_NETWORK_STATUS "ﾈｯﾄﾜｰｸｽﾃｰﾀｽ
";
CM_ SG_ 1371 RCR55B_7_0_NETWORK_STATUS "ﾈｯﾄﾜｰｸｽﾃｰﾀｽ
";
CM_ SG_ 1359 SNR54F_0_0_NETWORK_STATUS "ﾈｯﾄﾜｰｸｽﾃｰﾀｽ
";
CM_ SG_ 966 EYE3C6_7_0_VEHICLE_DIST_L_LANE1 "左車線先行車１縦位置
";
CM_ SG_ 966 EYE3C6_7_7_VEHICLE_L_LANE1 "左車線先行車１
";
CM_ SG_ 966 EYE3C6_6_0_VEHICLE_DIST_R_LANE1 "右車線先行車１縦位置
";
CM_ SG_ 966 EYE3C6_6_7_VEHICLE_R_LANE1 "右車線先行車１
";
CM_ SG_ 966 EYE3C6_5_0_VEHICLE_DIST_WY_WAY1 "自車線先行車１縦位置
";
CM_ SG_ 966 EYE3C6_5_7_VEHICLE_MY_WAY1 "自車線先行車１
";
CM_ SG_ 966 EYE3C6_4_0_SIDE_MOVEMENT "自車表示_位置
";
CM_ SG_ 966 EYE3C6_3_0_RADER_RR "後側方レーダ-_右
";
CM_ SG_ 966 EYE3C6_3_2_RADER_RL "後側方レーダ-_左
";
CM_ SG_ 966 EYE3C6_3_4_RADER_FR "前側方レーダ-_右
";
CM_ SG_ 966 EYE3C6_3_6_RADER_FL "前側方レーダ-_左
";
CM_ SG_ 966 EYE3C6_2_0_RADER_R "後方レーダ-
";
CM_ SG_ 966 EYE3C6_2_2_MY_WAY_LANE_CAR_COLOR "自車線車両色
";
CM_ SG_ 966 EYE3C6_2_4_TARGET_CAR "先行車ターゲット
";
CM_ SG_ 966 EYE3C6_2_7_ALC_STS "ALC状態
";
CM_ SG_ 966 EYE3C6_1_0_MSG_COUNTER "ﾒｯｾｰｼﾞｶｳﾝﾀ
";
CM_ SG_ 966 EYE3C6_1_4_L_LANE_CAR_COLOR "左車線車両色
";
CM_ SG_ 966 EYE3C6_1_6_R_LANE_CAR_COLOR "右車線車両色
";
CM_ SG_ 966 EYE3C6_0_0_CHECK_SUM "ﾁｪｯｸｻﾑ
";
CM_ SG_ 965 EYE3C5_7_0_GSR_AEBS_FUNC_INFO "GSR-AEBS機能有無フラグ
";
CM_ SG_ 965 EYE3C5_7_1_CSTM_CRV_ADJUST "カスタマイズ現在値(カーブ前減速度調整機能)
";
CM_ SG_ 965 EYE3C5_7_3_BRAKE_HAPTIC_CURR "カスタマイズ現在値設定(ブレーキハプティック)
";
CM_ SG_ 965 EYE3C5_7_5_SAFETY_MODE_FUNC_INFO "障害物なし加速抑制機能有無フラグ
";
CM_ SG_ 965 EYE3C5_7_6_SAFETY_MODE_CURR "カスタマイズ現在値設定(障害物なし加速抑制)
";
CM_ SG_ 965 EYE3C5_7_7_GSR_DDAW_FUNC_INFO "GSR-DDAW機能有無フラグ
";
CM_ SG_ 965 EYE3C5_6_0_IND_SAFETY_MODE "アクセル急踏み加速抑制機能ON灯
";
CM_ SG_ 965 EYE3C5_6_1_ALC_ACTIVE_L "ALC制御中表示_左
";
CM_ SG_ 965 EYE3C5_6_2_FLASHING_IND_SAFETY "安全重視モード点滅表示指示
";
CM_ SG_ 965 EYE3C5_6_3_OVERTAKE_FUNC_INFO "追い抜き抑制制御有無フラグ
";
CM_ SG_ 965 EYE3C5_6_4_CRV_ADJUST_FUNC_INFO "カーブ前減速度調整機能有無フラグ
";
CM_ SG_ 965 EYE3C5_6_5_STRG_TOUCHSENSOR_WRNG "ステアリングタッチセンサ故障灯
";
CM_ SG_ 965 EYE3C5_6_6_ALC_ACTIVE_R "ALC制御中表示_右
";
CM_ SG_ 965 EYE3C5_6_7_CSTM_GSR_ISA "GSR-ISA有無フラグ
";
CM_ SG_ 965 EYE3C5_5_0_LANE_COLOR_R "隣レーン色_右
";
CM_ SG_ 965 EYE3C5_5_2_LINE_LANE_R "隣外側車線表示_右
";
CM_ SG_ 965 EYE3C5_5_4_LANE_COLOR_L "隣レーン色_左
";
CM_ SG_ 965 EYE3C5_5_6_LINE_LANE_L "隣外側車線表示_左
";
CM_ SG_ 965 EYE3C5_4_0_ROAD_SHAPE_CURVE "道路形状_湾曲
";
CM_ SG_ 965 EYE3C5_4_4_ROAD_SHAPE_DIRECTION "道路形状_方向
";
CM_ SG_ 965 EYE3C5_4_5_CSTM_GSR_ELKS "GSR-ELKS有無フラグ
";
CM_ SG_ 965 EYE3C5_4_6_MY_WAY_COLOR "自レーンの色
";
CM_ SG_ 965 EYE3C5_3_0_AD_DRV_ICON "高度運転支援アイコン
";
CM_ SG_ 965 EYE3C5_3_2_AUTO_HANDLE_ICON "AUTOハンドルアイコン
";
CM_ SG_ 965 EYE3C5_3_4_WITH_HANDS_ICON "ハンズオン/ハンズオフ表示
";
CM_ SG_ 965 EYE3C5_3_5_STRG_HAPTIC_WRNG "ステアリングハプティック故障灯
";
CM_ SG_ 965 EYE3C5_3_6_BRK_HPTC_FUNC_INFO "ブレーキハプティック機能有無フラグ
";
CM_ SG_ 965 EYE3C5_3_7_SPECIAL_DISP_INFO "特殊標識表示機能有無フラグ
";
CM_ SG_ 965 EYE3C5_2_0_SLOWDWN_CURVE_ICON "カーブ前減速アイコン
";
CM_ SG_ 965 EYE3C5_2_3_FLASHING_IND "自車点滅指示
";
CM_ SG_ 965 EYE3C5_2_4_ATTENTION_TOLLGATE "料金所注意アイコン
";
CM_ SG_ 965 EYE3C5_2_6_MAPLOCATOR_IND "ロケータインジケータ
";
CM_ SG_ 965 EYE3C5_1_0_MSG_COUNTER "ﾒｯｾｰｼﾞｶｳﾝﾀ
";
CM_ SG_ 965 EYE3C5_1_4_ISA_FAIL_IND "ISA故障灯
";
CM_ SG_ 965 EYE3C5_1_5_SLWF_OFF_IND "SLWFOFF灯
";
CM_ SG_ 965 EYE3C5_1_6_CSTM_SLWF_SET "カスタマイズ現在値(SLWF)
";
CM_ SG_ 965 EYE3C5_1_7_CSTM_TSR_SOUND_SET "カスタマイズ現在値(標識切り替わり警報音)
";
CM_ SG_ 965 EYE3C5_0_0_CHECK_SUM "ﾁｪｯｸｻﾑ
";
CM_ SG_ 964 EYE3C4_7_0_PCR_FAIL_OFF_IND "プリクラ故障/OFF灯指示
";
CM_ SG_ 964 EYE3C4_7_2_AES_FAIL_OFF_IND "AES故障/OFF灯指示
";
CM_ SG_ 964 EYE3C4_7_4_LDP_FAIL_OFF_IND "LDP故障/OFF灯指示
";
CM_ SG_ 964 EYE3C4_7_6_ELK_FAIL_OFF_IND "ELK故障/OFF灯指示
";
CM_ SG_ 964 EYE3C4_6_0_MCAM_SYS_FAIL_HALT "単眼故障状態通知(HALT/FAIL)
";
CM_ SG_ 964 EYE3C4_6_2_MCAM_FUNC_INFO "単眼機能有無フラグ
";
CM_ SG_ 964 EYE3C4_6_3_EYE_DRV_ACTION_REQ "アイサイトドライバアクション要求
";
CM_ SG_ 964 EYE3C4_6_6_LDW_SND_OFF_FAIL_IND "LDW音OFF灯/SW故障警告表示
";
CM_ SG_ 964 EYE3C4_5_0_EAM_GREEN "EAM点灯指示　緑
";
CM_ SG_ 964 EYE3C4_5_2_EAM_BLUE "EAM点灯指示　青
";
CM_ SG_ 964 EYE3C4_5_4_EAM_GREEN_2 "EAM点灯指示_緑2
";
CM_ SG_ 964 EYE3C4_5_6_FCW_SND_OFF_FAIL_IND "FCW音OFF灯/SW故障警告表示
";
CM_ SG_ 964 EYE3C4_4_0_EAM_YELLOW "EAM点灯指示　黄
";
CM_ SG_ 964 EYE3C4_4_4_EAM_RED "EAM点灯指示　赤
";
CM_ SG_ 964 EYE3C4_3_0_CODE_NO_BUZZER "警報コード（表示のみ）
";
CM_ SG_ 964 EYE3C4_2_0_CODE_WARN "警報コード（音有）
";
CM_ SG_ 964 EYE3C4_1_0_MSG_COUNTER "ﾒｯｾｰｼﾞｶｳﾝﾀ
";
CM_ SG_ 964 EYE3C4_1_5_SNR_DRV_ACTION_REQ "ソナードライバアクション要求
";
CM_ SG_ 964 EYE3C4_0_0_CHECK_SUM "ﾁｪｯｸｻﾑ
";
CM_ SG_ 805 EYE325_6_5_SONAR_DISP_INT "ｸﾘｿﾅ割り込み表示ﾌﾗｸﾞ
";
CM_ SG_ 805 EYE325_5_0_SONAR_R_L_CORNER_4LVL "リアソナー距離警報情報(左コーナー4段階)
";
CM_ SG_ 805 EYE325_5_3_SONAR_R_R_CORNER_4LVL "リアソナー距離警報情報(右コーナー4段階)
";
CM_ SG_ 805 EYE325_4_0_SONAR_R_CENTER "ﾘｱｿﾅｰ距離警報情報：Rcenter（中央4段階）
";
CM_ SG_ 805 EYE325_4_3_SONAR_LEVEL "RAB/ｸﾘｿﾅ警報音ﾚﾍﾞﾙ
";
CM_ SG_ 805 EYE325_4_6_RAB_WARNING "RAB警報割込み表示指示
";
CM_ SG_ 805 EYE325_3_0_SONAR_R_L_CORNER "ﾘｱｿﾅｰ距離警報情報：RLConner（左ｺｰﾅ3段階）
";
CM_ SG_ 805 EYE325_3_2_SONAR_R_R_CORNER "ﾘｱｿﾅｰ距離警報情報：RRConner（右ｺｰﾅ3段階）
";
CM_ SG_ 805 EYE325_3_4_SONAR_R_L_SIDE "ﾘｱｿﾅｰ距離警報情報：RLSide（左ｻｲﾄﾞ3段階：予約）
";
CM_ SG_ 805 EYE325_3_6_SONAR_R_R_SIDE "ﾘｱｿﾅｰ距離警報情報：RRSide（右ｻｲﾄﾞ3段階：予約）
";
CM_ SG_ 805 EYE325_2_0_RAB_OFF "RAB 機能OFF状態通知
";
CM_ SG_ 805 EYE325_2_1_SONAR_OFF "警報音機能OFF状態通知
";
CM_ SG_ 805 EYE325_2_2_SONAR_SYS_HALT "ｿﾅｰｼｽﾃﾑ一時停止状態通知 (Fault)
";
CM_ SG_ 805 EYE325_2_4_SONAR_SYS_FAIL "ｿﾅｰｼｽﾃﾑ故障状態通知 (Fail)
";
CM_ SG_ 805 EYE325_2_6_RAB_DISABLE "RAB機能一時OFF操作不可
";
CM_ SG_ 805 EYE325_2_7_SONAR_DISABLE "警報音一時OFF操作不可
";
CM_ SG_ 805 EYE325_1_0_MSG_COUNTER "ﾒｯｾｰｼﾞｶｳﾝﾀ
";
CM_ SG_ 805 EYE325_1_4_CSTM_RAB_SET "SNRｶｽﾀﾏｲｽﾞ現在値設定(RAB機能)
";
CM_ SG_ 805 EYE325_1_5_CSTM_CLR_SNR_SET "SNRｶｽﾀﾏｲｽﾞ現在値設定(ｸﾘｱﾗﾝｽｿﾅｰ機能)
";
CM_ SG_ 805 EYE325_1_6_RAB "RAB機能設定ﾌﾗｸﾞ
";
CM_ SG_ 805 EYE325_1_7_SONAR_NO_DISP "ｿﾅｰｼｽﾃﾑ画面非表示ﾌﾗｸﾞ
";
CM_ SG_ 805 EYE325_0_0_CHECK_SUM "ﾁｪｯｸｻﾑ
";
CM_ SG_ 804 EYE324_7_5_TSR_MODE_DISP "標識連動表示
";
CM_ SG_ 804 EYE324_7_7_ICON_IND "標識アイコン表示指示
";
CM_ SG_ 804 EYE324_6_0_COMPLEMENTARY_IND_C "補助標識情報表示指示（エリアC）
";
CM_ SG_ 804 EYE324_6_4_COMPLEMENTARY_IND_D "補助標識情報表示指示（エリアD）
";
CM_ SG_ 804 EYE324_5_0_SPEEDLIMIT_B "制限車速表示（エリアB）
";
CM_ SG_ 804 EYE324_4_0_TRAFFIC_SIGN_B "制限車速背景意匠&規制標識情報表示指示（エリアB）
";
CM_ SG_ 804 EYE324_4_5_FLASHING_IND_B "点滅表示指示（エリアB）
";
CM_ SG_ 804 EYE324_4_6_FRAME_COLOR_B "標識枠色（エリアB）
";
CM_ SG_ 804 EYE324_3_0_SPEEDLIMIT_A "制限車速表示（エリアA）
";
CM_ SG_ 804 EYE324_2_0_TRAFFIC_SIGN_A "制限車速背景意匠&規制標識情報表示指示（エリアA）
";
CM_ SG_ 804 EYE324_2_5_FLASHING_IND_A "点滅表示指示（エリアA）
";
CM_ SG_ 804 EYE324_2_6_FRAME_COLOR_A "標識枠色（エリアA）
";
CM_ SG_ 804 EYE324_1_0_MSG_COUNTER "ﾒｯｾｰｼﾞｶｳﾝﾀ
";
CM_ SG_ 804 EYE324_1_4_FLASHING_IND_D "点滅表示指示（エリアD）
";
CM_ SG_ 804 EYE324_1_5_FLASHING_IND_C "点滅表示指示（エリアC）
";
CM_ SG_ 804 EYE324_1_6_ICON_COLOR "標識アイコン色
";
CM_ SG_ 804 EYE324_0_0_CHECK_SUM "ﾁｪｯｸｻﾑ
";
CM_ SG_ 803 EYE323_7_0_ISA_OFFSET_CURR "ISA制限車速オフセット値
";
CM_ SG_ 803 EYE323_7_5_SLIF_FUNC_INFO "標識認識機能有無情報
";
CM_ SG_ 803 EYE323_7_6_ISA_FUNC_INFO "ISA機能有無情報
";
CM_ SG_ 803 EYE323_7_7_ISA_CUSTOMIZE_CURR "ｱｲｻｲﾄｶｽﾀﾏｲｽﾞ現在設定値(ISA)
";
CM_ SG_ 803 EYE323_6_0_LDW_OFFSW_INFO "LDW音　OFFスイッチ有無
";
CM_ SG_ 803 EYE323_6_1_LDW_ON_OFF_SET "LDW音 ON/OFF現在設定値
";
CM_ SG_ 803 EYE323_6_2_CSTM_DDAW_WARN_SET "カスタマイズ現在値(DDAW警報)
";
CM_ SG_ 803 EYE323_6_3_IACC_FUNC_INFO "iACC機能有無フラグ
";
CM_ SG_ 803 EYE323_6_5_CSTM_LDW_TIMING_SET "LDWタイミングカスタマイズ現在設定値
";
CM_ SG_ 803 EYE323_6_6_CSTM_LDW_TIMING "LDWタイミングカスタマイズ有無
";
CM_ SG_ 803 EYE323_6_7_SLOWDOWNL_FUNC_INFO "カーブ前減速機能有無
";
CM_ SG_ 803 EYE323_5_0_CNG_GRN_CONT_CURR "カスタマイズ現在値（青信号切り替わりお知らせ）
";
CM_ SG_ 803 EYE323_5_1_TRAFFIC_FUNC_INFO "信号制御機能有無
";
CM_ SG_ 803 EYE323_5_2_FCW_OFFSW_INFO "FCW OFFスイッチ有無
";
CM_ SG_ 803 EYE323_5_3_FCW_ON_OFF_SET "FCW ON/OFF現在設定値
";
CM_ SG_ 803 EYE323_5_4_WARNING_SEL_CURR "カスタマイズ現在値（警報方法）
";
CM_ SG_ 803 EYE323_5_5_HAPT_FUNC_INFO "ステア振動（警報方法）機能有無
";
CM_ SG_ 803 EYE323_5_6_TOLLGATE_CONT_CURR "カスタマイズ現在値（料金所減速 ）
";
CM_ SG_ 803 EYE323_5_7_CURVE_CONT_CURR "カスタマイズ現在値（カーブ減速 ）
";
CM_ SG_ 803 EYE323_4_0_FCTB_ICON_L "FCTBお知らせアイコン_左
";
CM_ SG_ 803 EYE323_4_2_FCTB_ICON_R "FCTBお知らせアイコン_右
";
CM_ SG_ 803 EYE323_4_4_FCW_CONT_CURR "カスタマイズ現在値（FCW)
";
CM_ SG_ 803 EYE323_4_6_FCW_DISPLAY_SEL "FCWカスタマイズ項目表示指示
";
CM_ SG_ 803 EYE323_3_0_AES_FUNC_INFO "AES機能有無
";
CM_ SG_ 803 EYE323_3_1_CSTM_TSR_NO_ENTRY_SET "カスタマイズ現在値(進入禁止標識)
";
CM_ SG_ 803 EYE323_3_2_CSTM_TSR_STOP_SET "カスタマイズ現在値(一時停止標識)
";
CM_ SG_ 803 EYE323_3_3_CSTM_TSR_GIVE_WAY_SET "カスタマイズ現在値(前方優先道路標識)
";
CM_ SG_ 803 EYE323_3_4_WILDERNESS "Wilderness識別情報
";
CM_ SG_ 803 EYE323_3_5_AES_OFF "AES  OFFｲﾝｼﾞｹｰﾀ信号
";
CM_ SG_ 803 EYE323_3_6_FCTB_IND "FCTBインジケータ
";
CM_ SG_ 803 EYE323_2_0_CSTM_LDW_ALK_B "ｱｲｻｲﾄｶｽﾀﾏｲｽﾞ現在値設定（LDW/ALK-B）
";
CM_ SG_ 803 EYE323_2_2_CSTM_P_CR "ｱｲｻｲﾄｶｽﾀﾏｲｽﾞ現在値設定（P-CR）
";
CM_ SG_ 803 EYE323_2_3_SLOWDOWN_FUNC_INFO2 "料金所前減速機能有無
";
CM_ SG_ 803 EYE323_2_4_CID_CODE_WARN "CID警報ｺｰﾄﾞ
";
CM_ SG_ 803 EYE323_1_0_MSG_COUNTER "ﾒｯｾｰｼﾞｶｳﾝﾀ
";
CM_ SG_ 803 EYE323_1_4_DISP_FOLLOW_FORWARD "先行車追従表示フラグ
";
CM_ SG_ 803 EYE323_1_5_KEEP_LINE_SENTER_ACT "白線中央維持制御中フラグ
";
CM_ SG_ 803 EYE323_1_6_DDAW_FAIL_OFF "DDAW故障/OFF灯
";
CM_ SG_ 803 EYE323_0_0_CHECK_SUM "ﾁｪｯｸｻﾑ
";
CM_ SG_ 802 EYE322_7_0_CSTM_ACC_CONT_SET "ｱｲｻｲﾄｶｽﾀﾏｲｽﾞ現在値設定（ACC加速特性）
";
CM_ SG_ 802 EYE322_7_2_ELK_OFF_IND "ELK OFF灯表示
";
CM_ SG_ 802 EYE322_7_3_LIGHT_EAM_YELLOW "EAM(黄)点灯指示
";
CM_ SG_ 802 EYE322_7_5_BROKEN_LINE_L "車線表示切替_左
";
CM_ SG_ 802 EYE322_7_6_TJA_ACTIVE "TJA作動中フラグ
";
CM_ SG_ 802 EYE322_7_7_BROKEN_LINE_R "車線表示切替_右
";
CM_ SG_ 802 EYE322_6_0_CSTM_MIS_AT_START "ｱｲｻｲﾄｶｽﾀﾏｲｽﾞ現在設定値(AT誤後進抑制制御)
";
CM_ SG_ 802 EYE322_6_2_CSTM_ALK_TJA_SET "ｱｲｻｲﾄｶｽﾀﾏｲｽﾞ現在値設定(車線中央維持・TJA)
";
CM_ SG_ 802 EYE322_6_3_CSTM_LANE_SET "ｱｲｻｲﾄｶｽﾀﾏｲｽﾞ現在設定値（通行車線）
";
CM_ SG_ 802 EYE322_6_4_LDP_OFF_IND "LDP OFF灯表示
";
CM_ SG_ 802 EYE322_6_5_INDICATOR_MODE_L "左側ミラーインジケータ制御指示フラグ
";
CM_ SG_ 802 EYE322_6_7_CSTM_ELK_SET "ｱｲｻｲﾄｶｽﾀﾏｲｽﾞ現在設定値（ELK)
";
CM_ SG_ 802 EYE322_5_0_CSTM_MIS_AT_BACK "ｱｲｻｲﾄ機能有無情報(AT誤後進抑制制御)
";
CM_ SG_ 802 EYE322_5_1_CSTM_ALK_TJA "ｱｲｻｲﾄ機能有無情報(車線中央維持・TJA)
";
CM_ SG_ 802 EYE322_5_2_CSTM_SAS "ｱｲｻｲﾄ機能有無情報(SAS)
";
CM_ SG_ 802 EYE322_5_3_CSTM_HBA "ｱｲｻｲﾄ機能有無情報(HBA)
";
CM_ SG_ 802 EYE322_5_4_CSTM_ACC_CONT "ｱｲｻｲﾄ機能有無情報(ACC加速特性)
";
CM_ SG_ 802 EYE322_5_5_CSTM_LANE "ｱｲｻｲﾄ機能有無情報（通行車線）
";
CM_ SG_ 802 EYE322_5_6_LDW_SOUND_OFF_IND "LDW音 OFF灯表示
";
CM_ SG_ 802 EYE322_5_7_CSTM_ELK_SET "ｱｲｻｲﾄ機能有無情報（ELK）
";
CM_ SG_ 802 EYE322_4_0_CODE_WARN "警報ｺｰﾄﾞ（音有り）
";
CM_ SG_ 802 EYE322_4_5_CSTM_GSR "GSR対応有無フラグ
";
CM_ SG_ 802 EYE322_3_0_LANE_L "車線左表示
";
CM_ SG_ 802 EYE322_3_2_LANE_R "車線右表示
";
CM_ SG_ 802 EYE322_3_4_LANE_L_COLOR "車線左色
";
CM_ SG_ 802 EYE322_3_6_LANE_R_COLOR "車線右色
";
CM_ SG_ 802 EYE322_2_0_FCW_OFF_IND "FCW OFF灯表示
";
CM_ SG_ 802 EYE322_2_1_MOV_EYESIGHT_SCREEN "ｱｲｻｲﾄ画面移行ﾌﾗｸﾞ(ID322)
";
CM_ SG_ 802 EYE322_2_2_ALK_ICON "ALK表示
";
CM_ SG_ 802 EYE322_2_4_INDICATOR_CTRL_REQ "ミラーインジケータ制御フラグ
";
CM_ SG_ 802 EYE322_2_5_INDICATOR_MODE_R "右側ミラーインジケータ制御指示フラグ
";
CM_ SG_ 802 EYE322_2_7_LIMITER_BACK_SPEED "後退速度ﾘﾐｯﾀｰ設定値表示
";
CM_ SG_ 802 EYE322_1_0_MSG_COUNTER "ﾒｯｾｰｼﾞｶｳﾝﾀ
";
CM_ SG_ 802 EYE322_1_4_CODE_NO_BUZZER "警報ｺｰﾄﾞ（表示のみ）
";
CM_ SG_ 802 EYE322_1_7_DISTWARN_DMS "車間距離警報早鳴りﾌﾗｸﾞ
";
CM_ SG_ 802 EYE322_0_0_CHECK_SUM "ﾁｪｯｸｻﾑ
";
CM_ SG_ 801 EYE321_7_0_INFO_DIST_FORWARD "先行車距離
";
CM_ SG_ 801 EYE321_7_4_INFO_KEEP_STOP "停止保持中(HOLD)表示
";
CM_ SG_ 801 EYE321_7_5_INFO_READY "READY表示
";
CM_ SG_ 801 EYE321_7_6_INFO_SET_CC "ｸﾙｺﾝSET表示
";
CM_ SG_ 801 EYE321_7_7_INFO_OFF "OFF表示
";
CM_ SG_ 801 EYE321_6_0_FAIL_EYESIGHT "ｱｲｻｲﾄﾌｪｰﾙﾌﾗｸﾞ
";
CM_ SG_ 801 EYE321_6_1_MOV_EYESIGHT_SCREEN "ｱｲｻｲﾄ画面移行ﾌﾗｸﾞ(ID321)
";
CM_ SG_ 801 EYE321_6_2_IND_VEHICLE "自車表示
";
CM_ SG_ 801 EYE321_6_3_BRAKELAMP_VEHICLE "自車ﾌﾞﾚｰｷﾗﾝﾌﾟ点灯状態
";
CM_ SG_ 801 EYE321_6_4_IND_FORWARD_VECL "先行車表示
";
CM_ SG_ 801 EYE321_6_5_BRAKELAMP_FORWARD "先行車ﾌﾞﾚｰｷﾗﾝﾌﾟ点灯状態
";
CM_ SG_ 801 EYE321_6_6_CC_OR_LIM_SON "ｸﾙｺﾝ・ﾘﾐｯﾀｾｯﾄ状態
";
CM_ SG_ 801 EYE321_6_7_TEMP_OFF_STATE "一括一時OFF状態
";
CM_ SG_ 801 EYE321_5_0_INFO_SET_SPD "ｾｯﾄ車速表示
";
CM_ SG_ 801 EYE321_4_0_ACC_MODE "ACC/CC/SASﾓｰﾄﾞﾌﾗｸﾞ
";
CM_ SG_ 801 EYE321_4_2_SRVD_LASTMEM_ST_REQ "SRVDラストメモリ起動要求フラグ
";
CM_ SG_ 801 EYE321_4_3_INFO_MAIN_CC "ｸﾙｺﾝﾒｲﾝ表示
";
CM_ SG_ 801 EYE321_4_5_TRAFFIC_LIGHT "信号表示
";
CM_ SG_ 801 EYE321_3_0_CODE_HALT "ＨＡＬＴｺｰﾄﾞ
";
CM_ SG_ 801 EYE321_3_3_ELK_EQUIP "ELK機能有無
";
CM_ SG_ 801 EYE321_3_4_SET_DIST "車間距離設定表示
";
CM_ SG_ 801 EYE321_3_7_TJA "TJA機能有無
";
CM_ SG_ 801 EYE321_2_0_ACC_CANCEL_OR_CSTM "ｸﾙｺﾝｷｬﾝｾﾙ理由表示
";
CM_ SG_ 801 EYE321_2_4_ALK_CANCEL_OR_CSTM "ALKｷｬﾝｾﾙ理由表示
";
CM_ SG_ 801 EYE321_2_7_ALK_CANCEL_DISP_TYPE "ALKｷｬﾝｾﾙ表示種別
";
CM_ SG_ 801 EYE321_1_0_MSG_COUNTER "ﾒｯｾｰｼﾞｶｳﾝﾀ
";
CM_ SG_ 801 EYE321_1_4_PRECRASH_BRAKE_OFF "ﾌﾟﾘｸﾗｯｼｭﾌﾞﾚｰｷOFFｲﾝｼﾞｹｰﾀON flg
";
CM_ SG_ 801 EYE321_1_5_LANE_DEPARTURE_OFF "車線逸脱警報OFFｲﾝｼﾞｹｰﾀON flg
";
CM_ SG_ 801 EYE321_1_6_MET_AD_DRV_ASS "MET用高度運転支援有無ﾌﾗｸﾞ
";
CM_ SG_ 801 EYE321_1_7_ALC_EQUIP "ALC機能有無フラグ
";
CM_ SG_ 801 EYE321_0_0_CHECK_SUM "ﾁｪｯｸｻﾑ
";
CM_ SG_ 289 EYE121_4_0_TARGET_FLUID_PRESS "目標液圧
";
CM_ SG_ 289 EYE121_3_0_RAB_TRQ_LIM_STAT "RAB加速抑制制御状態（ｱｲｻｲﾄ）
";
CM_ SG_ 289 EYE121_3_4_RAB_BRAKE_STAT "RABﾌﾞﾚｰｷ制御状態（ｱｲｻｲﾄ）
";
CM_ SG_ 289 EYE121_2_0_EYE_INIT "Eyesight初期化完了ﾌﾗｸﾞ
";
CM_ SG_ 289 EYE121_2_1_RAB_ACT_OK "後退制御許可ﾌﾗｸﾞ
";
CM_ SG_ 289 EYE121_2_2_RAB_FAIL "RABﾌｪｰﾙ指示
";
CM_ SG_ 289 EYE121_2_3_RAB_OFF "RAB OFF指示
";
CM_ SG_ 289 EYE121_2_4_FMWR_ACTIVE "FMWR制御中フラグ
";
CM_ SG_ 289 EYE121_1_0_MSG_COUNTER "ﾒｯｾｰｼﾞｶｳﾝﾀ
";
CM_ SG_ 289 EYE121_1_7_EQUIP_EPB "EPB装備有無
";
CM_ SG_ 289 EYE121_0_0_CHECK_SUM "ﾁｪｯｸｻﾑ
";
CM_ SG_ 1352 EYE548_7_0_NETWORK_STATUS "ﾈｯﾄﾜｰｸｽﾃｰﾀｽ
";
CM_ SG_ 287 ADAS11F_7_0_SND_MAC "送信用MAC
";
CM_ SG_ 287 ADAS11F_4_4_RESET_FLG "ﾘｾｯﾄﾌﾗｸﾞ
";
CM_ SG_ 287 ADAS11F_4_6_SNDMSG_CNT "送信用ﾒｯｾｰｼﾞｶｳﾝﾀ
";
CM_ SG_ 287 ADAS11F_3_0_MSG_COUNTER "ﾒｯｾｰｼﾞｶｳﾝﾀ
";
CM_ SG_ 287 ADAS11F_3_4_HANDSOFF_FLG "ﾊﾝｽﾞｵﾌﾌﾗｸﾞ
";
CM_ SG_ 287 ADAS11F_3_5_TRQ_LIMIT_REQ_FLG "舵角制御ﾄﾙｸ制限要求ﾌﾗｸﾞ
";
CM_ SG_ 287 ADAS11F_2_0_STEER_ANGLE_OFFSET "ﾊﾝﾄﾞﾙ角 ｵﾌｾｯﾄ補償値
";
CM_ SG_ 292 ADAS124_7_3_TRQ_RATE_CHG "指示トルクレート切り替えフラグ
";
CM_ SG_ 292 ADAS124_7_4_STR_RATE_CHG "指示舵角レート切り替えフラグ
";
CM_ SG_ 292 ADAS124_7_6_OVR_STR_LVL "オーバーライド舵力可変フラグ
";
CM_ SG_ 292 ADAS124_5_0_HNDR_RECDEG "指示ハンドル角
";
CM_ SG_ 292 ADAS124_3_0_STR_OFFSET "ハンドル角 オフセット補償値
";
CM_ SG_ 292 ADAS124_1_0_MSG_COUNTER "ﾒｯｾｰｼﾞｶｳﾝﾀ
";
CM_ SG_ 292 ADAS124_1_4_ACTIVE_FLG "アクティブフラグ
";
CM_ SG_ 292 ADAS124_0_0_CHECK_SUM "ﾁｪｯｸｻﾑ
";
CM_ SG_ 471 MVS1D7_15_0_Y_CRD4 "リヤカメラサイクリスト検知座標Y4
";
CM_ SG_ 471 MVS1D7_14_0_X_CRD4 "リヤカメラサイクリスト検知座標X4
";
CM_ SG_ 471 MVS1D7_13_0_UD_CNT4 "リヤカメラサイクリスト検知更新カウンタ4
";
CM_ SG_ 471 MVS1D7_13_2_CAM_LVL4 "リヤカメラサイクリスト検知信頼度4
";
CM_ SG_ 471 MVS1D7_13_4_TRG_ID4 "リヤカメラサイクリスト検知物標ID4
";
CM_ SG_ 471 MVS1D7_12_0_Y_CRD3 "リヤカメラサイクリスト検知座標Y3
";
CM_ SG_ 471 MVS1D7_11_0_X_CRD3 "リヤカメラサイクリスト検知座標X3
";
CM_ SG_ 471 MVS1D7_10_0_UD_CNT3 "リヤカメラサイクリスト検知更新カウンタ3
";
CM_ SG_ 471 MVS1D7_10_2_CAM_LVL3 "リヤカメラサイクリスト検知信頼度3
";
CM_ SG_ 471 MVS1D7_10_4_TRG_ID3 "リヤカメラサイクリスト検知物標ID3
";
CM_ SG_ 471 MVS1D7_8_0_Y_CRD2 "リヤカメラサイクリスト検知座標Y2
";
CM_ SG_ 471 MVS1D7_7_0_X_CRD2 "リヤカメラサイクリスト検知座標X2
";
CM_ SG_ 471 MVS1D7_6_0_UD_CNT2 "リヤカメラサイクリスト検知更新カウンタ2
";
CM_ SG_ 471 MVS1D7_6_2_CAM_LVL2 "リヤカメラサイクリスト検知信頼度2
";
CM_ SG_ 471 MVS1D7_6_4_TRG_ID2 "リヤカメラサイクリスト検知物標ID2
";
CM_ SG_ 471 MVS1D7_5_0_Y_CRD1 "リヤカメラサイクリスト検知座標Y1
";
CM_ SG_ 471 MVS1D7_4_0_X_CRD1 "リヤカメラサイクリスト検知座標X1
";
CM_ SG_ 471 MVS1D7_3_0_UD_CNT1 "リヤカメラサイクリスト検知更新カウンタ１
";
CM_ SG_ 471 MVS1D7_3_2_CAM_LVL1 "リヤカメラサイクリスト検知信頼度1
";
CM_ SG_ 471 MVS1D7_3_4_TRG_ID1 "リヤカメラサイクリスト検知物標ID1
";
CM_ SG_ 471 MVS1D7_2_0_E2E_COUNTER "E2Eｶｳﾝﾀ
";
CM_ SG_ 471 MVS1D7_0_0_E2E_CRC "CRC
";
CM_ SG_ 470 MVS1D6_16_4_CMDHALT "リヤカメラ歩行者検知一時停止状態
";
CM_ SG_ 470 MVS1D6_16_6_CMDFAIL "リヤカメラ歩行者検知異常状態
";
CM_ SG_ 470 MVS1D6_15_0_Y_CRD4 "リヤカメラ歩行者検知座標Y4
";
CM_ SG_ 470 MVS1D6_14_0_X_CRD4 "リヤカメラ歩行者検知座標X4
";
CM_ SG_ 470 MVS1D6_13_0_UD_CNT4 "リヤカメラ歩行者検知更新カウンタ4
";
CM_ SG_ 470 MVS1D6_13_2_CAM_LVL4 "リヤカメラ歩行者検知信頼度4
";
CM_ SG_ 470 MVS1D6_13_4_TRG_ID4 "リヤカメラ歩行者検知物標ID4
";
CM_ SG_ 470 MVS1D6_12_0_Y_CRD3 "リヤカメラ歩行者検知座標Y3
";
CM_ SG_ 470 MVS1D6_11_0_X_CRD3 "リヤカメラ歩行者検知座標X3
";
CM_ SG_ 470 MVS1D6_10_0_UD_CNT3 "リヤカメラ歩行者検知更新カウンタ3
";
CM_ SG_ 470 MVS1D6_10_2_CAM_LVL3 "リヤカメラ歩行者検知信頼度3
";
CM_ SG_ 470 MVS1D6_10_4_TRG_ID3 "リヤカメラ歩行者検知物標ID3
";
CM_ SG_ 470 MVS1D6_8_0_Y_CRD2 "リヤカメラ歩行者検知座標Y2
";
CM_ SG_ 470 MVS1D6_7_0_X_CRD2 "リヤカメラ歩行者検知座標X2
";
CM_ SG_ 470 MVS1D6_6_0_UD_CNT2 "リヤカメラ歩行者検知更新カウンタ2
";
CM_ SG_ 470 MVS1D6_6_2_CAM_LVL2 "リヤカメラ歩行者検知信頼度2
";
CM_ SG_ 470 MVS1D6_6_4_TRG_ID2 "リヤカメラ歩行者検知物標ID2
";
CM_ SG_ 470 MVS1D6_5_0_Y_CRD1 "リヤカメラ歩行者検知座標Y1
";
CM_ SG_ 470 MVS1D6_4_0_X_CRD1 "リヤカメラ歩行者検知座標X1
";
CM_ SG_ 470 MVS1D6_3_0_UD_CNT1 "リヤカメラ歩行者検知更新カウンタ１
";
CM_ SG_ 470 MVS1D6_3_2_CAM_LVL1 "リヤカメラ歩行者検知信頼度1
";
CM_ SG_ 470 MVS1D6_3_4_TRG_ID1 "リヤカメラ歩行者検知物標ID1
";
CM_ SG_ 470 MVS1D6_2_0_E2E_COUNTER "E2Eｶｳﾝﾀ
";
CM_ SG_ 470 MVS1D6_0_0_E2E_CRC "CRC
";
CM_ SG_ 279 SNR117_16_0_CSTM_SNR_DSPREEQ "カスタマイズ表示要求(クリソナON/OFF)
";
CM_ SG_ 279 SNR117_16_2_CSTM_RAB_DSPREQ "カスタマイズ表示要求(RAB ON/OFF)
";
CM_ SG_ 279 SNR117_16_4_CSTM_PED_DSPREQ "カスタマイズ表示要求(歩行者RAB ON/OFF)
";
CM_ SG_ 279 SNR117_16_6_CSTM_PEDTIM_DSPREQ "カスタマイズ表示要求(歩行者RABタイミング)
";
CM_ SG_ 279 SNR117_15_0_CSTM_SNR_CLEAR "SNRｶｽﾀﾏｲｽﾞ現在値設定(ｸﾘｱﾗﾝｽｿﾅｰ機能)
";
CM_ SG_ 279 SNR117_15_1_CSTM_RAB "SNRｶｽﾀﾏｲｽﾞ現在値設定(RAB機能)
";
CM_ SG_ 279 SNR117_15_2_CSTM_RAB_PED "SNRｶｽﾀﾏｲｽﾞ現在値設定(歩行者RAB機能)
";
CM_ SG_ 279 SNR117_15_3_CSTM_RAB_PED_TIMING "SNRｶｽﾀﾏｲｽﾞ現在値設定(歩行者RABタイミング)
";
CM_ SG_ 279 SNR117_14_0_RAB_WARNING "割り込み表示要求
";
CM_ SG_ 279 SNR117_14_3_SONAR_LEVEL "警報音指示
";
CM_ SG_ 279 SNR117_13_0_PED_WARN_CENTER "歩行者お知らせ中央表示
";
CM_ SG_ 279 SNR117_13_1_PED_WARN_LEFT "歩行者お知らせ左表示
";
CM_ SG_ 279 SNR117_13_2_PED_WARN_RIGHT "歩行者お知らせ右表示
";
CM_ SG_ 279 SNR117_13_3_RAB_TRIG_TYPE "RAB作動トリガ種類
";
CM_ SG_ 279 SNR117_9_0_SONAR_R_R_CORNER_4LV "リアソナー距離警報情報(右コーナー4段階)
";
CM_ SG_ 279 SNR117_8_0_SONAR_DISP_INT "クリソナ割り込み表示要求
";
CM_ SG_ 279 SNR117_8_1_SONAR_R_CENTER "ﾘｱｿﾅｰ距離警報情報：Rcenter（中央4段階）
";
CM_ SG_ 279 SNR117_8_4_SONAR_R_L_CORNER_4LV "リアソナー距離警報情報(左コーナー4段階)
";
CM_ SG_ 279 SNR117_7_0_SONAR_SYS_FAIL "ｿﾅｰｼｽﾃﾑ故障状態通知 (FAIL)
";
CM_ SG_ 279 SNR117_7_2_RAB_HALT "RAB一時停止状態通知 (HALT)
";
CM_ SG_ 279 SNR117_7_4_CAMERA_FAIL "ｶﾒﾗｼｽﾃﾑ故障状態通知(FAIL)
";
CM_ SG_ 279 SNR117_7_6_RAB_PED_HALT "歩行者RAB一時停止状態通知(HALT)
";
CM_ SG_ 279 SNR117_6_0_REQ_ACT_EPB "EPB作動要求
";
CM_ SG_ 279 SNR117_6_1_STOP_HOJI_BUZ_ACT "停止保持解除音フラグ
";
CM_ SG_ 279 SNR117_6_2_RAB_OFF "RAB OFF灯　点灯要求
";
CM_ SG_ 279 SNR117_6_3_SONAR_OFF "警報音機能OFF灯 点灯要求
";
CM_ SG_ 279 SNR117_6_4_RAB_PED_OFF "歩行者RAB OFF灯 点灯要求
";
CM_ SG_ 279 SNR117_6_5_SONAR_HALT "警報音一時停止状態通知(HALT)
";
CM_ SG_ 279 SNR117_5_0_YOATSU_ACT "ﾌﾞﾚｰｷ予圧ﾌﾗｸﾞ
";
CM_ SG_ 279 SNR117_5_1_TORQUE_LIM_ACT "加速抑制実施フラグ
";
CM_ SG_ 279 SNR117_5_2_TORQUE_LIM_VAL "加速抑制値
";
CM_ SG_ 279 SNR117_4_0_RAB_ACT "RAB実施フラグ
";
CM_ SG_ 279 SNR117_4_1_RAB_VAL "減速度制動指示
";
CM_ SG_ 279 SNR117_3_0_RAB "RAB機能有無
";
CM_ SG_ 279 SNR117_3_1_RAB_PED "歩行者RAB機能有無
";
CM_ SG_ 279 SNR117_2_0_E2E_COUNTER "E2Eｶｳﾝﾀ
";
CM_ SG_ 279 SNR117_0_0_E2E_CRC "CRC
";
CM_ SG_ 845 ADAS34D_16_0_CSTM_SNR_DSPREEQ "カスタマイズ表示要求(クリソナON/OFF)
";
CM_ SG_ 845 ADAS34D_16_2_CSTM_RAB_DSPREQ "カスタマイズ表示要求(RAB ON/OFF)
";
CM_ SG_ 845 ADAS34D_16_4_CSTM_PED_DSPREQ "カスタマイズ表示要求(歩行者RAB ON/OFF)
";
CM_ SG_ 845 ADAS34D_16_6_CSTM_PEDTIM_DSPREQ "カスタマイズ表示要求(歩行者RABタイミング)
";
CM_ SG_ 845 ADAS34D_15_0_CSTM_SNR_CLEAR "SNRｶｽﾀﾏｲｽﾞ現在値設定(ｸﾘｱﾗﾝｽｿﾅｰ機能)
";
CM_ SG_ 845 ADAS34D_15_1_CSTM_RAB "SNRｶｽﾀﾏｲｽﾞ現在値設定(RAB機能)
";
CM_ SG_ 845 ADAS34D_15_2_CSTM_RAB_PED "SNRｶｽﾀﾏｲｽﾞ現在値設定(歩行者RAB機能)
";
CM_ SG_ 845 ADAS34D_15_3_CSTM_RAB_PED_TIMING "SNRｶｽﾀﾏｲｽﾞ現在値設定(歩行者RABタイミング)
";
CM_ SG_ 845 ADAS34D_15_5_CSTM_TEMP_OFF "ｶｽﾀﾏｲｽﾞ現在設定値(一括一時OFF)
";
CM_ SG_ 845 ADAS34D_15_7_TEMP_OFF_STATE "一括一時OFF状態
";
CM_ SG_ 845 ADAS34D_14_0_RAB_WARNING "割り込み表示要求
";
CM_ SG_ 845 ADAS34D_14_3_SONAR_LEVEL "警報音指示
";
CM_ SG_ 845 ADAS34D_13_0_PED_WARN_CENTER "歩行者お知らせ中央表示
";
CM_ SG_ 845 ADAS34D_13_1_PED_WARN_LEFT "歩行者お知らせ左表示
";
CM_ SG_ 845 ADAS34D_13_2_PED_WARN_RIGHT "歩行者お知らせ右表示
";
CM_ SG_ 845 ADAS34D_13_3_RAB_TRIG_TYPE "RAB作動トリガ種類
";
CM_ SG_ 845 ADAS34D_9_0_SONAR_R_R_CORNER_4LV "リアソナー距離警報情報(右コーナー4段階)
";
CM_ SG_ 845 ADAS34D_8_0_SONAR_DISP_INT "クリソナ割り込み表示要求
";
CM_ SG_ 845 ADAS34D_8_1_SONAR_R_CENTER "ﾘｱｿﾅｰ距離警報情報：Rcenter（中央4段階）
";
CM_ SG_ 845 ADAS34D_8_4_SONAR_R_L_CORNER_4LV "リアソナー距離警報情報(左コーナー4段階)
";
CM_ SG_ 845 ADAS34D_7_0_SONAR_SYS_FAIL "ｿﾅｰｼｽﾃﾑ故障状態通知 (FAIL)
";
CM_ SG_ 845 ADAS34D_7_2_RAB_HALT "RAB一時停止状態通知 (HALT)
";
CM_ SG_ 845 ADAS34D_7_4_CAMERA_FAIL "ｶﾒﾗｼｽﾃﾑ故障状態通知(FAIL)
";
CM_ SG_ 845 ADAS34D_7_6_RAB_PED_HALT "歩行者RAB一時停止状態通知(HALT)
";
CM_ SG_ 845 ADAS34D_6_0_REQ_ACT_EPB "EPB作動要求
";
CM_ SG_ 845 ADAS34D_6_1_STOP_HOJI_BUZ_ACT "停止保持解除音フラグ
";
CM_ SG_ 845 ADAS34D_6_2_RAB_OFF "RAB OFF灯　点灯要求
";
CM_ SG_ 845 ADAS34D_6_3_SONAR_OFF "警報音機能OFF灯 点灯要求
";
CM_ SG_ 845 ADAS34D_6_4_RAB_PED_OFF "歩行者RAB OFF灯 点灯要求
";
CM_ SG_ 845 ADAS34D_6_5_SONAR_HALT "警報音一時停止状態通知(HALT)
";
CM_ SG_ 845 ADAS34D_5_0_YOATSU_ACT "ﾌﾞﾚｰｷ予圧ﾌﾗｸﾞ
";
CM_ SG_ 845 ADAS34D_5_1_TORQUE_LIM_ACT "加速抑制実施フラグ
";
CM_ SG_ 845 ADAS34D_5_2_TORQUE_LIM_VAL "加速抑制値
";
CM_ SG_ 845 ADAS34D_4_0_RAB_ACT "RAB実施フラグ
";
CM_ SG_ 845 ADAS34D_4_1_RAB_VAL "減速度制動指示
";
CM_ SG_ 845 ADAS34D_3_0_RAB "RAB機能有無
";
CM_ SG_ 845 ADAS34D_3_1_RAB_PED "歩行者RAB機能有無
";
CM_ SG_ 845 ADAS34D_2_0_E2E_COUNTER "E2Eｶｳﾝﾀ
";
CM_ SG_ 845 ADAS34D_0_0_E2E_CRC "CRC
";
CM_ SG_ 844 ADAS34C_25_0_CSTM_ADDON_DISP_CNT "EYEカスタマイズ現在値（その他項目）
";
CM_ SG_ 844 ADAS34C_25_1_CSTM_LANE_SET_CONT "EYEカスタマイズ現在値（通行区分設定-制御）
";
CM_ SG_ 844 ADAS34C_24_0_CSTM_LSW "EYEカスタマイズ現在値（ふらつき警報）
";
CM_ SG_ 844 ADAS34C_24_1_CSTM_GREEN_LIGHT "EYEカスタマイズ現在値（青信号お知らせ）
";
CM_ SG_ 844 ADAS34C_24_2_CSTM_LANE_SET "EYEカスタマイズ現在値（通行区分設定）
";
CM_ SG_ 844 ADAS34C_24_3_CSTM_PROPOSAL_HMI "EYEカスタマイズ現在値（アイサイト使用提案）
";
CM_ SG_ 844 ADAS34C_24_4_CSTM_V2N "EYEカスタマイズ現在値（V2N）
";
CM_ SG_ 844 ADAS34C_24_5_CSTM_DATA_COLLECT "EYEカスタマイズ現在値（データ収集・解析）
";
CM_ SG_ 844 ADAS34C_24_6_CSTM_COLLECT_IMAGE "EYEカスタマイズ現在値（データ収集・解析(画像データ)）
";
CM_ SG_ 844 ADAS34C_24_7_CSTM_COLLECT_LOC "EYEカスタマイズ現在値（データ収集・解析(位置データ)）
";
CM_ SG_ 844 ADAS34C_22_0_DATA_COLLECT_DISP "EYEカスタマイズ表示制御信号（データ収集・解析）
";
CM_ SG_ 844 ADAS34C_22_2_COLLECT_IMAGE_DISP "EYEカスタマイズ表示制御信号（データ収集・解析(画像データ)）
";
CM_ SG_ 844 ADAS34C_22_4_COLLECT_LOC_DISP "EYEカスタマイズ表示制御信号（データ収集・解析(位置データ)）
";
CM_ SG_ 844 ADAS34C_21_0_LSW_DISP_CONT "EYEカスタマイズ表示制御信号（ふらつき警報）
";
CM_ SG_ 844 ADAS34C_21_2_GREEN_LIGHT_DISP "EYEカスタマイズ表示制御信号（青信号お知らせ）
";
CM_ SG_ 844 ADAS34C_21_4_LANE_SET_DISP_CONT "EYEカスタマイズ表示制御信号（通行区分設定-制御）
";
CM_ SG_ 844 ADAS34C_21_6_PROPOSAL_HMI_DISP "EYEカスタマイズ表示制御信号（アイサイト使用提案）
";
CM_ SG_ 844 ADAS34C_20_0_ADD_ON_DISP_CONT "EYEカスタマイズ表示制御信号（その他項目）
";
CM_ SG_ 844 ADAS34C_20_2_V2N_DISP_CONT "EYEカスタマイズ表示制御信号（V2N）
";
CM_ SG_ 844 ADAS34C_20_4_LANE_SET_PTN_DISP "EYEカスタマイズ表示制御信号（通行区分設定）
";
CM_ SG_ 844 ADAS34C_18_0_CSTM_SUPPRESS_SPEED "EYEカスタマイズ現在値（抑制/減速制御-感度-制御）
";
CM_ SG_ 844 ADAS34C_18_1_SUPPRESS_SPD_LEVEL "EYEカスタマイズ現在値（抑制/減速制御-感度）
";
CM_ SG_ 844 ADAS34C_18_3_ACTIVE_AVOIDANCE "EYEカスタマイズ現在値（先読み操舵減速アシスト-制御）
";
CM_ SG_ 844 ADAS34C_18_4_ACTIVE_AVOIDANCE_LV "EYEカスタマイズ現在値（先読み操舵減速アシスト）
";
CM_ SG_ 844 ADAS34C_17_0_CSTM_PDA_CURR "EYEカスタマイズ現在値（安全重視モード）
";
CM_ SG_ 844 ADAS34C_17_1_TARGET_VEHICLE "EYEカスタマイズ現在値（抑制/減速制御-ターゲット(車両)）
";
CM_ SG_ 844 ADAS34C_17_2_TARGET_SURROUNDING "EYEカスタマイズ現在値（抑制/減速制御-ターゲット(周辺環境)）
";
CM_ SG_ 844 ADAS34C_17_3_TARGET_SLOPE_DOWN "EYEカスタマイズ現在値（抑制/減速制御-ターゲット(下り坂)）
";
CM_ SG_ 844 ADAS34C_17_4_CUS_SUPPRESS_SPDTGT "EYEカスタマイズ現在値（抑制/減速制御-ターゲット-制御）
";
CM_ SG_ 844 ADAS34C_15_0_A_AVOIDANCE_DISP "EYEカスタマイズ表示制御信号（先読み操舵減速アシスト-制御）
";
CM_ SG_ 844 ADAS34C_15_2_A_AVOIDANCE_LV_DISP "EYEカスタマイズ表示制御信号（先読み操舵減速アシスト）
";
CM_ SG_ 844 ADAS34C_15_4_A_AVOIDANCE_LV_PTN "EYEカスタマイズパターン指示信号（先読み操舵減速アシスト）
";
CM_ SG_ 844 ADAS34C_14_0_SUPPRESS_SPDTGT_DSP "EYEカスタマイズ表示制御信号（抑制/減速制御-ターゲット-制御）
";
CM_ SG_ 844 ADAS34C_14_2_TARGET_VEHICLE_DISP "EYEカスタマイズ表示制御信号（抑制/減速制御-ターゲット(車両)）
";
CM_ SG_ 844 ADAS34C_14_4_TARGET_SURROUND_DSP "EYEカスタマイズ表示制御信号（抑制/減速制御-ターゲット(周辺環境)）
";
CM_ SG_ 844 ADAS34C_14_6_TGT_SLOPE_DOWN_DSP "EYEカスタマイズ表示制御信号（抑制/減速制御-ターゲット(下り坂)）
";
CM_ SG_ 844 ADAS34C_13_0_PDA_DISP_CONT "EYEカスタマイズ表示制御信号（安全重視モード）
";
CM_ SG_ 844 ADAS34C_13_2_SUPPRESS_SPD_DISP "EYEカスタマイズ表示制御信号（抑制/減速制御-感度-制御）
";
CM_ SG_ 844 ADAS34C_13_4_SUPPRESS_SPDLV_DISP "EYEカスタマイズ表示制御信号（抑制/減速制御-感度）
";
CM_ SG_ 844 ADAS34C_13_6_SUPPRESS_SPD_LV_PTN "EYEカスタマイズパターン指示信号（抑制/減速制御-感度）
";
CM_ SG_ 844 ADAS34C_11_0_ISA_OFS_U50_DISP "EYEカスタマイズ表示制御信号（標識連動オフセット値～50 km）
";
CM_ SG_ 844 ADAS34C_11_2_ISA_OFS_OV50_DISP "EYEカスタマイズ表示制御信号（標識連動オフセット値50 km～）
";
CM_ SG_ 844 ADAS34C_10_0_SLWF_OFFSET_OV50 "EYEカスタマイズ現在値（SLWFオフセット値50 km～）
";
CM_ SG_ 844 ADAS34C_9_0_SLWF_OFFSET_U50 "EYEカスタマイズ現在値（SLWFオフセット値～50 km）
";
CM_ SG_ 844 ADAS34C_9_5_CSTM_SLWF "EYEカスタマイズ現在値（SLWF-制御）
";
CM_ SG_ 844 ADAS34C_9_6_CSTM_SLWF_OFS_CONT "EYEカスタマイズ現在値（SLWFオフセット値-制御）
";
CM_ SG_ 844 ADAS34C_9_7_ISA_IACC_OFS_CONT "EYEカスタマイズ現在値（標識連動オフセット値-制御）
";
CM_ SG_ 844 ADAS34C_8_0_ISA_IACC_OFFSET_OV50 "EYEカスタマイズ現在値（標識連動オフセット値50 km～）
";
CM_ SG_ 844 ADAS34C_8_5_SIGN_SWITCH_SOUND "EYEカスタマイズ現在値（標識切替え音-制御）
";
CM_ SG_ 844 ADAS34C_8_6_CSTM_LOADSIGNS_SYS "EYEカスタマイズ現在値（標識関連機能）
";
CM_ SG_ 844 ADAS34C_8_7_CSTM_ISA_IACC_CONT "EYEカスタマイズ現在値（標識連動-制御）
";
CM_ SG_ 844 ADAS34C_7_0_ISA_IACC_OFFSET_U50 "EYEカスタマイズ現在値（標識連動オフセット値～50 km）
";
CM_ SG_ 844 ADAS34C_7_5_CSTM_LOADSIGNS_ADD "EYEカスタマイズ現在値（標識表示お知らせ-制御）
";
CM_ SG_ 844 ADAS34C_7_6_CSTM_ISA_IACC_ACCEPT "EYEカスタマイズ現在値（標識連動）
";
CM_ SG_ 844 ADAS34C_6_0_ISA_IACC_PTN_DISP "EYEカスタマイズ表示制御信号（標識連動）
";
CM_ SG_ 844 ADAS34C_6_2_SLWF_OFS_U50_DISP "EYEカスタマイズ表示制御信号（SLWFオフセット値～50 km）
";
CM_ SG_ 844 ADAS34C_6_4_SLWF_OFS_OV50_DISP "EYEカスタマイズ表示制御信号（SLWFオフセット値50 km～）
";
CM_ SG_ 844 ADAS34C_5_0_SLWF_DISP_CONT "EYEカスタマイズ表示制御信号（SLWF-制御）
";
CM_ SG_ 844 ADAS34C_5_2_ISA_IACC_OFSET_DISP "EYEカスタマイズ表示制御信号（標識連動オフセット値-制御）
";
CM_ SG_ 844 ADAS34C_5_4_SLWF_OFSET_DISP "EYEカスタマイズ表示制御信号（SLWFオフセット値-制御）
";
CM_ SG_ 844 ADAS34C_5_6_SIGNSWITCH_SND_DISP "EYEカスタマイズ表示制御信号（標識切替え音-制御）
";
CM_ SG_ 844 ADAS34C_4_0_LOADSIGN_DISP_CONT "EYEカスタマイズ表示制御信号（標識関連機能）
";
CM_ SG_ 844 ADAS34C_4_2_LOADSIGN_ADD_DISP "EYEカスタマイズ表示制御信号（標識表示お知らせ-制御）
";
CM_ SG_ 844 ADAS34C_4_4_ISA_IACC_ACCEPT_DISP "EYEカスタマイズ表示制御信号（標識連動-制御）
";
CM_ SG_ 844 ADAS34C_4_6_ISA_IACC_ACCEPT_PTN "EYEカスタマイズパターン指示信号（標識連動）
";
CM_ SG_ 844 ADAS34C_3_0_EYE_VALID "EYEカスタマイズValidフラグ
";
CM_ SG_ 844 ADAS34C_2_0_E2E_COUNTER "E2Eｶｳﾝﾀ
";
CM_ SG_ 844 ADAS34C_0_0_E2E_CRC "CRC
";
CM_ SG_ 843 ADAS34B_31_0_CSTM_ACC_FUNC_CONT "EYEカスタマイズ現在値（ACC加速特性-制御）
";
CM_ SG_ 843 ADAS34B_30_0_CSTM_ACC_CONT_SET "EYEカスタマイズ現在値（ACC加速特性）
";
CM_ SG_ 843 ADAS34B_30_2_CSTM_ACC_OVERTAKE "EYEカスタマイズ現在値（追い越し抑制-制御）
";
CM_ SG_ 843 ADAS34B_30_3_CSTM_ACC_TARGET_OPT "EYEカスタマイズ現在値（ACC-ターゲット-制御）
";
CM_ SG_ 843 ADAS34B_30_4_CSTM_ACC_STOP_CONT "EYEカスタマイズ現在値（ACC-ターゲット(停止制御)）
";
CM_ SG_ 843 ADAS34B_30_5_CSTM_ACC_SLOWDOWN "EYEカスタマイズ現在値（ACC-ターゲット(減速制御)）
";
CM_ SG_ 843 ADAS34B_30_6_CSTM_ACC_HIGHWAY "EYEカスタマイズ現在値（ACC-ターゲット(高速道路)）
";
CM_ SG_ 843 ADAS34B_30_7_CSTM_ACC_SYS "EYEカスタマイズ現在値（クルーズコントロールシステム)
";
CM_ SG_ 843 ADAS34B_28_0_ACC_TARGET_OPT_DISP "EYEカスタマイズ表示制御信号（ACC-ターゲット-制御）
";
CM_ SG_ 843 ADAS34B_28_2_ACC_STOP_DISP "EYEカスタマイズ表示制御信号（ACC-ターゲット(停止制御)）
";
CM_ SG_ 843 ADAS34B_28_4_ACC_SLOWDOWN_DISP "EYEカスタマイズ表示制御信号（ACC-ターゲット(減速制御)）
";
CM_ SG_ 843 ADAS34B_28_6_ACC_HIGHWAY_DISP "EYEカスタマイズ表示制御信号（ACC-ターゲット(高速道路)）
";
CM_ SG_ 843 ADAS34B_27_0_ACC_DISP_CONT "EYEカスタマイズ表示制御信号（クルーズコントロールシステム）
";
CM_ SG_ 843 ADAS34B_27_2_ACC_LEVEL_DISP_CONT "EYEカスタマイズ表示制御信号（ACC加速特性-制御）
";
CM_ SG_ 843 ADAS34B_27_4_ACC_OVERTAKE_DISP "EYEカスタマイズ表示制御信号（追い越し抑制-制御）
";
CM_ SG_ 843 ADAS34B_27_6_ACC_LEVEL_PTN_DISP "EYEカスタマイズ表示制御信号（ACC加速特性）
";
CM_ SG_ 843 ADAS34B_25_0_CSTM_ACTIVE_LKS "EYEカスタマイズ現在値（車線中央維持）
";
CM_ SG_ 843 ADAS34B_25_1_CSTM_A_LKS_AUTOPASS "EYEカスタマイズ現在値（LKS-付加機能(自動追い越し)）
";
CM_ SG_ 843 ADAS34B_25_2_CSTM_A_LKS_NAVI "EYEカスタマイズ現在値（LKS-付加機能(ナビルート連携)）
";
CM_ SG_ 843 ADAS34B_25_3_CSTM_A_LKS_OFFSET "EYEカスタマイズ現在値（LKS-付加機能(走行位置オフセット)）
";
CM_ SG_ 843 ADAS34B_25_4_CSTM_A_LKS_OPT_CONT "EYEカスタマイズ現在値（LKS-付加機能-制御）
";
CM_ SG_ 843 ADAS34B_23_0_A_LKS_OPTION_DISP "EYEカスタマイズ表示制御信号（LKS-付加機能-制御）
";
CM_ SG_ 843 ADAS34B_23_2_A_LKS_AUTOPASS_DISP "EYEカスタマイズ表示制御信号（LKS-付加機能(自動追い越し)）
";
CM_ SG_ 843 ADAS34B_23_4_A_LKS_NAVI_DISP "EYEカスタマイズ表示制御信号（LKS-付加機能(ナビルート連携)）
";
CM_ SG_ 843 ADAS34B_23_6_A_LKS_OFFSET_DISP "EYEカスタマイズ表示制御信号（LKS-付加機能(走行位置オフセット)）
";
CM_ SG_ 843 ADAS34B_22_0_ACTIVE_LKS_DISP "EYEカスタマイズ表示制御信号（車線中央維持）
";
CM_ SG_ 843 ADAS34B_21_0_CSTM_LDW_TMG_CNT "EYEカスタマイズ現在値（LD-警報タイミング-制御）
";
CM_ SG_ 843 ADAS34B_21_1_CSTM_LDPTARGET_CONT "EYEカスタマイズ現在値（LD-制御対象-制御）
";
CM_ SG_ 843 ADAS34B_21_2_ELK_ASSISTTYPE_CONT "EYEカスタマイズ現在値（ELK-アシストタイプ-制御）
";
CM_ SG_ 843 ADAS34B_20_0_CSTM_ELK "EYEカスタマイズ現在値（ELK）
";
CM_ SG_ 843 ADAS34B_20_1_CSTM_ELK_SOUND "EYEカスタマイズ現在値（ELK-アシストタイプ(音)）
";
CM_ SG_ 843 ADAS34B_20_2_CSTM_ELK_VIB "EYEカスタマイズ現在値（ELK-アシストタイプ(振動)）
";
CM_ SG_ 843 ADAS34B_20_3_CSTM_ELK_CTRL "EYEカスタマイズ現在値（ELK-アシストタイプ(制御)）
";
CM_ SG_ 843 ADAS34B_20_4_CSTM_LDW_TIMING "EYEカスタマイズ現在値（LD-警報タイミング）
";
CM_ SG_ 843 ADAS34B_20_6_LDW_SOUND_ON_OFF_SW "EYEカスタマイズ現在値（LDW音OFF）
";
CM_ SG_ 843 ADAS34B_20_7_CSTM_LD_ASSISTTYPE "EYEカスタマイズ現在値（LD-アシストタイプ-制御）
";
CM_ SG_ 843 ADAS34B_19_0_CSTM_LANE_DEPARTURE "EYEカスタマイズ現在値（車線逸脱抑制機能）
";
CM_ SG_ 843 ADAS34B_19_1_CSTM_LDW_SOUND "EYEカスタマイズ現在値（LD-アシストタイプ(音)）
";
CM_ SG_ 843 ADAS34B_19_2_CSTM_LDW_VIB "EYEカスタマイズ現在値（LD-アシストタイプ(振動)）
";
CM_ SG_ 843 ADAS34B_19_3_CSTM_LDP "EYEカスタマイズ現在値（LD-アシストタイプ(制御)）
";
CM_ SG_ 843 ADAS34B_19_4_LDP_TGT_SOLIDLINE "EYEカスタマイズ現在値（LD-制御対象(実線)）
";
CM_ SG_ 843 ADAS34B_19_5_LDP_TGT_DASHLINE "EYEカスタマイズ現在値（LD-制御対象(破線)）
";
CM_ SG_ 843 ADAS34B_19_6_LDP_TGT_SIDE_OBJ "EYEカスタマイズ現在値（LD-制御対象(側方構造物)）
";
CM_ SG_ 843 ADAS34B_19_7_LDP_TGT_SIDE_VHCL "EYEカスタマイズ現在値（LD-制御対象(側方車両)）
";
CM_ SG_ 843 ADAS34B_17_0_ELK_ASSISTTYPE_DISP "EYEカスタマイズ表示制御信号（ELK-アシストタイプ-制御）
";
CM_ SG_ 843 ADAS34B_17_2_ELK_SOUND_DISP_CONT "EYEカスタマイズ表示制御信号（ELK-アシストタイプ(音)）
";
CM_ SG_ 843 ADAS34B_17_4_ELK_VIB_DISP_CONT "EYEカスタマイズ表示制御信号（ELK-アシストタイプ(振動)）
";
CM_ SG_ 843 ADAS34B_17_6_ELK_CTRL_DISP_CONT "EYEカスタマイズ表示制御信号（ELK-アシストタイプ(制御)）
";
CM_ SG_ 843 ADAS34B_16_0_LDW_TIMING_DISP "EYEカスタマイズ表示制御信号（LD-警報タイミング-制御）
";
CM_ SG_ 843 ADAS34B_16_2_LDW_TIMING_PTN "EYEカスタマイズパターン指示信号（LD-警報タイミング）
";
CM_ SG_ 843 ADAS34B_16_6_LDW_TIMING_PTN_DISP "EYEカスタマイズ表示制御信号（LD-警報タイミング）
";
CM_ SG_ 843 ADAS34B_15_0_TGT_SOLIDLINE_DISP "EYEカスタマイズ表示制御信号（LD-制御対象(実線)）
";
CM_ SG_ 843 ADAS34B_15_2_TGT_DASHLINE_DISP "EYEカスタマイズ表示制御信号（LD-制御対象(破線)）
";
CM_ SG_ 843 ADAS34B_15_4_TGT_SIDE_OBJ_DISP "EYEカスタマイズ表示制御信号（LD-制御対象(側方構造物)）
";
CM_ SG_ 843 ADAS34B_15_6_TGT_SIDE_VHCL_DISP "EYEカスタマイズ表示制御信号（LD-制御対象(側方車両)）
";
CM_ SG_ 843 ADAS34B_14_0_LD_ASSISTTYPE_DISP "EYEカスタマイズ表示制御信号（LD-アシストタイプ-制御）
";
CM_ SG_ 843 ADAS34B_14_2_LDW_SOUND_DISP_CONT "EYEカスタマイズ表示制御信号（LD-アシストタイプ(音)）
";
CM_ SG_ 843 ADAS34B_14_4_LDW_VIB_DISP_CONT "EYEカスタマイズ表示制御信号（LD-アシストタイプ(振動)）
";
CM_ SG_ 843 ADAS34B_14_6_LDP_DISP_CONT "EYEカスタマイズ表示制御信号（LD-アシストタイプ(制御)）
";
CM_ SG_ 843 ADAS34B_13_0_LANE_DEPARTURE_DISP "EYEカスタマイズ表示制御信号（車線逸脱抑制機能）
";
CM_ SG_ 843 ADAS34B_13_2_LDPTARGET_DISP_CONT "EYEカスタマイズ表示制御信号（LD-制御対象-制御）
";
CM_ SG_ 843 ADAS34B_13_4_LDW_SOUND_SW_DISP "EYEカスタマイズ表示制御信号（LDW音OFF）
";
CM_ SG_ 843 ADAS34B_13_6_ELK_DISP_CONT "EYEカスタマイズ表示制御信号（ELK）
";
CM_ SG_ 843 ADAS34B_11_0_CSTM_MIS_AT_BACK "EYEカスタマイズ現在値（後退速リミッター）
";
CM_ SG_ 843 ADAS34B_11_1_MIS_AT_BACK_SPD_LIM "EYEカスタマイズ現在値（リミット速度）
";
CM_ SG_ 843 ADAS34B_11_3_CSTM_FCW_TYPE_CONT "EYEカスタマイズ現在値（FCW警報方法-制御）
";
CM_ SG_ 843 ADAS34B_11_4_FCTI_NOTICE_CONT "EYEカスタマイズ現在値（前側方警戒アシスト通知方法-制御）
";
CM_ SG_ 843 ADAS34B_11_5_CSTM_SAFTY_MOD_SENS "EYEカスタマイズ現在値（踏み間違い加速抑制-感度-制御）
";
CM_ SG_ 843 ADAS34B_11_6_MIS_AT_BACK_CONT "EYEカスタマイズ現在値（リミット速度-制御）
";
CM_ SG_ 843 ADAS34B_10_0_CSTM_FCTI_CONT "EYEカスタマイズ現在値（前側方警戒アシスト）
";
CM_ SG_ 843 ADAS34B_10_1_CSTM_FCTI_SOUND "EYEカスタマイズ現在値（前側方警戒アシスト通知方法(音)）
";
CM_ SG_ 843 ADAS34B_10_2_CSTM_FCTI_PULSE "EYEカスタマイズ現在値（前側方警戒アシスト通知方法(振動)）
";
CM_ SG_ 843 ADAS34B_10_3_CSTM_SAFTY_MODE "EYEカスタマイズ現在値（踏み間違い加速抑制）
";
CM_ SG_ 843 ADAS34B_10_4_CSTM_SAFTY_MODE_LV "EYEカスタマイズ現在値（踏み間違い加速抑制-感度）
";
CM_ SG_ 843 ADAS34B_10_6_CSTM_BRK_TIMING_CUR "EYEカスタマイズ現在値（ブレーキタイミング-制御）
";
CM_ SG_ 843 ADAS34B_10_7_CSTM_FCW_CONT_CUR "EYEカスタマイズ現在値（FCW警報タイミング-制御）
";
CM_ SG_ 843 ADAS34B_9_0_CSTM_P_CR "EYEカスタマイズ現在値（プリクラッシュブレーキ）
";
CM_ SG_ 843 ADAS34B_9_1_FCW_SOUND_ON_OFF_SW "EYEカスタマイズ現在値（FCW音OFF）
";
CM_ SG_ 843 ADAS34B_9_2_CSTM_FCW_TIMING "EYEカスタマイズ現在値（FCW警報タイミング）
";
CM_ SG_ 843 ADAS34B_9_4_CSTM_FCW_TYPE_SOUND "EYEカスタマイズ現在値（FCW警報方法(音)）
";
CM_ SG_ 843 ADAS34B_9_5_CSTM_FCW_TYPE_PULSE "EYEカスタマイズ現在値（FCW警報方法(振動)）
";
CM_ SG_ 843 ADAS34B_9_6_CSTM_BRAKE_TIMING "EYEカスタマイズ現在値（ブレーキタイミング）
";
CM_ SG_ 843 ADAS34B_8_0_SAFTY_MODE_SENS_DISP "EYEカスタマイズ表示制御信号（踏み間違い加速抑制-感度-制御）
";
CM_ SG_ 843 ADAS34B_8_2_MIS_AT_BACK_PTN_DISP "EYEカスタマイズ表示制御信号（リミット速度）
";
CM_ SG_ 843 ADAS34B_7_0_MIS_AT_BACK_DISP "EYEカスタマイズ表示制御信号（後退速度リミッター）
";
CM_ SG_ 843 ADAS34B_7_2_MIS_AT_BACK_LIM_DISP "EYEカスタマイズ表示制御信号（リミット速度-制御）
";
CM_ SG_ 843 ADAS34B_7_4_BRK_TIMING_PTN_DISP "EYEカスタマイズ表示制御信号（ブレーキタイミング）
";
CM_ SG_ 843 ADAS34B_7_6_FCW_TIMING_PTN_DISP "EYEカスタマイズ表示制御信号（FCW警報タイミング）
";
CM_ SG_ 843 ADAS34B_6_0_SAFTY_MODE_DISP_CONT "EYEカスタマイズ表示制御信号（踏み間違い加速抑制）
";
CM_ SG_ 843 ADAS34B_6_2_SAFTY_MODE_LV_DISP "EYEカスタマイズ表示制御信号（踏み間違い加速抑制-感度）
";
CM_ SG_ 843 ADAS34B_6_4_SAFTY_MODE_LV_PTN "EYEカスタマイズパターン指示信号（踏み間違い加速抑制-感度）
";
CM_ SG_ 843 ADAS34B_5_0_FCTI_DISP_CONT "EYEカスタマイズ表示制御信号（前側方警戒アシスト）
";
CM_ SG_ 843 ADAS34B_5_2_FCTI_NOTICE_DISP "EYEカスタマイズ表示制御信号（前側方警戒アシスト通知方法-制御）
";
CM_ SG_ 843 ADAS34B_5_4_FCTI_SOUND_DISP_CONT "EYEカスタマイズ表示制御信号（前側方警戒アシスト通知方法(音)）
";
CM_ SG_ 843 ADAS34B_5_6_FCTI_PULSE_DISP_CONT "EYEカスタマイズ表示制御信号（前側方警戒アシスト通知方法(振動)）
";
CM_ SG_ 843 ADAS34B_4_0_FCW_TYPE_DISP_CONT "EYEカスタマイズ表示制御信号（FCW警報方法-制御）
";
CM_ SG_ 843 ADAS34B_4_2_FCW_TYPE_SOUND_DISP "EYEカスタマイズ表示制御信号（FCW警報方法(音)）
";
CM_ SG_ 843 ADAS34B_4_4_FCW_TYPE_PULSE_DISP "EYEカスタマイズ表示制御信号（FCW警報方法(振動)）
";
CM_ SG_ 843 ADAS34B_4_6_FCW_SOUND_SW_DISP "EYEカスタマイズ表示制御信号（FCW音OFF）
";
CM_ SG_ 843 ADAS34B_3_0_P_CR_DISP_CONT "EYEカスタマイズ表示制御信号（プリクラッシュブレーキ）
";
CM_ SG_ 843 ADAS34B_3_2_BRAKE_TIMING_DISP "EYEカスタマイズ表示制御信号（ブレーキタイミング-制御）
";
CM_ SG_ 843 ADAS34B_3_4_FCW_DISP_CONT "EYEカスタマイズ表示制御信号（FCW警報タイミング-制御）
";
CM_ SG_ 843 ADAS34B_3_6_FCW_TIMING_DISP_PTN "EYEカスタマイズパターン指示信号（FCW警報タイミング）
";
CM_ SG_ 843 ADAS34B_2_0_E2E_COUNTER "E2Eｶｳﾝﾀ
";
CM_ SG_ 843 ADAS34B_0_0_E2E_CRC "CRC
";
CM_ SG_ 841 ADAS349_4_0_AAOS_AEB_STATE "AAOS用AEB状態
";
CM_ SG_ 841 ADAS349_3_0_CID_MRM_DISP "CID表示用MRM表示指示
";
CM_ SG_ 841 ADAS349_2_0_E2E_COUNTER "E2Eカウンタ
";
CM_ SG_ 841 ADAS349_0_0_E2E_CRC "CRC
";
CM_ SG_ 833 ADAS341_2_0_E2E_COUNTER "E2Eカウンタ
";
CM_ SG_ 833 ADAS341_0_0_E2E_CRC "CRC
";
CM_ SG_ 832 ADAS340_11_0_ANGLE "自車角度
";
CM_ SG_ 832 ADAS340_11_5_VIEW_DISP "ビュー表示
";
CM_ SG_ 832 ADAS340_10_0_TARGET_DIST_RANGE "目標車間距離
";
CM_ SG_ 832 ADAS340_9_3_TARGET_DIST "目標車間距離表示
";
CM_ SG_ 832 ADAS340_9_6_DIST4 "車間距離設定4
";
CM_ SG_ 832 ADAS340_7_1_DIST3 "車間距離設定3
";
CM_ SG_ 832 ADAS340_6_4_DIST2 "車間距離設定2
";
CM_ SG_ 832 ADAS340_5_7_DIST1 "車間距離設定1
";
CM_ SG_ 832 ADAS340_3_2_DIST_SET_COLOR "車間距離設定_色
";
CM_ SG_ 832 ADAS340_3_5_DIST_SET "車間距離設定
";
CM_ SG_ 832 ADAS340_2_0_E2E_COUNTER "E2Eカウンタ
";
CM_ SG_ 832 ADAS340_0_0_E2E_CRC "CRC
";
CM_ SG_ 825 ADAS339_22_0_OBJECT20_WINKER "移動物20_ウインカ状態
";
CM_ SG_ 825 ADAS339_22_2_OBJECT20_BRAKE "移動物20_ブレーキランプ
";
CM_ SG_ 825 ADAS339_22_3_OBJECT20_BLINK "移動物20_点灯滅
";
CM_ SG_ 825 ADAS339_22_5_OBJECT20_Z "移動物20_z座標
";
CM_ SG_ 825 ADAS339_20_0_OBJECT20_X "移動物20_x座標
";
CM_ SG_ 825 ADAS339_19_1_OBJECT20_ANGLE "移動物20_角度
";
CM_ SG_ 825 ADAS339_18_0_OBJECT20_COLOR "移動物20_色
";
CM_ SG_ 825 ADAS339_18_4_OBJECT20_SHAPE "移動物20_形状
";
CM_ SG_ 825 ADAS339_17_0_OBJECT19_WINKER "移動物19_ウインカ状態
";
CM_ SG_ 825 ADAS339_17_2_OBJECT19_BRAKE "移動物19_ブレーキランプ
";
CM_ SG_ 825 ADAS339_17_3_OBJECT19_BLINK "移動物19_点灯滅
";
CM_ SG_ 825 ADAS339_17_5_OBJECT19_Z "移動物19_z座標
";
CM_ SG_ 825 ADAS339_15_0_OBJECT19_X "移動物19_x座標
";
CM_ SG_ 825 ADAS339_14_1_OBJECT19_ANGLE "移動物19_角度
";
CM_ SG_ 825 ADAS339_13_0_OBJECT19_COLOR "移動物19_色
";
CM_ SG_ 825 ADAS339_13_4_OBJECT19_SHAPE "移動物19_形状
";
CM_ SG_ 825 ADAS339_12_0_OBJECT18_WINKER "移動物18_ウインカ状態
";
CM_ SG_ 825 ADAS339_12_2_OBJECT18_BRAKE "移動物18_ブレーキランプ
";
CM_ SG_ 825 ADAS339_12_3_OBJECT18_BLINK "移動物18_点灯滅
";
CM_ SG_ 825 ADAS339_12_5_OBJECT18_Z "移動物18_z座標
";
CM_ SG_ 825 ADAS339_10_0_OBJECT18_X "移動物18_x座標
";
CM_ SG_ 825 ADAS339_9_1_OBJECT18_ANGLE "移動物18_角度
";
CM_ SG_ 825 ADAS339_8_0_OBJECT18_COLOR "移動物18_色
";
CM_ SG_ 825 ADAS339_8_4_OBJECT18_SHAPE "移動物18_形状
";
CM_ SG_ 825 ADAS339_7_0_OBJECT17_WINKER "移動物17_ウインカ状態
";
CM_ SG_ 825 ADAS339_7_2_OBJECT17_BRAKE "移動物17_ブレーキランプ
";
CM_ SG_ 825 ADAS339_7_3_OBJECT17_BLINK "移動物17_点灯滅
";
CM_ SG_ 825 ADAS339_7_5_OBJECT17_Z "移動物17_z座標
";
CM_ SG_ 825 ADAS339_5_0_OBJECT17_X "移動物17_x座標
";
CM_ SG_ 825 ADAS339_4_1_OBJECT17_ANGLE "移動物17_角度
";
CM_ SG_ 825 ADAS339_3_0_OBJECT17_COLOR "移動物17_色
";
CM_ SG_ 825 ADAS339_3_4_OBJECT17_SHAPE "移動物17_形状
";
CM_ SG_ 825 ADAS339_2_0_E2E_COUNTER "E2Eカウンタ
";
CM_ SG_ 825 ADAS339_0_0_E2E_CRC "CRC
";
BA_DEF_  "DBCConverterVersion" STRING ;
BA_DEF_  "Manufacturer" STRING ;
BA_DEF_  "BusType" STRING ;
BA_DEF_ BU_  "DiagNode" ENUM  "No","Yes";
BA_DEF_ BU_  "ILUsed" ENUM  "No","Yes";
BA_DEF_ BU_  "NodeLayerModules" STRING ;
BA_DEF_ SG_  "Fhi_SignalComment" STRING ;
BA_DEF_ SG_  "GenSigInactiveValue" INT 0 10000;
BA_DEF_ SG_  "GenSigStartValue" FLOAT 0 100000000000;
BA_DEF_ SG_  "GenSigSendType" ENUM  "Cyclic","OnWrite","OnWriteWithRepetition","OnChange","OnChangeWithRepetition","IfActive","IfActiveWithRepetition","NoSigSendType";
BA_DEF_ BO_  "MsgRoutingId" STRING ;
BA_DEF_ BO_  "DiagResponse" ENUM  "No","Yes";
BA_DEF_ BO_  "DiagRequest" ENUM  "No","Yes";
BA_DEF_ BO_  "DiagState" ENUM  "No","Yes";
BA_DEF_ BO_  "GenMsgILSupport" ENUM  "No","Yes";
BA_DEF_ BO_  "GenMsgNrOfRepetition" INT 0 999999;
BA_DEF_ BO_  "GenMsgDelayTime" INT 0 1000;
BA_DEF_ BO_  "GenMsgCycleTimeFast" INT 0 10000;
BA_DEF_ BO_  "GenMsgCycleTime" INT 0 10000;
BA_DEF_ BO_  "GenMsgSendType" ENUM  "Cyclic","NotUsed","NotUsed","NotUsed","NotUsed","Cyclic","NotUsed","IfActive","NoMsgSendType";
BA_DEF_ BO_  "CANFD_BRS" ENUM  "0","1";
BA_DEF_ BO_  "VFrameFormat" ENUM  "StandardCAN","ExtendedCAN","reserved","reserved","reserved","reserved","reserved","reserved","reserved","reserved","reserved","reserved","reserved","reserved","StandardCAN_FD","ExtendedCAN_FD";
BA_DEF_DEF_  "DBCConverterVersion" "2.0";
BA_DEF_DEF_  "Manufacturer" "FHI";
BA_DEF_DEF_  "BusType" "";
BA_DEF_DEF_  "DiagNode" "No";
BA_DEF_DEF_  "ILUsed" "Yes";
BA_DEF_DEF_  "NodeLayerModules" "CANoeILNLSubaru.dll";
BA_DEF_DEF_  "Fhi_SignalComment" "";
BA_DEF_DEF_  "GenSigInactiveValue" 0;
BA_DEF_DEF_  "GenSigStartValue" 0;
BA_DEF_DEF_  "GenSigSendType" "NoSigSendType";
BA_DEF_DEF_  "MsgRoutingId" "";
BA_DEF_DEF_  "DiagResponse" "No";
BA_DEF_DEF_  "DiagRequest" "No";
BA_DEF_DEF_  "DiagState" "No";
BA_DEF_DEF_  "GenMsgILSupport" "Yes";
BA_DEF_DEF_  "GenMsgNrOfRepetition" 0;
BA_DEF_DEF_  "GenMsgDelayTime" 0;
BA_DEF_DEF_  "GenMsgCycleTimeFast" 0;
BA_DEF_DEF_  "GenMsgCycleTime" 0;
BA_DEF_DEF_  "GenMsgSendType" "Cyclic";
BA_DEF_DEF_  "CANFD_BRS" "1";
BA_DEF_DEF_  "VFrameFormat" "StandardCAN";
BA_ "BusType" "CAN FD";
BA_ "DiagNode" BU_ MVS 1;
BA_ "DiagNode" BU_ RCR_R 1;
BA_ "DiagNode" BU_ RCR_L 1;
BA_ "DiagNode" BU_ SNR 1;
BA_ "DiagNode" BU_ BEV_GW 1;
BA_ "DiagNode" BU_ MET 1;
BA_ "DiagNode" BU_ C_ECU 1;
BA_ "DiagNode" BU_ C_ECU_GW 1;
BA_ "GenMsgCycleTime" BO_ 686 50;
BA_ "VFrameFormat" BO_ 686 14;
BA_ "GenMsgCycleTime" BO_ 685 50;
BA_ "VFrameFormat" BO_ 685 14;
BA_ "GenMsgCycleTime" BO_ 684 50;
BA_ "VFrameFormat" BO_ 684 14;
BA_ "GenMsgCycleTime" BO_ 683 50;
BA_ "VFrameFormat" BO_ 683 14;
BA_ "GenMsgCycleTime" BO_ 682 50;
BA_ "VFrameFormat" BO_ 682 14;
BA_ "GenMsgCycleTime" BO_ 681 50;
BA_ "VFrameFormat" BO_ 681 14;
BA_ "GenMsgCycleTime" BO_ 680 50;
BA_ "VFrameFormat" BO_ 680 14;
BA_ "GenMsgCycleTime" BO_ 679 50;
BA_ "VFrameFormat" BO_ 679 14;
BA_ "GenMsgCycleTime" BO_ 678 50;
BA_ "VFrameFormat" BO_ 678 14;
BA_ "GenMsgCycleTime" BO_ 670 50;
BA_ "VFrameFormat" BO_ 670 14;
BA_ "GenMsgCycleTime" BO_ 669 50;
BA_ "VFrameFormat" BO_ 669 14;
BA_ "GenMsgCycleTime" BO_ 668 50;
BA_ "VFrameFormat" BO_ 668 14;
BA_ "GenMsgCycleTime" BO_ 667 50;
BA_ "VFrameFormat" BO_ 667 14;
BA_ "GenMsgCycleTime" BO_ 666 50;
BA_ "VFrameFormat" BO_ 666 14;
BA_ "GenMsgCycleTime" BO_ 665 50;
BA_ "VFrameFormat" BO_ 665 14;
BA_ "GenMsgCycleTime" BO_ 664 50;
BA_ "VFrameFormat" BO_ 664 14;
BA_ "GenMsgCycleTime" BO_ 663 50;
BA_ "VFrameFormat" BO_ 663 14;
BA_ "GenMsgCycleTime" BO_ 662 50;
BA_ "VFrameFormat" BO_ 662 14;
BA_ "MsgRoutingId" BO_ 552 "279 ";
BA_ "GenMsgNrOfRepetition" BO_ 552 1;
BA_ "GenMsgDelayTime" BO_ 552 10;
BA_ "GenMsgCycleTime" BO_ 552 50;
BA_ "VFrameFormat" BO_ 552 14;
BA_ "GenMsgCycleTime" BO_ 1372 1000;
BA_ "VFrameFormat" BO_ 1372 14;
BA_ "GenMsgCycleTime" BO_ 1371 1000;
BA_ "VFrameFormat" BO_ 1371 14;
BA_ "GenMsgCycleTime" BO_ 1359 1000;
BA_ "VFrameFormat" BO_ 1359 14;
BA_ "GenMsgILSupport" BO_ 966 0;
BA_ "MsgRoutingId" BO_ 966 "276 ";
BA_ "GenMsgNrOfRepetition" BO_ 966 2;
BA_ "GenMsgCycleTimeFast" BO_ 966 50;
BA_ "GenMsgDelayTime" BO_ 966 50;
BA_ "GenMsgCycleTime" BO_ 966 100;
BA_ "VFrameFormat" BO_ 966 14;
BA_ "GenMsgILSupport" BO_ 965 0;
BA_ "MsgRoutingId" BO_ 965 "275 ";
BA_ "GenMsgNrOfRepetition" BO_ 965 2;
BA_ "GenMsgCycleTimeFast" BO_ 965 50;
BA_ "GenMsgDelayTime" BO_ 965 50;
BA_ "GenMsgCycleTime" BO_ 965 100;
BA_ "VFrameFormat" BO_ 965 14;
BA_ "GenMsgILSupport" BO_ 964 0;
BA_ "MsgRoutingId" BO_ 964 "274 ";
BA_ "GenMsgNrOfRepetition" BO_ 964 2;
BA_ "GenMsgCycleTimeFast" BO_ 964 50;
BA_ "GenMsgDelayTime" BO_ 964 50;
BA_ "GenMsgCycleTime" BO_ 964 100;
BA_ "VFrameFormat" BO_ 964 14;
BA_ "GenMsgILSupport" BO_ 805 0;
BA_ "MsgRoutingId" BO_ 805 "271 ";
BA_ "GenMsgNrOfRepetition" BO_ 805 2;
BA_ "GenMsgCycleTimeFast" BO_ 805 50;
BA_ "GenMsgDelayTime" BO_ 805 20;
BA_ "GenMsgCycleTime" BO_ 805 100;
BA_ "VFrameFormat" BO_ 805 14;
BA_ "GenMsgILSupport" BO_ 804 0;
BA_ "MsgRoutingId" BO_ 804 "270 ";
BA_ "GenMsgNrOfRepetition" BO_ 804 2;
BA_ "GenMsgCycleTimeFast" BO_ 804 50;
BA_ "GenMsgDelayTime" BO_ 804 50;
BA_ "GenMsgCycleTime" BO_ 804 100;
BA_ "VFrameFormat" BO_ 804 14;
BA_ "GenMsgILSupport" BO_ 803 0;
BA_ "MsgRoutingId" BO_ 803 "269 ";
BA_ "GenMsgNrOfRepetition" BO_ 803 2;
BA_ "GenMsgCycleTimeFast" BO_ 803 50;
BA_ "GenMsgDelayTime" BO_ 803 50;
BA_ "GenMsgCycleTime" BO_ 803 100;
BA_ "VFrameFormat" BO_ 803 14;
BA_ "GenMsgILSupport" BO_ 802 0;
BA_ "MsgRoutingId" BO_ 802 "268 ";
BA_ "GenMsgNrOfRepetition" BO_ 802 2;
BA_ "GenMsgCycleTimeFast" BO_ 802 50;
BA_ "GenMsgDelayTime" BO_ 802 50;
BA_ "GenMsgCycleTime" BO_ 802 100;
BA_ "VFrameFormat" BO_ 802 14;
BA_ "GenMsgILSupport" BO_ 801 0;
BA_ "MsgRoutingId" BO_ 801 "267 ";
BA_ "GenMsgNrOfRepetition" BO_ 801 2;
BA_ "GenMsgCycleTimeFast" BO_ 801 50;
BA_ "GenMsgDelayTime" BO_ 801 50;
BA_ "GenMsgCycleTime" BO_ 801 100;
BA_ "VFrameFormat" BO_ 801 14;
BA_ "GenMsgCycleTime" BO_ 289 20;
BA_ "VFrameFormat" BO_ 289 14;
BA_ "GenMsgCycleTime" BO_ 1352 1000;
BA_ "VFrameFormat" BO_ 1352 14;
BA_ "MsgRoutingId" BO_ 287 "263 ";
BA_ "GenMsgCycleTime" BO_ 287 20;
BA_ "VFrameFormat" BO_ 287 14;
BA_ "MsgRoutingId" BO_ 292 "262 ";
BA_ "GenMsgCycleTime" BO_ 292 20;
BA_ "VFrameFormat" BO_ 292 14;
BA_ "GenMsgCycleTime" BO_ 471 30;
BA_ "VFrameFormat" BO_ 471 14;
BA_ "GenMsgCycleTime" BO_ 470 30;
BA_ "VFrameFormat" BO_ 470 14;
BA_ "MsgRoutingId" BO_ 279 "261 ";
BA_ "GenMsgCycleTime" BO_ 279 20;
BA_ "VFrameFormat" BO_ 279 14;
BA_ "MsgRoutingId" BO_ 845 "259 ";
BA_ "GenMsgCycleTime" BO_ 845 100;
BA_ "VFrameFormat" BO_ 845 14;
BA_ "MsgRoutingId" BO_ 844 "258 ";
BA_ "GenMsgNrOfRepetition" BO_ 844 2;
BA_ "GenMsgCycleTimeFast" BO_ 844 50;
BA_ "GenMsgDelayTime" BO_ 844 50;
BA_ "GenMsgCycleTime" BO_ 844 100;
BA_ "VFrameFormat" BO_ 844 14;
BA_ "MsgRoutingId" BO_ 843 "257 ";
BA_ "GenMsgNrOfRepetition" BO_ 843 2;
BA_ "GenMsgCycleTimeFast" BO_ 843 50;
BA_ "GenMsgDelayTime" BO_ 843 50;
BA_ "GenMsgCycleTime" BO_ 843 100;
BA_ "VFrameFormat" BO_ 843 14;
BA_ "MsgRoutingId" BO_ 841 "256 ";
BA_ "GenMsgNrOfRepetition" BO_ 841 2;
BA_ "GenMsgCycleTimeFast" BO_ 841 50;
BA_ "GenMsgDelayTime" BO_ 841 50;
BA_ "GenMsgCycleTime" BO_ 841 100;
BA_ "VFrameFormat" BO_ 841 14;
BA_ "GenMsgNrOfRepetition" BO_ 833 2;
BA_ "GenMsgCycleTimeFast" BO_ 833 50;
BA_ "GenMsgDelayTime" BO_ 833 50;
BA_ "GenMsgCycleTime" BO_ 833 100;
BA_ "VFrameFormat" BO_ 833 14;
BA_ "GenMsgNrOfRepetition" BO_ 832 2;
BA_ "GenMsgCycleTimeFast" BO_ 832 50;
BA_ "GenMsgDelayTime" BO_ 832 50;
BA_ "GenMsgCycleTime" BO_ 832 100;
BA_ "VFrameFormat" BO_ 832 14;
BA_ "GenMsgNrOfRepetition" BO_ 825 2;
BA_ "GenMsgCycleTimeFast" BO_ 825 50;
BA_ "GenMsgDelayTime" BO_ 825 50;
BA_ "GenMsgCycleTime" BO_ 825 100;
BA_ "VFrameFormat" BO_ 825 14;
BA_ "GenSigStartValue" SG_ 552 RDR228_6_5_BLOCKAGE_STS 5;
BA_ "GenSigSendType" SG_ 552 RDR228_4_3_WARN_DOW_2ST_R 3;
BA_ "GenSigSendType" SG_ 552 RDR228_4_4_WARN_DOW_2ST_L 3;
BA_ "GenSigStartValue" SG_ 552 RDR228_3_0_WARN_BSD_LCA_R_2ND 1;
BA_ "Fhi_SignalComment" SG_ 552 RDR228_2_6_ON_OFF_RDRSYS "SW情報：ﾗｽﾄﾒﾓﾘ

";
BA_ "GenSigStartValue" SG_ 552 RDR228_1_4_BATT_OFF_CAUSE 1;
BA_ "GenSigStartValue" SG_ 805 EYE325_2_0_RAB_OFF 1;
BA_ "GenSigStartValue" SG_ 805 EYE325_2_1_SONAR_OFF 1;
BA_ "GenSigStartValue" SG_ 805 EYE325_2_6_RAB_DISABLE 1;
BA_ "GenSigStartValue" SG_ 805 EYE325_2_7_SONAR_DISABLE 1;
BA_ "GenSigStartValue" SG_ 805 EYE325_1_7_SONAR_NO_DISP 1;
BA_ "GenSigStartValue" SG_ 803 EYE323_7_0_ISA_OFFSET_CURR 10;
BA_ "GenSigStartValue" SG_ 803 EYE323_6_1_LDW_ON_OFF_SET 1;
BA_ "GenSigStartValue" SG_ 803 EYE323_5_3_FCW_ON_OFF_SET 1;
BA_ "GenSigStartValue" SG_ 801 EYE321_4_2_SRVD_LASTMEM_ST_REQ 1;
BA_ "GenSigStartValue" SG_ 801 EYE321_1_4_PRECRASH_BRAKE_OFF 1;
BA_ "GenSigStartValue" SG_ 801 EYE321_1_5_LANE_DEPARTURE_OFF 1;
BA_ "GenSigStartValue" SG_ 289 EYE121_2_0_EYE_INIT 1;
BA_ "GenSigStartValue" SG_ 279 SNR117_5_2_TORQUE_LIM_VAL 63;
BA_ "GenSigStartValue" SG_ 845 ADAS34D_15_0_CSTM_SNR_CLEAR 1;
BA_ "GenSigStartValue" SG_ 845 ADAS34D_15_1_CSTM_RAB 1;
BA_ "GenSigStartValue" SG_ 845 ADAS34D_15_2_CSTM_RAB_PED 1;
BA_ "GenSigStartValue" SG_ 845 ADAS34D_5_2_TORQUE_LIM_VAL 63;
BA_ "GenSigStartValue" SG_ 844 ADAS34C_10_0_SLWF_OFFSET_OV50 10;
BA_ "GenSigStartValue" SG_ 844 ADAS34C_9_0_SLWF_OFFSET_U50 10;
BA_ "GenSigStartValue" SG_ 844 ADAS34C_8_0_ISA_IACC_OFFSET_OV50 10;
BA_ "GenSigStartValue" SG_ 844 ADAS34C_7_0_ISA_IACC_OFFSET_U50 10;
BA_ "GenSigStartValue" SG_ 843 ADAS34B_20_6_LDW_SOUND_ON_OFF_SW 1;
BA_ "GenSigStartValue" SG_ 843 ADAS34B_9_0_CSTM_P_CR 1;
BA_ "GenSigStartValue" SG_ 843 ADAS34B_9_1_FCW_SOUND_ON_OFF_SW 1;
VAL_ 686 RCR2AE_6_0_BEHIND_BORDER_RIGHT_8 1 "ON" 0 "OFF" ;
VAL_ 686 RCR2AE_6_1_GHOST_FLG_RIGHT_8 1 "ON" 0 "OFF" ;
VAL_ 686 RCR2AE_5_6_OBJ_STATUS_RIGHT_8 3 "Invalid" 2 "Measured" 1 "New" 0 "Empty" ;
VAL_ 685 RCR2AD_6_0_BEHIND_BORDER_RIGHT_7 1 "ON" 0 "OFF" ;
VAL_ 685 RCR2AD_6_1_GHOST_FLG_RIGHT_7 1 "ON" 0 "OFF" ;
VAL_ 685 RCR2AD_5_6_OBJ_STATUS_RIGHT_7 3 "Invalid" 2 "Measured" 1 "New" 0 "Empty" ;
VAL_ 684 RCR2AC_6_0_BEHIND_BORDER_RIGHT_6 1 "ON" 0 "OFF" ;
VAL_ 684 RCR2AC_6_1_GHOST_FLG_RIGHT_6 1 "ON" 0 "OFF" ;
VAL_ 684 RCR2AC_5_6_OBJ_STATUS_RIGHT_6 3 "Invalid" 2 "Measured" 1 "New" 0 "Empty" ;
VAL_ 683 RCR2AB_6_0_BEHIND_BORDER_RIGHT_5 1 "ON" 0 "OFF" ;
VAL_ 683 RCR2AB_6_1_GHOST_FLG_RIGHT_5 1 "ON" 0 "OFF" ;
VAL_ 683 RCR2AB_5_6_OBJ_STATUS_RIGHT_5 3 "Invalid" 2 "Measured" 1 "New" 0 "Empty" ;
VAL_ 682 RCR2AA_6_0_BEHIND_BORDER_RIGHT_4 1 "ON" 0 "OFF" ;
VAL_ 682 RCR2AA_6_1_GHOST_FLG_RIGHT_4 1 "ON" 0 "OFF" ;
VAL_ 682 RCR2AA_5_6_OBJ_STATUS_RIGHT_4 3 "Invalid" 2 "Measured" 1 "New" 0 "Empty" ;
VAL_ 681 RCR2A9_6_0_BEHIND_BORDER_RIGHT_3 1 "ON" 0 "OFF" ;
VAL_ 681 RCR2A9_6_1_GHOST_FLG_RIGHT_3 1 "ON" 0 "OFF" ;
VAL_ 681 RCR2A9_5_6_OBJ_STATUS_RIGHT_3 3 "Invalid" 2 "Measured" 1 "New" 0 "Empty" ;
VAL_ 680 RCR2A8_6_0_BEHIND_BORDER_RIGHT_3 1 "ON" 0 "OFF" ;
VAL_ 680 RCR2A8_6_1_GHOST_FLG_RIGHT_2 1 "ON" 0 "OFF" ;
VAL_ 680 RCR2A8_5_6_OBJ_STATUS_RIGHT_2 3 "Invalid" 2 "Measured" 1 "New" 0 "Empty" ;
VAL_ 679 RCR2A7_6_0_BEHIND_BORDER_RIGHT_1 1 "ON" 0 "OFF" ;
VAL_ 679 RCR2A7_6_1_GHOST_FLG_RIGHT_1 1 "ON" 0 "OFF" ;
VAL_ 679 RCR2A7_5_6_OBJ_STATUS_RIGHT_1 3 "Invalid" 2 "Measured" 1 "New" 0 "Empty" ;
VAL_ 678 RCR2A6_6_0_BEHIND_BORDER_RIGHT_0 1 "ON" 0 "OFF" ;
VAL_ 678 RCR2A6_6_1_GHOST_FLG_RIGHT_0 1 "ON" 0 "OFF" ;
VAL_ 678 RCR2A6_5_6_OBJ_STATUS_RIGHT_0 3 "Invalid" 2 "Measured" 1 "New" 0 "Empty" ;
VAL_ 670 RCR29E_6_0_BEHIND_BORDER_LEFT_8 1 "ON" 0 "OFF" ;
VAL_ 670 RCR29E_6_1_GHOST_FLG_LEFT_8 1 "ON" 0 "OFF" ;
VAL_ 670 RCR29E_5_6_OBJ_STATUS_LEFT_8 3 "Invalid" 2 "Measured" 1 "New" 0 "Empty" ;
VAL_ 669 RCR29D_6_0_BEHIND_BORDER_LEFT_7 1 "ON" 0 "OFF" ;
VAL_ 669 RCR29D_6_1_GHOST_FLG_LEFT_7 1 "ON" 0 "OFF" ;
VAL_ 669 RCR29D_5_6_OBJ_STATUS_LEFT_7 3 "Invalid" 2 "Measured" 1 "New" 0 "Empty" ;
VAL_ 668 RCR29C_6_0_BEHIND_BORDER_LEFT_6 1 "ON" 0 "OFF" ;
VAL_ 668 RCR29C_6_1_GHOST_FLG_LEFT_6 1 "ON" 0 "OFF" ;
VAL_ 668 RCR29C_5_6_OBJ_STATUS_LEFT_6 3 "Invalid" 2 "Measured" 1 "New" 0 "Empty" ;
VAL_ 667 RCR29B_6_0_BEHIND_BORDER_LEFT_5 1 "ON" 0 "OFF" ;
VAL_ 667 RCR29B_6_1_GHOST_FLG_LEFT_5 1 "ON" 0 "OFF" ;
VAL_ 667 RCR29B_5_6_OBJ_STATUS_LEFT_5 3 "Invalid" 2 "Measured" 1 "New" 0 "Empty" ;
VAL_ 666 RCR29A_6_0_BEHIND_BORDER_LEFT_4 1 "ON" 0 "OFF" ;
VAL_ 666 RCR29A_6_1_GHOST_FLG_LEFT_4 1 "ON" 0 "OFF" ;
VAL_ 666 RCR29A_5_6_OBJ_STATUS_LEFT_4 3 "Invalid" 2 "Measured" 1 "New" 0 "Empty" ;
VAL_ 665 RCR299_6_0_BEHIND_BORDER_LEFT_3 1 "ON" 0 "OFF" ;
VAL_ 665 RCR299_6_1_GHOST_FLG_LEFT_3 1 "ON" 0 "OFF" ;
VAL_ 665 RCR299_5_6_OBJ_STATUS_LEFT_3 3 "Invalid" 2 "Measured" 1 "New" 0 "Empty" ;
VAL_ 664 RCR298_6_0_BEHIND_BORDER_LEFT_2 1 "ON" 0 "OFF" ;
VAL_ 664 RCR298_6_1_GHOST_FLG_LEFT_2 1 "ON" 0 "OFF" ;
VAL_ 664 RCR298_5_6_OBJ_STATUS_LEFT_2 3 "Invalid" 2 "Measured" 1 "New" 0 "Empty" ;
VAL_ 663 RCR297_6_0_BEHIND_BORDER_LEFT_1 1 "ON" 0 "OFF" ;
VAL_ 663 RCR297_6_1_GHOST_FLG_LEFT_1 1 "ON" 0 "OFF" ;
VAL_ 663 RCR297_5_6_OBJ_STATUS_LEFT_1 3 "Invalid" 2 "Measured" 1 "New" 0 "Empty" ;
VAL_ 662 RCR296_6_0_BEHIND_BORDER_LEFT_0 1 "ON" 0 "OFF" ;
VAL_ 662 RCR296_6_1_GHOST_FLG_LEFT_0 1 "ON" 0 "OFF" ;
VAL_ 662 RCR296_5_6_OBJ_STATUS_LEFT_0 3 "Invalid" 2 "Measured" 1 "New" 0 "Empty" ;
VAL_ 552 RDR228_7_0_EYE_TIMEOUT_ERROR_FLG 1 "EYE Timeout or Error detect" 0 "Normal" ;
VAL_ 552 RDR228_7_1_BLOCKAGE_FORMING_2 1 "Blocakge2" 0 "Normal" ;
VAL_ 552 RDR228_7_2_WARN_LCA_R_1ST 1 "ON" 0 "OFF" ;
VAL_ 552 RDR228_7_3_WARN_LCA_L_1ST 1 "ON" 0 "OFF" ;
VAL_ 552 RDR228_7_4_WARN_LCA_R_2ND 1 "ON" 0 "OFF" ;
VAL_ 552 RDR228_7_5_WARN_LCA_L_2ND 1 "ON" 0 "OFF" ;
VAL_ 552 RDR228_7_6_WARN_RCTA_R 1 "ON" 0 "OFF" ;
VAL_ 552 RDR228_7_7_WARN_RCTA_L 1 "ON" 0 "OFF" ;
VAL_ 552 RDR228_6_0_WARN_BSD_R_1ST 1 "ON" 0 "OFF" ;
VAL_ 552 RDR228_6_1_WARN_BSD_L_1ST 1 "ON" 0 "OFF" ;
VAL_ 552 RDR228_6_2_WARN_BSD_R_2ND 1 "ON" 0 "OFF" ;
VAL_ 552 RDR228_6_3_WARN_BSD_L_2ND 1 "ON" 0 "OFF" ;
VAL_ 552 RDR228_6_5_BLOCKAGE_STS 5 "INVALID" 4 "BLIND" 3 "HIGH" 2 "MID" 1 "LOW" 0 "NONE" ;
VAL_ 552 RDR228_5_0_BSD_R_E 1 "ON" 0 "OFF" ;
VAL_ 552 RDR228_5_1_BSD_L_E 1 "ON" 0 "OFF" ;
VAL_ 552 RDR228_5_2_LCA_R_E 1 "ON" 0 "OFF" ;
VAL_ 552 RDR228_5_3_LCA_L_E 1 "ON" 0 "OFF" ;
VAL_ 552 RDR228_5_4_BSD_R_A 1 "ON" 0 "OFF" ;
VAL_ 552 RDR228_5_5_BSD_L_A 1 "ON" 0 "OFF" ;
VAL_ 552 RDR228_5_6_LCA_R_A 1 "ON" 0 "OFF" ;
VAL_ 552 RDR228_5_7_LCA_L_A 1 "ON" 0 "OFF" ;
VAL_ 552 RDR228_4_0_DOW_ACTIVELAMP 1 "ON" 0 "OFF" ;
VAL_ 552 RDR228_4_1_WARN_DOW_1ST_R 1 "ON" 0 "OFF" ;
VAL_ 552 RDR228_4_2_WARN_DOW_1ST_L 1 "ON" 0 "OFF" ;
VAL_ 552 RDR228_4_3_WARN_DOW_2ST_R 1 "ON" 0 "OFF" ;
VAL_ 552 RDR228_4_4_WARN_DOW_2ST_L 1 "ON" 0 "OFF" ;
VAL_ 552 RDR228_4_6_CSTM_STS_BSD_LCA_2ND 1 "ON" 0 "OFF" ;
VAL_ 552 RDR228_4_7_CSTM_STS_RCTA 1 "ON" 0 "OFF" ;
VAL_ 552 RDR228_3_0_WARN_BSD_LCA_R_2ND 1 "ON" 0 "OFF" ;
VAL_ 552 RDR228_3_1_WARN_BSD_LCA_L_2ND 1 "ON" 0 "OFF" ;
VAL_ 552 RDR228_3_2_CSTM_STS_DOW 1 "ON" 0 "OFF" ;
VAL_ 552 RDR228_3_3_CSTM_STS_DOW_SFT_POS 1 "ONLY_P" 0 "OTHER_THAN_R" ;
VAL_ 552 RDR228_3_6_CSTM_DSP_BSD_LCA_2ND 1 "ON" 0 "OFF" ;
VAL_ 552 RDR228_3_7_CSTM_DSP_RCTA 1 "ON" 0 "OFF" ;
VAL_ 552 RDR228_2_0_CSTM_DSP_DOW 1 "ON" 0 "OFF" ;
VAL_ 552 RDR228_2_1_EYE_LOCAL_BUS1_FAIL 1 "EYE LOCAL BUS1 FAIL" 0 "NORMAL" ;
VAL_ 552 RDR228_2_2_CSTM_DSP_DOW_SFT_POS 1 "ON" 0 "OFF" ;
VAL_ 552 RDR228_2_3_ELK_STOP_REQ_FLG 1 "ELK stop request flag" 0 "NORMAL" ;
VAL_ 552 RDR228_2_4_FAIL_RDRSYS 1 "FAIL" 0 "NORMAL" ;
VAL_ 552 RDR228_2_5_STOP_RDRSYS 1 "HALT" 0 "NORMAL" ;
VAL_ 552 RDR228_2_6_ON_OFF_RDRSYS 1 "ON" 0 "OFF" ;
VAL_ 552 RDR228_2_7_BLOCKAGE_FORMING 1 "BLOCKAGE" 0 "NORMAL" ;
VAL_ 552 RDR228_1_4_BATT_OFF_CAUSE 1 "OFF required" 0 "ON required" ;
VAL_ 552 RDR228_1_5_CSTM_GLO_1 1 "ON" 0 "OFF" ;
VAL_ 552 RDR228_1_6_CSTM_GLO_3 1 "ON" 0 "OFF" ;
VAL_ 552 RDR228_1_7_CSTM_GLO_2 1 "ON" 0 "OFF" ;
VAL_ 966 EYE3C6_7_7_VEHICLE_L_LANE1 1 "ON" 0 "OFF" ;
VAL_ 966 EYE3C6_6_7_VEHICLE_R_LANE1 1 "ON" 0 "OFF" ;
VAL_ 966 EYE3C6_5_7_VEHICLE_MY_WAY1 1 "ON" 0 "OFF" ;
VAL_ 966 EYE3C6_3_0_RADER_RR 3 "TURN_ON3" 2 "TURN_ON2" 1 "TURN_ON1" 0 "TURN_OFF" ;
VAL_ 966 EYE3C6_3_2_RADER_RL 3 "TURN_ON3" 2 "TURN_ON2" 1 "TURN_ON1" 0 "TURN_OFF" ;
VAL_ 966 EYE3C6_3_4_RADER_FR 3 "No_Definition" 2 "BLINK" 1 "TURN_ON" 0 "TURN_OFF" ;
VAL_ 966 EYE3C6_3_6_RADER_FL 3 "No_Definition" 2 "BLINK" 1 "TURN_ON" 0 "TURN_OFF" ;
VAL_ 966 EYE3C6_2_0_RADER_R 3 "TURN_ON3" 2 "TURN_ON2" 1 "TURN_ON1" 0 "TURN_OFF" ;
VAL_ 966 EYE3C6_2_2_MY_WAY_LANE_CAR_COLOR 3 "TURN_AMBER" 2 "TURN_LIGHT_TJA" 1 "TURN_LIGHT" 0 "TURN_DARK" ;
VAL_ 966 EYE3C6_2_4_TARGET_CAR 7 "No_Definition" 6 "No_Definition" 5 "No_Definition" 4 "No_Definition" 3 "LEFT_LANE" 2 "RIGHT_LANE" 1 "OWN_LANE" 0 "OFF" ;
VAL_ 966 EYE3C6_2_7_ALC_STS 1 "ACTIVE" 0 "NOT_ACTIVE" ;
VAL_ 966 EYE3C6_1_4_L_LANE_CAR_COLOR 3 "TURN_AMBER" 2 "TURN_LIGHT_TJA" 1 "TURN_LIGHT" 0 "TURN_DARK" ;
VAL_ 966 EYE3C6_1_6_R_LANE_CAR_COLOR 3 "TURN_AMBER" 2 "TURN_LIGHT_TJA" 1 "TURN_LIGHT" 0 "TURN_DARK" ;
VAL_ 965 EYE3C5_7_0_GSR_AEBS_FUNC_INFO 1 "Requirement" 0 "No requirement" ;
VAL_ 965 EYE3C5_7_1_CSTM_CRV_ADJUST 3 "HARD" 2 "NORMAL" 1 "SOFT" 0 "OFF" ;
VAL_ 965 EYE3C5_7_3_BRAKE_HAPTIC_CURR 3 "BUZZER OFF/BREAK OFF" 2 "BUZZER OFF/BREAK ON" 1 "BUZZER ON/BREAK OFF" 0 "BUZZER ON/BREAK ON" ;
VAL_ 965 EYE3C5_7_5_SAFETY_MODE_FUNC_INFO 1 "Requirement" 0 "No requirement" ;
VAL_ 965 EYE3C5_7_6_SAFETY_MODE_CURR 1 "enable" 0 "disable" ;
VAL_ 965 EYE3C5_7_7_GSR_DDAW_FUNC_INFO 1 "Requirement" 0 "No requirement" ;
VAL_ 965 EYE3C5_6_0_IND_SAFETY_MODE 1 "TURN_ON" 0 "TURN_OFF" ;
VAL_ 965 EYE3C5_6_1_ALC_ACTIVE_L 1 "TURN_ON" 0 "TURN_OFF" ;
VAL_ 965 EYE3C5_6_2_FLASHING_IND_SAFETY 1 "Blinking" 0 "Nomally indicate" ;
VAL_ 965 EYE3C5_6_3_OVERTAKE_FUNC_INFO 1 "Requirement" 0 "No requirement" ;
VAL_ 965 EYE3C5_6_4_CRV_ADJUST_FUNC_INFO 1 "Requirement" 0 "No requirement" ;
VAL_ 965 EYE3C5_6_5_STRG_TOUCHSENSOR_WRNG 1 "TURN_ON" 0 "TURN_OFF" ;
VAL_ 965 EYE3C5_6_6_ALC_ACTIVE_R 1 "TURN_ON" 0 "TURN_OFF" ;
VAL_ 965 EYE3C5_6_7_CSTM_GSR_ISA 1 "Requirement" 0 "No requirement" ;
VAL_ 965 EYE3C5_5_0_LANE_COLOR_R 3 "BLUE" 2 "No_Definition" 1 "GRAY" 0 "OFF" ;
VAL_ 965 EYE3C5_5_2_LINE_LANE_R 3 "No_Definition" 2 "WHITE" 1 "GRAY" 0 "OFF" ;
VAL_ 965 EYE3C5_5_4_LANE_COLOR_L 3 "BLUE" 2 "No_Definition" 1 "GRAY" 0 "OFF" ;
VAL_ 965 EYE3C5_5_6_LINE_LANE_L 3 "No_Definition" 2 "WHITE" 1 "GRAY" 0 "OFF" ;
VAL_ 965 EYE3C5_4_4_ROAD_SHAPE_DIRECTION 1 "LEFT" 0 "RIGHT" ;
VAL_ 965 EYE3C5_4_5_CSTM_GSR_ELKS 1 "Requirement" 0 "No requirement" ;
VAL_ 965 EYE3C5_4_6_MY_WAY_COLOR 3 "BLUE" 2 "No_Definition" 1 "GRAY" 0 "OFF" ;
VAL_ 965 EYE3C5_3_0_AD_DRV_ICON 3 "No_Definition" 2 "BLUE" 1 "WHITE" 0 "TURN_OFF" ;
VAL_ 965 EYE3C5_3_2_AUTO_HANDLE_ICON 3 "No_Definition" 2 "BLINK" 1 "TURN_ON" 0 "TURN_OFF" ;
VAL_ 965 EYE3C5_3_4_WITH_HANDS_ICON 1 "ON" 0 "OFF" ;
VAL_ 965 EYE3C5_3_5_STRG_HAPTIC_WRNG 1 "TURN_ON" 0 "TURN_OFF" ;
VAL_ 965 EYE3C5_3_6_BRK_HPTC_FUNC_INFO 1 "Requirement" 0 "No requirement" ;
VAL_ 965 EYE3C5_3_7_SPECIAL_DISP_INFO 1 "Requirement" 0 "No requirement" ;
VAL_ 965 EYE3C5_2_0_SLOWDWN_CURVE_ICON 7 "No_Definition" 6 "BLINK③" 5 "TURN_ON③" 4 "BLINK②" 3 "TURN_ON②" 2 "BLINK①" 1 "TURN_ON①" 0 "TURN_OFF" ;
VAL_ 965 EYE3C5_2_3_FLASHING_IND 1 "BLINK" 0 "TURN_ON" ;
VAL_ 965 EYE3C5_2_4_ATTENTION_TOLLGATE 3 "No_Definition" 2 "BLINK" 1 "TURN_ON" 0 "TURN_OFF" ;
VAL_ 965 EYE3C5_2_6_MAPLOCATOR_IND 3 "No_Definition" 2 "FAIL_ON" 1 "TURN_ON" 0 "TURN_OFF" ;
VAL_ 965 EYE3C5_1_4_ISA_FAIL_IND 1 "TURN_ON" 0 "TURN_OFF" ;
VAL_ 965 EYE3C5_1_5_SLWF_OFF_IND 1 "TURN_ON" 0 "TURN_OFF" ;
VAL_ 965 EYE3C5_1_6_CSTM_SLWF_SET 1 "ON" 0 "OFF" ;
VAL_ 965 EYE3C5_1_7_CSTM_TSR_SOUND_SET 1 "ON" 0 "OFF" ;
VAL_ 964 EYE3C4_7_0_PCR_FAIL_OFF_IND 3 "No_Definition" 2 "FAIL" 1 "HALT/Customize OFF" 0 "NORMAL" ;
VAL_ 964 EYE3C4_7_2_AES_FAIL_OFF_IND 3 "No_Definition" 2 "FAIL" 1 "HALT/Customize OFF" 0 "NORMAL" ;
VAL_ 964 EYE3C4_7_4_LDP_FAIL_OFF_IND 3 "No_Definition" 2 "FAIL" 1 "HALT/Customize OFF" 0 "NORMAL" ;
VAL_ 964 EYE3C4_7_6_ELK_FAIL_OFF_IND 3 "No_Definition" 2 "FAIL" 1 "HALT/Customize OFF" 0 "NORMAL" ;
VAL_ 964 EYE3C4_6_0_MCAM_SYS_FAIL_HALT 3 "No_Definition" 2 "FAIL" 1 "HALT" 0 "NORMAL" ;
VAL_ 964 EYE3C4_6_2_MCAM_FUNC_INFO 1 "ON" 0 "OFF" ;
VAL_ 964 EYE3C4_6_3_EYE_DRV_ACTION_REQ 7 "No_Definition" 6 "No_Definition" 5 "No_Definition" 4 "restriction2" 3 "restriction1" 2 "permission" 1 "Prohibition" 0 "No Requirement" ;
VAL_ 964 EYE3C4_6_6_LDW_SND_OFF_FAIL_IND 3 "No_Definition" 2 "FAIL" 1 "OFF" 0 "TURN OFF" ;
VAL_ 964 EYE3C4_5_0_EAM_GREEN 3 "PATTERN3" 2 "PATTERN2" 1 "PATTERN1" 0 "TURN_OFF" ;
VAL_ 964 EYE3C4_5_2_EAM_BLUE 3 "PATTERN3" 2 "PATTERN2" 1 "PATTERN1" 0 "TURN_OFF" ;
VAL_ 964 EYE3C4_5_4_EAM_GREEN_2 3 "No_Definition" 2 "BLINK" 1 "ON" 0 "OFF" ;
VAL_ 964 EYE3C4_5_6_FCW_SND_OFF_FAIL_IND 3 "No_Definition" 2 "FAIL" 1 "OFF" 0 "TURN OFF" ;
VAL_ 964 EYE3C4_4_0_EAM_YELLOW 15 "No Definition" 14 "No_Definition" 13 "No_Definition" 12 "No_Definition" 11 "No_Definition" 10 "No_Definition" 9 "No_Definition" 8 "No_Definition" 7 "PATTERN⑦" 6 "PATTERN⑥" 5 "PATTERN⑤" 4 "PATTERN④" 3 "PATTERN③" 2 "PATTERN②" 1 "PATTERN①" 0 "TURN_OFF" ;
VAL_ 964 EYE3C4_4_4_EAM_RED 15 "No Definition" 14 "No_Definition" 13 "No_Definition" 12 "No_Definition" 11 "No_Definition" 10 "No_Definition" 9 "No_Definition" 8 "No_Definition" 7 "PATTERN⑦" 6 "PATTERN⑥" 5 "PATTERN⑤" 4 "PATTERN④" 3 "PATTERN③" 2 "PATTERN②" 1 "PATTERN①" 0 "TURN_OFF" ;
VAL_ 964 EYE3C4_3_0_CODE_NO_BUZZER 255 "Pattern255" 90 "Pattern90" 89 "Pattern89" 88 "Pattern88" 87 "Pattern87" 86 "Pattern86" 84 "Pattern84" 83 "Pattern83" 82 "Pattern82" 81 "Pattern81" 80 "Pattern80" 79 "Pattern79" 78 "Pattern78" 77 "Pattern77" 76 "Pattern76" 75 "Pattern75" 74 "Pattern74" 73 "Pattern73" 72 "Pattern72" 71 "Pattern71" 70 "Pattern70" 69 "Pattern69" 68 "Pattern68" 67 "Pattern67" 66 "Pattern66" 65 "Pattern65" 64 "Pattern64" 63 "Pattern63" 62 "Pattern62" 61 "Pattern61" 60 "Pattern60" 59 "Pattern59" 49 "Pattern49" 48 "Pattern48" 47 "Pattern47" 46 "Pattern46" 45 "Pattern45" 44 "Pattern44" 43 "Pattern43" 42 "Pattern42" 41 "Pattern41" 40 "Pattern40" 39 "Pattern39" 38 "Pattern38" 37 "Pattern37" 36 "Pattern36" 35 "Pattern35" 34 "Pattern34" 33 "Pattern33" 32 "Pattern32" 31 "Pattern31" 30 "Pattern30" 29 "Pattern29" 28 "Pattern28" 27 "Pattern27" 26 "Pattern26" 25 "Pattern25" 24 "Pattern24" 23 "Pattern23" 22 "Pattern22" 21 "Pattern21" 20 "Pattern20" 19 "Pattern19" 18 "Pattern18" 17 "Pattern17" 16 "Pattern16" 15 "Pattern15" 14 "Pattern14" 13 "Pattern13" 12 "Pattern12" 11 "Pattern11" 10 "Pattern10" 9 "Pattern9" 8 "Pattern8" 7 "Pattern7" 6 "Pattern6" 5 "Pattern5" 4 "Pattern4" 3 "Pattern3" 2 "Pattern2" 1 "Pattern1" 0 "OFF" ;
VAL_ 964 EYE3C4_2_0_CODE_WARN 255 "Pattern255" 166 "Pattern166" 165 "Pattern165" 164 "Pattern164" 163 "Pattern163" 162 "Pattern162" 161 "Pattern161" 160 "Pattern160" 159 "Pattern159" 158 "Pattern158" 157 "Pattern157" 156 "Pattern156" 155 "Pattern155" 154 "Pattern154" 153 "Pattern153" 152 "Pattern152" 151 "Pattern151" 150 "Pattern150" 149 "Pattern149" 148 "Pattern148" 147 "Pattern147" 146 "Pattern146" 145 "Pattern145" 144 "Pattern144" 90 "Pattern90" 89 "Pattern89" 88 "Pattern88" 87 "Pattern87" 86 "Pattern86" 85 "Pattern85" 84 "Pattern84" 83 "Pattern83" 82 "Pattern82" 81 "Pattern81" 80 "Pattern80" 79 "Pattern79" 78 "Pattern78" 77 "Pattern77" 76 "Pattern76" 75 "Pattern75" 74 "Pattern74" 73 "Pattern73" 72 "Pattern72" 71 "Pattern71" 70 "Pattern70" 69 "Pattern69" 68 "Pattern68" 67 "Pattern67" 66 "Pattern66" 65 "Pattern65" 64 "Pattern64" 63 "Pattern63" 62 "Pattern62" 61 "Pattern61" 60 "Pattern60" 59 "Pattern59" 58 "Pattern58" 57 "Pattern57" 56 "Pattern56" 55 "Pattern55" 54 "Pattern54" 53 "Pattern53" 52 "Pattern52" 51 "Pattern51" 50 "Pattern50" 49 "Pattern49" 48 "Pattern48" 47 "Pattern47" 46 "Pattern46" 45 "Pattern45" 44 "Pattern44" 43 "Pattern43" 42 "Pattern42" 41 "Pattern41" 40 "Pattern40" 39 "Pattern39" 38 "Pattern38" 37 "Pattern37" 36 "Pattern36" 35 "Pattern35" 34 "Pattern34" 33 "Pattern33" 32 "Pattern32" 31 "Pattern31" 30 "Pattern30" 29 "Pattern29" 28 "Pattern28" 27 "Pattern27" 26 "Pattern26" 25 "Pattern25" 24 "Pattern24" 23 "Pattern23" 22 "Pattern22" 21 "Pattern21" 20 "Pattern20" 19 "Pattern19" 18 "Pattern18" 17 "Pattern17" 16 "Pattern16" 15 "Pattern15" 14 "Pattern14" 13 "Pattern13" 12 "Pattern12" 11 "Pattern11" 10 "Pattern10" 9 "Pattern9" 8 "Pattern8" 7 "Pattern7" 6 "Pattern6" 5 "Pattern5" 4 "Pattern4" 3 "Pattern3" 2 "Pattern2" 1 "Pattern1" 0 "OFF" ;
VAL_ 964 EYE3C4_1_5_SNR_DRV_ACTION_REQ 7 "No_Definition" 6 "No_Definition" 5 "No_Definition" 4 "Restriction2" 3 "Restriction1" 2 "Permission" 1 "Prohibition" 0 "No Requirement" ;
VAL_ 805 EYE325_6_5_SONAR_DISP_INT 1 "DISP_INT_ON" 0 "DISP_INT_OFF" ;
VAL_ 805 EYE325_5_0_SONAR_R_L_CORNER_4LVL 7 "No_Definition" 6 "No_Definition" 5 "No_Definition" 4 "MOST_NEAR" 3 "NEAR" 2 "MIDDLE" 1 "FAR" 0 "CLEAR" ;
VAL_ 805 EYE325_5_3_SONAR_R_R_CORNER_4LVL 7 "No_Definition" 6 "No_Definition" 5 "No_Definition" 4 "MOST_NEAR" 3 "NEAR" 2 "MIDDLE" 1 "FAR" 0 "CLEAR" ;
VAL_ 805 EYE325_4_0_SONAR_R_CENTER 7 "No_Definition" 6 "No_Definition" 5 "No_Definition" 4 "MOST_NEAR" 3 "NEAR" 2 "MIDDLE" 1 "FAR" 0 "CLEAR" ;
VAL_ 805 EYE325_4_3_SONAR_LEVEL 7 "No_Definition" 6 "FAR" 5 "FIRST_BRAKE" 4 "SECOND_BRAKE" 3 "MOST_NEAR" 2 "NEAR" 1 "MIDDLE" 0 "OFF" ;
VAL_ 805 EYE325_4_6_RAB_WARNING 3 "RAB_Interrupt_3" 2 "RAB_Interrupt_2" 1 "RAB_Interrupt_1" 0 "OFF" ;
VAL_ 805 EYE325_3_0_SONAR_R_L_CORNER 3 "NEAR" 2 "MIDDLE" 1 "FAR" 0 "CLEAR" ;
VAL_ 805 EYE325_3_2_SONAR_R_R_CORNER 3 "NEAR" 2 "MIDDLE" 1 "FAR" 0 "CLEAR" ;
VAL_ 805 EYE325_3_4_SONAR_R_L_SIDE 3 "NEAR" 2 "MIDDLE" 1 "FAR" 0 "CLEAR" ;
VAL_ 805 EYE325_3_6_SONAR_R_R_SIDE 3 "NEAR" 2 "MIDDLE" 1 "FAR" 0 "CLEAR" ;
VAL_ 805 EYE325_2_0_RAB_OFF 1 "RAB_OFF" 0 "RAB_ON" ;
VAL_ 805 EYE325_2_1_SONAR_OFF 1 "SONAR_OFF" 0 "SONAR_ON" ;
VAL_ 805 EYE325_2_2_SONAR_SYS_HALT 3 "No_Definition" 2 "HALT_2" 1 "HALT_1" 0 "NO_HALT" ;
VAL_ 805 EYE325_2_4_SONAR_SYS_FAIL 3 "No_Definition" 2 "FAIL_2" 1 "FAIL_1" 0 "NO_FAIL" ;
VAL_ 805 EYE325_2_6_RAB_DISABLE 1 "ON" 0 "OFF" ;
VAL_ 805 EYE325_2_7_SONAR_DISABLE 1 "ON" 0 "OFF" ;
VAL_ 805 EYE325_1_4_CSTM_RAB_SET 1 "ON" 0 "OFF" ;
VAL_ 805 EYE325_1_5_CSTM_CLR_SNR_SET 1 "ON" 0 "OFF" ;
VAL_ 805 EYE325_1_6_RAB 1 "ON" 0 "OFF" ;
VAL_ 805 EYE325_1_7_SONAR_NO_DISP 1 "ON" 0 "OFF" ;
VAL_ 804 EYE324_7_5_TSR_MODE_DISP 3 "TURN_ON_BLUE" 2 "TURN_ON_GREEN" 1 "TURN_ON_WHITE" 0 "TURN_OFF" ;
VAL_ 804 EYE324_7_7_ICON_IND 1 "TURN_ON" 0 "TURN_OFF" ;
VAL_ 804 EYE324_6_0_COMPLEMENTARY_IND_C 15 "Reserved" 14 "Reserved" 13 "Reserved" 12 "Reserved" 11 "Reserved" 10 "Reserved" 9 "Reserved" 8 "Reserved" 7 "Reserved" 6 "Arrow Right" 5 "Arrow Left" 4 "Time" 3 "Snow/Ice" 2 "Wet road" 1 "Auxiliary sign" 0 "Not indicate" ;
VAL_ 804 EYE324_6_4_COMPLEMENTARY_IND_D 15 "Reserved" 14 "Reserved" 13 "Reserved" 12 "Reserved" 11 "Reserved" 10 "Reserved" 9 "Reserved" 8 "Reserved" 7 "Reserved" 6 "Arrow Right" 5 "Arrow Left" 4 "Time" 3 "Snow/Ice" 2 "Wet road" 1 "Auxiliary sign" 0 "Not indicate" ;
VAL_ 804 EYE324_4_0_TRAFFIC_SIGN_B 31 "Reserved" 30 "Reserved" 29 "Reserved" 28 "Reserved" 27 "Reserved" 26 "Reserved" 25 "Reserved" 24 "One-Way(up)" 23 "One-Way(right)" 22 "No Passing(RHD)" 21 "No entry (DOM)" 20 "Pause (DOM)" 19 "No overtaking (DOM)" 18 "Preferred road" 17 "Road closure" 16 "Forward precedence road" 15 "Pause" 14 "No entry" 13 "Cancel no overtaking" 12 "No overtaking" 11 "Residential Zone" 10 "One-way(left)" 9 "GiveWay" 8 "Reserved" 7 "Release speed limit(mile)" 6 "Release speed limit(km)" 5 "Full release" 4 "Speed limit design(Sweden)" 3 "Speed limit unknown" 2 "Not applying sign recog." 1 "Limited speed (EU/AU/JP)" 0 "Not indicate" ;
VAL_ 804 EYE324_4_5_FLASHING_IND_B 1 "Blinking" 0 "Nomally indicate" ;
VAL_ 804 EYE324_4_6_FRAME_COLOR_B 3 "No_Definition" 2 "GREEN" 1 "WHITE" 0 "OFF" ;
VAL_ 804 EYE324_2_0_TRAFFIC_SIGN_A 31 "Reserved" 30 "Reserved" 29 "Reserved" 28 "Reserved" 27 "Reserved" 26 "Reserved" 25 "Reserved" 24 "One-Way(up)" 23 "One-Way(right)" 22 "No Passing(RHD)" 21 "No entry (DOM)" 20 "Pause (DOM)" 19 "No overtaking (DOM)" 18 "Preferred road" 17 "Road closure" 16 "Forward precedence road" 15 "Pause" 14 "No entry" 13 "Cancel no overtaking" 12 "No overtaking" 11 "Residential Zone" 10 "One-way" 9 "GiveWay" 8 "Reserved" 7 "Release speed limit(mile)" 6 "Release speed limit(km)" 5 "Full release" 4 "Speed limit design(Sweden)" 3 "Speed limit unknown" 2 "Not applying sign recog." 1 "Limited speed (EU/AU/JP)" 0 "Not indicate" ;
VAL_ 804 EYE324_2_5_FLASHING_IND_A 1 "Blinking" 0 "Nomally indicate" ;
VAL_ 804 EYE324_2_6_FRAME_COLOR_A 3 "No_Definition" 2 "GREEN" 1 "WHITE" 0 "OFF" ;
VAL_ 804 EYE324_1_4_FLASHING_IND_D 1 "Blinking" 0 "Nomally indicate" ;
VAL_ 804 EYE324_1_5_FLASHING_IND_C 1 "Blinking" 0 "Nomally indicate" ;
VAL_ 804 EYE324_1_6_ICON_COLOR 3 "No_Definition" 2 "BLUE" 1 "GREEN" 0 "WHITE" ;
VAL_ 803 EYE323_7_5_SLIF_FUNC_INFO 1 "Requirement" 0 "No requirement" ;
VAL_ 803 EYE323_7_6_ISA_FUNC_INFO 1 "Requirement" 0 "No requirement" ;
VAL_ 803 EYE323_7_7_ISA_CUSTOMIZE_CURR 1 "ISA enable" 0 "ISA disable" ;
VAL_ 803 EYE323_6_0_LDW_OFFSW_INFO 1 "requirement" 0 "No requirement" ;
VAL_ 803 EYE323_6_1_LDW_ON_OFF_SET 1 "enable" 0 "disable" ;
VAL_ 803 EYE323_6_2_CSTM_DDAW_WARN_SET 1 "ON" 0 "OFF" ;
VAL_ 803 EYE323_6_3_IACC_FUNC_INFO 1 "Requirement" 0 "No requirement" ;
VAL_ 803 EYE323_6_5_CSTM_LDW_TIMING_SET 1 "LATE" 0 "EARLY" ;
VAL_ 803 EYE323_6_6_CSTM_LDW_TIMING 1 "Requirement" 0 "No requirement" ;
VAL_ 803 EYE323_6_7_SLOWDOWNL_FUNC_INFO 1 "Requirement" 0 "No requirement" ;
VAL_ 803 EYE323_5_0_CNG_GRN_CONT_CURR 1 "enable" 0 "disable" ;
VAL_ 803 EYE323_5_1_TRAFFIC_FUNC_INFO 1 "Requirement" 0 "No requirement" ;
VAL_ 803 EYE323_5_2_FCW_OFFSW_INFO 1 "requirement" 0 "No requirement" ;
VAL_ 803 EYE323_5_3_FCW_ON_OFF_SET 1 "enable" 0 "disable" ;
VAL_ 803 EYE323_5_4_WARNING_SEL_CURR 1 "Vibration" 0 "Sound" ;
VAL_ 803 EYE323_5_5_HAPT_FUNC_INFO 1 "Requirement" 0 "No requirement" ;
VAL_ 803 EYE323_5_6_TOLLGATE_CONT_CURR 1 "enable" 0 "disable" ;
VAL_ 803 EYE323_5_7_CURVE_CONT_CURR 1 "enable" 0 "disable" ;
VAL_ 803 EYE323_4_0_FCTB_ICON_L 3 "No_Definition" 2 "BLINK" 1 "TURN_ON" 0 "TURN_OFF" ;
VAL_ 803 EYE323_4_2_FCTB_ICON_R 3 "No_Definition" 2 "BLINK" 1 "TURN_ON" 0 "TURN_OFF" ;
VAL_ 803 EYE323_4_4_FCW_CONT_CURR 3 "OFF" 2 "FAR" 1 "NEAR" 0 "ON/STD." ;
VAL_ 803 EYE323_4_6_FCW_DISPLAY_SEL 3 "FULL SELECT" 2 "ON/OFF SELECT" 1 "Distance SELECT" 0 "TURN OFF" ;
VAL_ 803 EYE323_3_0_AES_FUNC_INFO 1 "Requirement" 0 "No requirement" ;
VAL_ 803 EYE323_3_1_CSTM_TSR_NO_ENTRY_SET 1 "ON" 0 "OFF" ;
VAL_ 803 EYE323_3_2_CSTM_TSR_STOP_SET 1 "ON" 0 "OFF" ;
VAL_ 803 EYE323_3_3_CSTM_TSR_GIVE_WAY_SET 1 "ON" 0 "OFF" ;
VAL_ 803 EYE323_3_4_WILDERNESS 1 "WILDERNESS" 0 "NOT_WILDERNESS" ;
VAL_ 803 EYE323_3_5_AES_OFF 1 "TURN_ON" 0 "TURN_OFF" ;
VAL_ 803 EYE323_3_6_FCTB_IND 3 "No_Definition" 2 "FAIL_ON" 1 "TURN_ON" 0 "TURN_OFF" ;
VAL_ 803 EYE323_2_0_CSTM_LDW_ALK_B 3 "ALK-B ON /LDW ON" 2 "ALK-B ON /LDW OFF" 1 "ALK-B OFF/LDW ON" 0 "ALK-B OFF/LDW OFF" ;
VAL_ 803 EYE323_2_2_CSTM_P_CR 1 "ON" 0 "OFF" ;
VAL_ 803 EYE323_2_3_SLOWDOWN_FUNC_INFO2 1 "Requirement" 0 "No requirement" ;
VAL_ 803 EYE323_2_4_CID_CODE_WARN 15 "Drowsiness attention" 14 "Eyes on request(3rd/4th)" 13 "Eyes on request(2nd)" 12 "MRM Interruption Vehicle" 11 "MRM Interruption Steering" 10 "MRM Interruption Lane change" 9 "MRM Stop" 8 "Handle steering" 7 "MRM Lane change Left" 6 "MRM Lane change Right" 5 "MRM Road shoulder Evacuation" 4 "B1 no-opr. cancel alarm" 3 "B1 no-opr. warning(long)" 2 "MRM Operation Notice" 1 "PreCrashBreak(1st)/Brake incr. alarm" 0 "No alarm " ;
VAL_ 803 EYE323_1_4_DISP_FOLLOW_FORWARD 1 "ON" 0 "OFF" ;
VAL_ 803 EYE323_1_5_KEEP_LINE_SENTER_ACT 1 "ON" 0 "OFF" ;
VAL_ 803 EYE323_1_6_DDAW_FAIL_OFF 3 "No_Definition" 2 "OFF" 1 "FAIL" 0 "TURN_OFF" ;
VAL_ 802 EYE322_7_0_CSTM_ACC_CONT_SET 3 "Lv.4" 2 "Lv.3" 1 "Lv.2" 0 "Lv.1" ;
VAL_ 802 EYE322_7_2_ELK_OFF_IND 1 "ON" 0 "OFF" ;
VAL_ 802 EYE322_7_3_LIGHT_EAM_YELLOW 3 "TURN_ON" 2 "BLINK_FAST" 1 "NONE" 0 "NONE" ;
VAL_ 802 EYE322_7_5_BROKEN_LINE_L 1 "DASHEDLINE" 0 "SOLIDLINE" ;
VAL_ 802 EYE322_7_6_TJA_ACTIVE 1 "ON" 0 "OFF" ;
VAL_ 802 EYE322_7_7_BROKEN_LINE_R 1 "DASHEDLINE" 0 "SOLIDLINE" ;
VAL_ 802 EYE322_6_0_CSTM_MIS_AT_START 3 "ON(20km/h)/(15mph)" 2 "ON(15km/h)/(10mph)" 1 "ON(10km/h)/(5mph)" 0 "OFF" ;
VAL_ 802 EYE322_6_2_CSTM_ALK_TJA_SET 1 "ON" 0 "OFF" ;
VAL_ 802 EYE322_6_3_CSTM_LANE_SET 1 "LEFT" 0 "RIGHT" ;
VAL_ 802 EYE322_6_4_LDP_OFF_IND 1 "TURN_ON" 0 "TURN_OFF" ;
VAL_ 802 EYE322_6_5_INDICATOR_MODE_L 3 "NONE" 2 "BLINK" 1 "TURN_ON" 0 "TURN_OFF" ;
VAL_ 802 EYE322_6_7_CSTM_ELK_SET 1 "ON" 0 "OFF" ;
VAL_ 802 EYE322_5_0_CSTM_MIS_AT_BACK 1 "ACTIVE" 0 "NON_ACTIVE" ;
VAL_ 802 EYE322_5_1_CSTM_ALK_TJA 1 "ACTIVE" 0 "NON_ACTIVE" ;
VAL_ 802 EYE322_5_2_CSTM_SAS 1 "ACTIVE" 0 "NON_ACTIVE" ;
VAL_ 802 EYE322_5_3_CSTM_HBA 1 "ACTIVE" 0 "NON_ACTIVE" ;
VAL_ 802 EYE322_5_4_CSTM_ACC_CONT 1 "ACTIVE" 0 "NON_ACTIVE" ;
VAL_ 802 EYE322_5_5_CSTM_LANE 1 "ACTIVE" 0 "NON_ACTIVE" ;
VAL_ 802 EYE322_5_6_LDW_SOUND_OFF_IND 1 "TURN_ON" 0 "TURN_OFF" ;
VAL_ 802 EYE322_5_7_CSTM_ELK_SET 1 "CSTM_ELK_ON" 0 "CSTM_ELK_OFF" ;
VAL_ 802 EYE322_4_0_CODE_WARN 31 "No_Definition" 30 "WARN_ALK_No_Steering_CONT(Only_Buzzer)" 29 "No_Definition" 28 "WARN_LKSA(No_Steering_CONT_Long)" 27 "ALK_Cancel(Only_Buzzer)" 26 "ACC_Cancel(Only_Buzzer)" 25 "Catch/Lost_Buzzer" 24 "Buzzer(No_Display)" 23 "No_Definition" 22 "No_Definition" 21 "No_Definition" 20 "Long Intervention(ALKB)" 19 "Blue Traffic Light Alert" 18 "WARN_ALK_System_Limit" 17 "No_Definition" 16 "WARN_ELK_Left" 15 "WARN_ELK_Right" 14 "Forward_Start_INFO" 13 "WARN_Lane_Sway" 12 "WARN_Lane_Departure(LDW/LDP) Left" 11 "WARN_Lane_Departure(LDW/LDP) Right" 10 "No_Definition" 9 "PreCrash_BRK(Stop_Warning)" 8 "WARN_Red_Signal" 7 "No_Definition" 6 "No_Definition" 5 "AfterPreCrash_BRK(Stopping)" 4 "AT_Accidental_Backward_Start(FMW)" 3 "AT_Accidental_Backward_Start(Speed_Limit_Warning)" 2 "PreCrash_BRK(First)" 1 "PreCrash_BRK(Second)" 0 "No_Warning" ;
VAL_ 802 EYE322_4_5_CSTM_GSR 1 "Requirement" 0 "No Requirement" ;
VAL_ 802 EYE322_3_0_LANE_L 3 "No_Definition" 2 "BLINK" 1 "TURN_ON" 0 "TURN_OFF" ;
VAL_ 802 EYE322_3_2_LANE_R 3 "No_Definition" 2 "BLINK" 1 "TURN_ON" 0 "TURN_OFF" ;
VAL_ 802 EYE322_3_4_LANE_L_COLOR 3 "AMBER" 2 "OTHER" 1 "WHITE" 0 "SUB" ;
VAL_ 802 EYE322_3_6_LANE_R_COLOR 3 "AMBER" 2 "OTHER" 1 "WHITE" 0 "SUB" ;
VAL_ 802 EYE322_2_0_FCW_OFF_IND 1 "TURN_ON" 0 "TURN_OFF" ;
VAL_ 802 EYE322_2_1_MOV_EYESIGHT_SCREEN 1 "DISP_EYE" 0 "OFF" ;
VAL_ 802 EYE322_2_2_ALK_ICON 3 "BLINK_GREEN" 2 "TURN_ON_GREEN" 1 "TURN_ON_WHITE" 0 "TURN_OFF" ;
VAL_ 802 EYE322_2_4_INDICATOR_CTRL_REQ 1 "ON" 0 "OFF" ;
VAL_ 802 EYE322_2_5_INDICATOR_MODE_R 3 "NONE" 2 "BLINK" 1 "TURN_ON" 0 "TURN_OFF" ;
VAL_ 802 EYE322_2_7_LIMITER_BACK_SPEED 1 "ON" 0 "OFF" ;
VAL_ 802 EYE322_1_4_CODE_NO_BUZZER 7 "WARN_LKSA(No_Steering_CONT_Long)" 6 "AfterPreCrash_BRK(Running)" 5 "Driver_Over_Ride" 4 "MT_Put_In_Gear_Request" 3 "MT_Shift_Down_Request" 2 "MT_Shift_Up_Request" 1 "WARN_LKSA(No_Steering_CONT)" 0 "No_Warning" ;
VAL_ 802 EYE322_1_7_DISTWARN_DMS 1 "ON" 0 "OFF" ;
VAL_ 801 EYE321_7_0_INFO_DIST_FORWARD 15 "75 ≦ x" 14 "70 ≦ x < 75" 13 "65 ≦ x < 70" 12 "60 ≦ x < 65" 11 "55 ≦ x < 60" 10 "50 ≦ x < 55" 9 "45 ≦ x < 50" 8 "40 ≦ x < 45" 7 "35 ≦ x < 40" 6 "30 ≦ x < 35" 5 "25 ≦ x < 30" 4 "20 ≦ x < 25" 3 "15 ≦ x < 20" 2 "10 ≦ x < 15" 1 "5 ≦ x < 10" 0 "0 ≦ x < 5" ;
VAL_ 801 EYE321_7_4_INFO_KEEP_STOP 1 "TURN_ON" 0 "TURN_OFF" ;
VAL_ 801 EYE321_7_5_INFO_READY 1 "TURN_ON" 0 "TURN_OFF" ;
VAL_ 801 EYE321_7_6_INFO_SET_CC 1 "TURN_ON" 0 "TURN_OFF" ;
VAL_ 801 EYE321_7_7_INFO_OFF 1 "TURN_ON" 0 "TURN_OFF" ;
VAL_ 801 EYE321_6_0_FAIL_EYESIGHT 1 "FAIL" 0 "NORMAL" ;
VAL_ 801 EYE321_6_1_MOV_EYESIGHT_SCREEN 1 "DISP_EYE" 0 "OFF" ;
VAL_ 801 EYE321_6_2_IND_VEHICLE 1 "TURN_ON" 0 "TURN_OFF" ;
VAL_ 801 EYE321_6_3_BRAKELAMP_VEHICLE 1 "TURN_ON" 0 "TURN_OFF" ;
VAL_ 801 EYE321_6_4_IND_FORWARD_VECL 1 "TURN_ON" 0 "TURN_OFF" ;
VAL_ 801 EYE321_6_5_BRAKELAMP_FORWARD 1 "TURN_ON" 0 "TURN_OFF" ;
VAL_ 801 EYE321_6_6_CC_OR_LIM_SON 1 "SET" 0 "Non-SET" ;
VAL_ 801 EYE321_6_7_TEMP_OFF_STATE 1 "Temp OFF State" 0 "Normal State" ;
VAL_ 801 EYE321_4_0_ACC_MODE 3 "No_Definition" 2 "SAS" 1 "CC" 0 "ACC" ;
VAL_ 801 EYE321_4_2_SRVD_LASTMEM_ST_REQ 1 "LASTMEM_STARTUP_REQ" 0 "ON_STARTUP_REQ" ;
VAL_ 801 EYE321_4_3_INFO_MAIN_CC 3 "TURN_ON_BLUE or BLINK_GREEN" 2 "TURN_ON_GREEN" 1 "TURN_ON_WHITE" 0 "TURN_OFF" ;
VAL_ 801 EYE321_4_5_TRAFFIC_LIGHT 7 "No_Definition" 6 "No_Definition" 5 "BLINK_BLUE" 4 "TURN_ON_BLUE" 3 "BLINK_RED" 2 "TURN_ON_RED" 1 "TURN_ON_DISP" 0 "TURN_OFF" ;
VAL_ 801 EYE321_3_0_CODE_HALT 7 "HALT_NOTICE" 6 "No_Definition" 5 "No_Definition" 4 "HALT_E3" 3 "HALT_E2" 2 "HALT_E1-2" 1 "HALT_E1-1" 0 "No HALT" ;
VAL_ 801 EYE321_3_3_ELK_EQUIP 1 "EQUIP_ELK" 0 "NOT_EQUIP_ELK" ;
VAL_ 801 EYE321_3_4_SET_DIST 7 "No_Definition" 6 "No_Definition" 5 "No_Definition" 4 "Distance(4)" 3 "Distance(3)" 2 "Distance(2)" 1 "Distance(1)" 0 "No_Display" ;
VAL_ 801 EYE321_3_7_TJA 1 "ON" 0 "OFF" ;
VAL_ 801 EYE321_2_0_ACC_CANCEL_OR_CSTM 15 "No_Definition" 14 "No_Definition" 13 "No_Definition" 12 "No_Definition" 11 "Pattern11" 10 "Pattern10" 9 "Pattern9" 8 "Pattern8" 7 "Pattern7" 6 "Pattern6" 5 "Pattern5" 4 "Pattern4" 3 "Pattern3" 2 "Pattern2" 1 "Pattern1" 0 "OFF" ;
VAL_ 801 EYE321_2_4_ALK_CANCEL_OR_CSTM 7 "Lka_Cancel_DMS_Undetected" 6 "No_Definition" 5 "Lka_Cancel_Speed_High" 4 "Lka_Cancel_Speed_Low" 3 "Lka_Cancel_Other" 2 "Lka_Cancel_No_Steering_CONT" 1 "Lka_Cancel_Curve" 0 "No_Display" ;
VAL_ 801 EYE321_2_7_ALK_CANCEL_DISP_TYPE 1 "ALK-Bｷｬﾝｾﾙ時" 0 "ALK-Cｷｬﾝｾﾙ時" ;
VAL_ 801 EYE321_1_4_PRECRASH_BRAKE_OFF 1 "TURN_ON" 0 "TURN_OFF" ;
VAL_ 801 EYE321_1_5_LANE_DEPARTURE_OFF 1 "TURN_ON" 0 "TURN_OFF" ;
VAL_ 801 EYE321_1_6_MET_AD_DRV_ASS 1 "ON" 0 "OFF" ;
VAL_ 801 EYE321_1_7_ALC_EQUIP 1 "ON" 0 "OFF" ;
VAL_ 289 EYE121_3_0_RAB_TRQ_LIM_STAT 15 "No_Definition" 14 "No_Definition" 13 "No_Definition" 12 "No_Definition" 11 "No_Definition" 10 "No_Definition" 9 "No_Definition" 8 "No_Definition" 7 "No_Definition" 6 "No_Definition" 5 "No_Definition" 4 "No_Definition" 3 "No_Definition" 2 "ZENZOU" 1 "ACTIVE" 0 "No_Control" ;
VAL_ 289 EYE121_3_4_RAB_BRAKE_STAT 15 "No_Definition" 14 "No_Definition" 13 "No_Definition" 12 "No_Definition" 11 "No_Definition" 10 "No_Definition" 9 "No_Definition" 8 "No_Definition" 7 "No_Definition" 6 "No_Definition" 5 "No_Definition" 4 "ZENGEN" 3 "STOP_HOJI" 2 "BRAKING" 1 "YOATSU" 0 "No_Control" ;
VAL_ 289 EYE121_2_0_EYE_INIT 1 "INIT_END" 0 "INIT" ;
VAL_ 289 EYE121_2_1_RAB_ACT_OK 1 "OK" 0 "NG" ;
VAL_ 289 EYE121_2_2_RAB_FAIL 1 "FAIL" 0 "NORMAL" ;
VAL_ 289 EYE121_2_3_RAB_OFF 1 "RAB_OFF" 0 "NORMAL" ;
VAL_ 289 EYE121_2_4_FMWR_ACTIVE 1 "FMWR_ON" 0 "OFF" ;
VAL_ 289 EYE121_1_7_EQUIP_EPB 1 "ON" 0 "OFF" ;
VAL_ 287 ADAS11F_3_4_HANDSOFF_FLG 1 "HANDSON" 0 "HANDSOFF" ;
VAL_ 287 ADAS11F_3_5_TRQ_LIMIT_REQ_FLG 1 "ON" 0 "OFF" ;
VAL_ 292 ADAS124_7_3_TRQ_RATE_CHG 1 "RATE2" 0 "RATE1" ;
VAL_ 292 ADAS124_7_4_STR_RATE_CHG 3 "RATE3" 2 "RATE3" 1 "RATE2" 0 "RATE1" ;
VAL_ 292 ADAS124_7_6_OVR_STR_LVL 3 "LV4" 2 "LV3" 1 "LV2" 0 "LV1" ;
VAL_ 292 ADAS124_1_4_ACTIVE_FLG 3 "NORMAL" 2 "STEER_ANGLE" 1 "NORMAL_AND_STEER_ANGLE" 0 "NORMAL" ;
VAL_ 471 MVS1D7_13_2_CAM_LVL4 3 "Level_3" 2 "Level_2" 1 "Level_1" 0 "Level_0" ;
VAL_ 471 MVS1D7_13_4_TRG_ID4 15 "No_Definition" 14 "No_Definition" 13 "No_Definition" 12 "No_Definition" 11 "No_Definition" 10 "No_Definition" 9 "No_Definition" 8 "Target8" 7 "Target7" 6 "Target6" 5 "Target5" 4 "Target4" 3 "Target3" 2 "Target2" 1 "Target1" 0 "No_Target" ;
VAL_ 471 MVS1D7_10_2_CAM_LVL3 3 "Level_4" 2 "Level_2" 1 "Level_1" 0 "Level_0" ;
VAL_ 471 MVS1D7_10_4_TRG_ID3 15 "No_Definition" 14 "No_Definition" 13 "No_Definition" 12 "No_Definition" 11 "No_Definition" 10 "No_Definition" 9 "No_Definition" 8 "Target8" 7 "Target7" 6 "Target6" 5 "Target5" 4 "Target4" 3 "Target3" 2 "Target2" 1 "Target1" 0 "No_Target" ;
VAL_ 471 MVS1D7_6_2_CAM_LVL2 3 "Level_3" 2 "Level_2" 1 "Level_1" 0 "Level_0" ;
VAL_ 471 MVS1D7_6_4_TRG_ID2 15 "No_Definition" 14 "No_Definition" 13 "No_Definition" 12 "No_Definition" 11 "No_Definition" 10 "No_Definition" 9 "No_Definition" 8 "Target8" 7 "Target7" 6 "Target6" 5 "Target5" 4 "Target4" 3 "Target3" 2 "Target2" 1 "Target1" 0 "No_Target" ;
VAL_ 471 MVS1D7_3_2_CAM_LVL1 3 "Level_3" 2 "Level_2" 1 "Level_1" 0 "Level_0" ;
VAL_ 471 MVS1D7_3_4_TRG_ID1 15 "No_Definition" 14 "No_Definition" 13 "No_Definition" 12 "No_Definition" 11 "No_Definition" 10 "No_Definition" 9 "No_Definition" 8 "Target8" 7 "Target7" 6 "Target6" 5 "Target5" 4 "Target4" 3 "Target3" 2 "Target2" 1 "Target1" 0 "No_Target" ;
VAL_ 470 MVS1D6_16_4_CMDHALT 3 "Reserved" 2 "Gate Hatch Open" 1 "Dirt" 0 "No Dirt" ;
VAL_ 470 MVS1D6_16_6_CMDFAIL 3 "No Finished Factory Setting" 2 "Fail" 1 "Pre Fail" 0 "Nomal" ;
VAL_ 470 MVS1D6_13_2_CAM_LVL4 3 "Level_3" 2 "Level_2" 1 "Level_1" 0 "Level_0" ;
VAL_ 470 MVS1D6_13_4_TRG_ID4 15 "No_Definition" 14 "No_Definition" 13 "No_Definition" 12 "No_Definition" 11 "No_Definition" 10 "No_Definition" 9 "No_Definition" 8 "Target8" 7 "Target7" 6 "Target6" 5 "Target5" 4 "Target4" 3 "Target3" 2 "Target2" 1 "Target1" 0 "No_Target" ;
VAL_ 470 MVS1D6_10_2_CAM_LVL3 3 "Level_3" 2 "Level_2" 1 "Level_1" 0 "Level_0" ;
VAL_ 470 MVS1D6_10_4_TRG_ID3 15 "No_Definition" 14 "No_Definition" 13 "No_Definition" 12 "No_Definition" 11 "No_Definition" 10 "No_Definition" 9 "No_Definition" 8 "Target8" 7 "Target7" 6 "Target6" 5 "Target5" 4 "Target4" 3 "Target3" 2 "Target2" 1 "Target1" 0 "No_Target" ;
VAL_ 470 MVS1D6_6_2_CAM_LVL2 3 "Level_3" 2 "Level_2" 1 "Level_1" 0 "Level_0" ;
VAL_ 470 MVS1D6_6_4_TRG_ID2 15 "No_Definition" 14 "No_Definition" 13 "No_Definition" 12 "No_Definition" 11 "No_Definition" 10 "No_Definition" 9 "No_Definition" 8 "Target8" 7 "Target7" 6 "Target6" 5 "Target5" 4 "Target4" 3 "Target3" 2 "Target2" 1 "Target1" 0 "No_Target" ;
VAL_ 470 MVS1D6_3_2_CAM_LVL1 3 "Level_3" 2 "Level_2" 1 "Level_1" 0 "Level_0" ;
VAL_ 470 MVS1D6_3_4_TRG_ID1 15 "No_Definition" 14 "No_Definition" 13 "No_Definition" 12 "No_Definition" 11 "No_Definition" 10 "No_Definition" 9 "No_Definition" 8 "Target8" 7 "Target7" 6 "Target6" 5 "Target5" 4 "Target4" 3 "Target3" 2 "Target2" 1 "Target1" 0 "No_Target" ;
VAL_ 279 SNR117_16_0_CSTM_SNR_DSPREEQ 3 "No_Definition" 2 "Disp(Gray out)" 1 "Disp(Normal)" 0 "No Disp" ;
VAL_ 279 SNR117_16_2_CSTM_RAB_DSPREQ 3 "No_Definition" 2 "Disp(Gray out)" 1 "Disp(Normal)" 0 "No Disp" ;
VAL_ 279 SNR117_16_4_CSTM_PED_DSPREQ 3 "No_Definition" 2 "Disp(Gray out)" 1 "Disp(Normal)" 0 "No Disp" ;
VAL_ 279 SNR117_16_6_CSTM_PEDTIM_DSPREQ 3 "No_Definition" 2 "Disp(Gray out)" 1 "Disp(Normal)" 0 "No Disp" ;
VAL_ 279 SNR117_15_0_CSTM_SNR_CLEAR 1 "ON" 0 "OFF" ;
VAL_ 279 SNR117_15_1_CSTM_RAB 1 "ON" 0 "OFF" ;
VAL_ 279 SNR117_15_2_CSTM_RAB_PED 1 "ON" 0 "OFF" ;
VAL_ 279 SNR117_15_3_CSTM_RAB_PED_TIMING 3 "No_Definition" 2 "Far" 1 "Near" 0 "Middle" ;
VAL_ 279 SNR117_14_0_RAB_WARNING 7 "No_Definition" 6 "No_Definition" 5 "RAB_Interrupt_5" 4 "RAB_Interrupt_4" 3 "RAB_Interrupt_3" 2 "RAB_Interrupt_2" 1 "RAB_Interrupt_1" 0 "OFF" ;
VAL_ 279 SNR117_14_3_SONAR_LEVEL 8 "No_Definition" 7 "Pedestrian" 6 "FIRST_BRAKE" 5 "FAR" 4 "MIDDLE" 3 "NEAR" 2 "MOST_NEAR" 1 "SECOND_BRAKE" 0 "OFF" ;
VAL_ 279 SNR117_13_0_PED_WARN_CENTER 1 "ON" 0 "OFF" ;
VAL_ 279 SNR117_13_1_PED_WARN_LEFT 1 "ON" 0 "OFF" ;
VAL_ 279 SNR117_13_2_PED_WARN_RIGHT 1 "ON" 0 "OFF" ;
VAL_ 279 SNR117_13_3_RAB_TRIG_TYPE 3 "Cyclist" 2 "Pedestrian" 1 "USS" 0 "NoAct" ;
VAL_ 279 SNR117_9_0_SONAR_R_R_CORNER_4LV 7 "No_Definition" 6 "No_Definition" 5 "No_Definition" 4 "MOST_NEAR" 3 "NEAR" 2 "MIDDLE" 1 "FAR" 0 "CLEAR" ;
VAL_ 279 SNR117_8_0_SONAR_DISP_INT 1 "DISP_INT_ON" 0 "DISP_INT_OFF" ;
VAL_ 279 SNR117_8_1_SONAR_R_CENTER 7 "No_Definition" 6 "No_Definition" 5 "No_Definition" 4 "MOST_NEAR" 3 "NEAR" 2 "MIDDLE" 1 "FAR" 0 "CLEAR" ;
VAL_ 279 SNR117_8_4_SONAR_R_L_CORNER_4LV 7 "No_Definition" 6 "No_Definition" 5 "No_Definition" 4 "MOST_NEAR" 3 "NEAR" 2 "MIDDLE" 1 "FAR" 0 "CLEAR" ;
VAL_ 279 SNR117_7_0_SONAR_SYS_FAIL 3 "No_Definition" 2 "FAIL_2" 1 "FAIL_1" 0 "NO_FAIL" ;
VAL_ 279 SNR117_7_2_RAB_HALT 3 "No_Definition" 2 "HALT_2" 1 "HALT_1" 0 "NO_HALT" ;
VAL_ 279 SNR117_7_4_CAMERA_FAIL 3 "No_Definition" 2 "FAIL_2" 1 "FAIL_1" 0 "NO_FAIL" ;
VAL_ 279 SNR117_7_6_RAB_PED_HALT 3 "No_Definition" 2 "HALT_2" 1 "HALT_1" 0 "NO_HALT" ;
VAL_ 279 SNR117_6_0_REQ_ACT_EPB 1 "ON" 0 "OFF" ;
VAL_ 279 SNR117_6_1_STOP_HOJI_BUZ_ACT 1 "ON" 0 "OFF" ;
VAL_ 279 SNR117_6_2_RAB_OFF 1 "RAB_OFF" 0 "RAB_ON" ;
VAL_ 279 SNR117_6_3_SONAR_OFF 1 "SONAR_OFF" 0 "SONAR_ON" ;
VAL_ 279 SNR117_6_4_RAB_PED_OFF 1 "RAB_PED_OFF" 0 "RAB_PED_ON" ;
VAL_ 279 SNR117_6_5_SONAR_HALT 3 "No_Definition" 2 "HALT_2" 1 "HALT_1" 0 "NO_HALT" ;
VAL_ 279 SNR117_5_0_YOATSU_ACT 1 "ON" 0 "OFF" ;
VAL_ 279 SNR117_5_1_TORQUE_LIM_ACT 1 "ON" 0 "OFF" ;
VAL_ 279 SNR117_4_0_RAB_ACT 1 "ON" 0 "OFF" ;
VAL_ 279 SNR117_3_0_RAB 1 "ON" 0 "OFF" ;
VAL_ 279 SNR117_3_1_RAB_PED 1 "ON" 0 "OFF" ;
VAL_ 845 ADAS34D_16_0_CSTM_SNR_DSPREEQ 3 "No_Definition" 2 "Disp(Gray out)" 1 "Disp(Normal)" 0 "No Disp" ;
VAL_ 845 ADAS34D_16_2_CSTM_RAB_DSPREQ 3 "No_Definition" 2 "Disp(Gray out)" 1 "Disp(Normal)" 0 "No Disp" ;
VAL_ 845 ADAS34D_16_4_CSTM_PED_DSPREQ 3 "No_Definition" 2 "Disp(Gray out)" 1 "Disp(Normal)" 0 "No Disp" ;
VAL_ 845 ADAS34D_16_6_CSTM_PEDTIM_DSPREQ 3 "No_Definition" 2 "Disp(Gray out)" 1 "Disp(Normal)" 0 "No Disp" ;
VAL_ 845 ADAS34D_15_0_CSTM_SNR_CLEAR 1 "ON" 0 "OFF" ;
VAL_ 845 ADAS34D_15_1_CSTM_RAB 1 "ON" 0 "OFF" ;
VAL_ 845 ADAS34D_15_2_CSTM_RAB_PED 1 "ON" 0 "OFF" ;
VAL_ 845 ADAS34D_15_3_CSTM_RAB_PED_TIMING 3 "No_Definition" 2 "Far" 1 "Near" 0 "Middle" ;
VAL_ 845 ADAS34D_15_5_CSTM_TEMP_OFF 3 "未定義" 2 "OFF" 1 "ON" 0 "No Disp" ;
VAL_ 845 ADAS34D_15_7_TEMP_OFF_STATE 1 "Temp OFF State" 0 "Normal State" ;
VAL_ 845 ADAS34D_14_0_RAB_WARNING 7 "No_Definition" 6 "No_Definition" 5 "RAB_Interrupt_5" 4 "RAB_Interrupt_4" 3 "RAB_Interrupt_3" 2 "RAB_Interrupt_2" 1 "RAB_Interrupt_1" 0 "OFF" ;
VAL_ 845 ADAS34D_14_3_SONAR_LEVEL 8 "No_Definition" 7 "Pedestrian" 6 "FIRST_BRAKE" 5 "FAR" 4 "MIDDLE" 3 "NEAR" 2 "MOST_NEAR" 1 "SECOND_BRAKE" 0 "OFF" ;
VAL_ 845 ADAS34D_13_0_PED_WARN_CENTER 1 "ON" 0 "OFF" ;
VAL_ 845 ADAS34D_13_1_PED_WARN_LEFT 1 "ON" 0 "OFF" ;
VAL_ 845 ADAS34D_13_2_PED_WARN_RIGHT 1 "ON" 0 "OFF" ;
VAL_ 845 ADAS34D_13_3_RAB_TRIG_TYPE 3 "Cyclist" 2 "Pedestrian" 1 "USS" 0 "NoAct" ;
VAL_ 845 ADAS34D_9_0_SONAR_R_R_CORNER_4LV 7 "No_Definition" 6 "No_Definition" 5 "No_Definition" 4 "MOST_NEAR" 3 "NEAR" 2 "MIDDLE" 1 "FAR" 0 "CLEAR" ;
VAL_ 845 ADAS34D_8_0_SONAR_DISP_INT 1 "DISP_INT_ON" 0 "DISP_INT_OFF" ;
VAL_ 845 ADAS34D_8_1_SONAR_R_CENTER 7 "No_Definition" 6 "No_Definition" 5 "No_Definition" 4 "MOST_NEAR" 3 "NEAR" 2 "MIDDLE" 1 "FAR" 0 "CLEAR" ;
VAL_ 845 ADAS34D_8_4_SONAR_R_L_CORNER_4LV 7 "No_Definition" 6 "No_Definition" 5 "No_Definition" 4 "MOST_NEAR" 3 "NEAR" 2 "MIDDLE" 1 "FAR" 0 "CLEAR" ;
VAL_ 845 ADAS34D_7_0_SONAR_SYS_FAIL 3 "No_Definition" 2 "FAIL_2" 1 "FAIL_1" 0 "NO_FAIL" ;
VAL_ 845 ADAS34D_7_2_RAB_HALT 3 "No_Definition" 2 "HALT_2" 1 "HALT_1" 0 "NO_HALT" ;
VAL_ 845 ADAS34D_7_4_CAMERA_FAIL 3 "No_Definition" 2 "FAIL_2" 1 "FAIL_1" 0 "NO_FAIL" ;
VAL_ 845 ADAS34D_7_6_RAB_PED_HALT 3 "No_Definition" 2 "HALT_2" 1 "HALT_1" 0 "NO_HALT" ;
VAL_ 845 ADAS34D_6_0_REQ_ACT_EPB 1 "ON" 0 "OFF" ;
VAL_ 845 ADAS34D_6_1_STOP_HOJI_BUZ_ACT 1 "ON" 0 "OFF" ;
VAL_ 845 ADAS34D_6_2_RAB_OFF 1 "RAB_OFF" 0 "RAB_ON" ;
VAL_ 845 ADAS34D_6_3_SONAR_OFF 1 "SONAR_OFF" 0 "SONAR_ON" ;
VAL_ 845 ADAS34D_6_4_RAB_PED_OFF 1 "RAB_PED_OFF" 0 "RAB_PED_ON" ;
VAL_ 845 ADAS34D_6_5_SONAR_HALT 3 "No_Definition" 2 "HALT_2" 1 "HALT_1" 0 "NO_HALT" ;
VAL_ 845 ADAS34D_5_0_YOATSU_ACT 1 "ON" 0 "OFF" ;
VAL_ 845 ADAS34D_5_1_TORQUE_LIM_ACT 1 "ON" 0 "OFF" ;
VAL_ 845 ADAS34D_4_0_RAB_ACT 1 "ON" 0 "OFF" ;
VAL_ 845 ADAS34D_3_0_RAB 1 "ON" 0 "OFF" ;
VAL_ 845 ADAS34D_3_1_RAB_PED 1 "ON" 0 "OFF" ;
VAL_ 844 ADAS34C_25_0_CSTM_ADDON_DISP_CNT 1 "ON" 0 "OFF" ;
VAL_ 844 ADAS34C_25_1_CSTM_LANE_SET_CONT 1 "ON" 0 "OFF" ;
VAL_ 844 ADAS34C_24_0_CSTM_LSW 1 "ON" 0 "OFF" ;
VAL_ 844 ADAS34C_24_1_CSTM_GREEN_LIGHT 1 "ON" 0 "OFF" ;
VAL_ 844 ADAS34C_24_2_CSTM_LANE_SET 1 "LEFT" 0 "RIGHT" ;
VAL_ 844 ADAS34C_24_3_CSTM_PROPOSAL_HMI 1 "ON" 0 "OFF" ;
VAL_ 844 ADAS34C_24_4_CSTM_V2N 1 "ON" 0 "OFF" ;
VAL_ 844 ADAS34C_24_5_CSTM_DATA_COLLECT 1 "ON" 0 "OFF" ;
VAL_ 844 ADAS34C_24_6_CSTM_COLLECT_IMAGE 1 "ON" 0 "OFF" ;
VAL_ 844 ADAS34C_24_7_CSTM_COLLECT_LOC 1 "ON" 0 "OFF" ;
VAL_ 844 ADAS34C_22_0_DATA_COLLECT_DISP 3 "Grey_out" 2 "Disp(With_setting_parts)" 1 "Disp(No_setting_parts)" 0 "No_Disp" ;
VAL_ 844 ADAS34C_22_2_COLLECT_IMAGE_DISP 3 "Grey_out" 2 "Disp(With_setting_parts)" 1 "Disp(No_setting_parts)" 0 "No_Disp" ;
VAL_ 844 ADAS34C_22_4_COLLECT_LOC_DISP 3 "Grey_out" 2 "Disp(With_setting_parts)" 1 "Disp(No_setting_parts)" 0 "No_Disp" ;
VAL_ 844 ADAS34C_21_0_LSW_DISP_CONT 3 "Grey_out" 2 "Disp(With_setting_parts)" 1 "Disp(No_setting_parts)" 0 "No_Disp" ;
VAL_ 844 ADAS34C_21_2_GREEN_LIGHT_DISP 3 "Grey_out" 2 "Disp(With_setting_parts)" 1 "Disp(No_setting_parts)" 0 "No_Disp" ;
VAL_ 844 ADAS34C_21_4_LANE_SET_DISP_CONT 3 "Grey_out" 2 "Disp(With_setting_parts)" 1 "Disp(No_setting_parts)" 0 "No_Disp" ;
VAL_ 844 ADAS34C_21_6_PROPOSAL_HMI_DISP 3 "Grey_out" 2 "Disp(With_setting_parts)" 1 "Disp(No_setting_parts)" 0 "No_Disp" ;
VAL_ 844 ADAS34C_20_0_ADD_ON_DISP_CONT 3 "Grey_out" 2 "Disp(With_setting_parts)" 1 "Disp(No_setting_parts)" 0 "No_Disp" ;
VAL_ 844 ADAS34C_20_2_V2N_DISP_CONT 3 "Grey_out" 2 "Disp(With_setting_parts)" 1 "Disp(No_setting_parts)" 0 "No_Disp" ;
VAL_ 844 ADAS34C_20_4_LANE_SET_PTN_DISP 3 "Grey_out" 2 "Disp(With_setting_parts)" 1 "Disp(No_setting_parts)" 0 "No_Disp" ;
VAL_ 844 ADAS34C_18_0_CSTM_SUPPRESS_SPEED 1 "ON" 0 "OFF" ;
VAL_ 844 ADAS34C_18_1_SUPPRESS_SPD_LEVEL 3 "No_Definition" 2 "High" 1 "Low" 0 "Middle" ;
VAL_ 844 ADAS34C_18_3_ACTIVE_AVOIDANCE 1 "ON" 0 "OFF" ;
VAL_ 844 ADAS34C_18_4_ACTIVE_AVOIDANCE_LV 3 "No_Definition" 2 "High" 1 "Low" 0 "Middle" ;
VAL_ 844 ADAS34C_17_0_CSTM_PDA_CURR 1 "ON" 0 "OFF" ;
VAL_ 844 ADAS34C_17_1_TARGET_VEHICLE 1 "ON" 0 "OFF" ;
VAL_ 844 ADAS34C_17_2_TARGET_SURROUNDING 1 "ON" 0 "OFF" ;
VAL_ 844 ADAS34C_17_3_TARGET_SLOPE_DOWN 1 "ON" 0 "OFF" ;
VAL_ 844 ADAS34C_17_4_CUS_SUPPRESS_SPDTGT 1 "ON" 0 "OFF" ;
VAL_ 844 ADAS34C_15_0_A_AVOIDANCE_DISP 3 "Grey_out" 2 "Disp(With_setting_parts)" 1 "Disp(No_setting_parts)" 0 "No_Disp" ;
VAL_ 844 ADAS34C_15_2_A_AVOIDANCE_LV_DISP 3 "Grey_out" 2 "Disp(With_setting_parts)" 1 "Disp(No_setting_parts)" 0 "No_Disp" ;
VAL_ 844 ADAS34C_15_4_A_AVOIDANCE_LV_PTN 3 "Pattern④(Low/High)" 2 "Pattern③(Middle/High)" 1 "Pattern②(Low/Middle)" 0 "Pattern①(Low/Middle/High)" ;
VAL_ 844 ADAS34C_14_0_SUPPRESS_SPDTGT_DSP 3 "Grey_out" 2 "Disp(With_setting_parts)" 1 "Disp(No_setting_parts)" 0 "No_Disp" ;
VAL_ 844 ADAS34C_14_2_TARGET_VEHICLE_DISP 3 "Grey_out" 2 "Disp(With_setting_parts)" 1 "Disp(No_setting_parts)" 0 "No_Disp" ;
VAL_ 844 ADAS34C_14_4_TARGET_SURROUND_DSP 3 "Grey_out" 2 "Disp(With_setting_parts)" 1 "Disp(No_setting_parts)" 0 "No_Disp" ;
VAL_ 844 ADAS34C_14_6_TGT_SLOPE_DOWN_DSP 3 "Grey_out" 2 "Disp(With_setting_parts)" 1 "Disp(No_setting_parts)" 0 "No_Disp" ;
VAL_ 844 ADAS34C_13_0_PDA_DISP_CONT 3 "Grey_out" 2 "Disp(With_setting_parts)" 1 "Disp(No_setting_parts)" 0 "No_Disp" ;
VAL_ 844 ADAS34C_13_2_SUPPRESS_SPD_DISP 3 "Grey_out" 2 "Disp(With_setting_parts)" 1 "Disp(No_setting_parts)" 0 "No_Disp" ;
VAL_ 844 ADAS34C_13_4_SUPPRESS_SPDLV_DISP 3 "Grey_out" 2 "Disp(With_setting_parts)" 1 "Disp(No_setting_parts)" 0 "No_Disp" ;
VAL_ 844 ADAS34C_13_6_SUPPRESS_SPD_LV_PTN 3 "Pattern④(Low/High)" 2 "Pattern③(Middle/High)" 1 "Pattern②(Low/Middle)" 0 "Pattern①(Low/Middle/High)" ;
VAL_ 844 ADAS34C_11_0_ISA_OFS_U50_DISP 3 "Grey_out" 2 "Disp(With_setting_parts)" 1 "Disp(No_setting_parts)" 0 "No_Disp" ;
VAL_ 844 ADAS34C_11_2_ISA_OFS_OV50_DISP 3 "Grey_out" 2 "Disp(With_setting_parts)" 1 "Disp(No_setting_parts)" 0 "No_Disp" ;
VAL_ 844 ADAS34C_10_0_SLWF_OFFSET_OV50 31 "No_Definition" 30 "No_Definition" 29 "No_Definition" 28 "No_Definition" 27 "No_Definition" 26 "No_Definition" 25 "No_Definition" 24 "No_Definition" 23 "No_Definition" 22 "No_Definition" 21 "No_Definition" 20 "10" 19 "9" 18 "8" 17 "7" 16 "6" 15 "5" 14 "4" 13 "3" 12 "2" 11 "1" 10 "0" 9 "-1" 8 "-2" 7 "-3" 6 "-4" 5 "-5" 4 "-6" 3 "-7" 2 "-8" 1 "-9" 0 "-10" ;
VAL_ 844 ADAS34C_9_0_SLWF_OFFSET_U50 31 "No_Definition" 30 "No_Definition" 29 "No_Definition" 28 "No_Definition" 27 "No_Definition" 26 "No_Definition" 25 "No_Definition" 24 "No_Definition" 23 "No_Definition" 22 "No_Definition" 21 "No_Definition" 20 "10" 19 "9" 18 "8" 17 "7" 16 "6" 15 "5" 14 "4" 13 "3" 12 "2" 11 "1" 10 "0" 9 "-1" 8 "-2" 7 "-3" 6 "-4" 5 "-5" 4 "-6" 3 "-7" 2 "-8" 1 "-9" 0 "-10" ;
VAL_ 844 ADAS34C_9_5_CSTM_SLWF 1 "ON" 0 "OFF" ;
VAL_ 844 ADAS34C_9_6_CSTM_SLWF_OFS_CONT 1 "ON" 0 "OFF" ;
VAL_ 844 ADAS34C_9_7_ISA_IACC_OFS_CONT 1 "ON" 0 "OFF" ;
VAL_ 844 ADAS34C_8_0_ISA_IACC_OFFSET_OV50 31 "No_Definition" 30 "No_Definition" 29 "No_Definition" 28 "No_Definition" 27 "No_Definition" 26 "No_Definition" 25 "No_Definition" 24 "No_Definition" 23 "No_Definition" 22 "No_Definition" 21 "No_Definition" 20 "10" 19 "9" 18 "8" 17 "7" 16 "6" 15 "5" 14 "4" 13 "3" 12 "2" 11 "1" 10 "0" 9 "-1" 8 "-2" 7 "-3" 6 "-4" 5 "-5" 4 "-6" 3 "-7" 2 "-8" 1 "-9" 0 "-10" ;
VAL_ 844 ADAS34C_8_5_SIGN_SWITCH_SOUND 1 "ON" 0 "OFF" ;
VAL_ 844 ADAS34C_8_6_CSTM_LOADSIGNS_SYS 1 "ON" 0 "OFF" ;
VAL_ 844 ADAS34C_8_7_CSTM_ISA_IACC_CONT 1 "ON" 0 "OFF" ;
VAL_ 844 ADAS34C_7_0_ISA_IACC_OFFSET_U50 31 "No_Definition" 30 "No_Definition" 29 "No_Definition" 28 "No_Definition" 27 "No_Definition" 26 "No_Definition" 25 "No_Definition" 24 "No_Definition" 23 "No_Definition" 22 "No_Definition" 21 "No_Definition" 20 "10" 19 "9" 18 "8" 17 "7" 16 "6" 15 "5" 14 "4" 13 "3" 12 "2" 11 "1" 10 "0" 9 "-1" 8 "-2" 7 "-3" 6 "-4" 5 "-5" 4 "-6" 3 "-7" 2 "-8" 1 "-9" 0 "-10" ;
VAL_ 844 ADAS34C_7_5_CSTM_LOADSIGNS_ADD 1 "ON" 0 "OFF" ;
VAL_ 844 ADAS34C_7_6_CSTM_ISA_IACC_ACCEPT 3 "No_Definition" 2 "Accept" 1 "Intelligent" 0 "Manual" ;
VAL_ 844 ADAS34C_6_0_ISA_IACC_PTN_DISP 3 "Grey_out" 2 "Disp(With_setting_parts)" 1 "Disp(No_setting_parts)" 0 "No_Disp" ;
VAL_ 844 ADAS34C_6_2_SLWF_OFS_U50_DISP 3 "Grey_out" 2 "Disp(With_setting_parts)" 1 "Disp(No_setting_parts)" 0 "No_Disp" ;
VAL_ 844 ADAS34C_6_4_SLWF_OFS_OV50_DISP 3 "Grey_out" 2 "Disp(With_setting_parts)" 1 "Disp(No_setting_parts)" 0 "No_Disp" ;
VAL_ 844 ADAS34C_5_0_SLWF_DISP_CONT 3 "Grey_out" 2 "Disp(With_setting_parts)" 1 "Disp(No_setting_parts)" 0 "No_Disp" ;
VAL_ 844 ADAS34C_5_2_ISA_IACC_OFSET_DISP 3 "Grey_out" 2 "Disp(With_setting_parts)" 1 "Disp(No_setting_parts)" 0 "No_Disp" ;
VAL_ 844 ADAS34C_5_4_SLWF_OFSET_DISP 3 "Grey_out" 2 "Disp(With_setting_parts)" 1 "Disp(No_setting_parts)" 0 "No_Disp" ;
VAL_ 844 ADAS34C_5_6_SIGNSWITCH_SND_DISP 3 "Grey_out" 2 "Disp(With_setting_parts)" 1 "Disp(No_setting_parts)" 0 "No_Disp" ;
VAL_ 844 ADAS34C_4_0_LOADSIGN_DISP_CONT 3 "Grey_out" 2 "Disp(With_setting_parts)" 1 "Disp(No_setting_parts)" 0 "No_Disp" ;
VAL_ 844 ADAS34C_4_2_LOADSIGN_ADD_DISP 3 "Grey_out" 2 "Disp(With_setting_parts)" 1 "Disp(No_setting_parts)" 0 "No_Disp" ;
VAL_ 844 ADAS34C_4_4_ISA_IACC_ACCEPT_DISP 3 "Grey_out" 2 "Disp(With_setting_parts)" 1 "Disp(No_setting_parts)" 0 "No_Disp" ;
VAL_ 844 ADAS34C_4_6_ISA_IACC_ACCEPT_PTN 3 "No_Definition" 2 "No_Definition" 1 "Pattern②(Manual/Intelligent/Accept)" 0 "Pattern①(Manual/Intelligent)" ;
VAL_ 844 ADAS34C_3_0_EYE_VALID 1 "valid" 0 "invalid" ;
VAL_ 843 ADAS34B_31_0_CSTM_ACC_FUNC_CONT 1 "ON" 0 "OFF" ;
VAL_ 843 ADAS34B_30_0_CSTM_ACC_CONT_SET 3 "Lv.4(Dynamic)" 2 "Lv.3(Standard)" 1 "Lv.2(Comfort)" 0 "Lv.1(Eco)" ;
VAL_ 843 ADAS34B_30_2_CSTM_ACC_OVERTAKE 1 "ON" 0 "OFF" ;
VAL_ 843 ADAS34B_30_3_CSTM_ACC_TARGET_OPT 1 "ON" 0 "OFF" ;
VAL_ 843 ADAS34B_30_4_CSTM_ACC_STOP_CONT 1 "ON" 0 "OFF" ;
VAL_ 843 ADAS34B_30_5_CSTM_ACC_SLOWDOWN 1 "ON" 0 "OFF" ;
VAL_ 843 ADAS34B_30_6_CSTM_ACC_HIGHWAY 1 "ON" 0 "OFF" ;
VAL_ 843 ADAS34B_30_7_CSTM_ACC_SYS 1 "ON" 0 "OFF" ;
VAL_ 843 ADAS34B_28_0_ACC_TARGET_OPT_DISP 3 "Grey_out" 2 "Disp(With_setting_parts)" 1 "Disp(No_setting_parts)" 0 "No_Disp" ;
VAL_ 843 ADAS34B_28_2_ACC_STOP_DISP 3 "Grey_out" 2 "Disp(With_setting_parts)" 1 "Disp(No_setting_parts)" 0 "No_Disp" ;
VAL_ 843 ADAS34B_28_4_ACC_SLOWDOWN_DISP 3 "Grey_out" 2 "Disp(With_setting_parts)" 1 "Disp(No_setting_parts)" 0 "No_Disp" ;
VAL_ 843 ADAS34B_28_6_ACC_HIGHWAY_DISP 3 "Grey_out" 2 "Disp(With_setting_parts)" 1 "Disp(No_setting_parts)" 0 "No_Disp" ;
VAL_ 843 ADAS34B_27_0_ACC_DISP_CONT 3 "Grey_out" 2 "Disp(With_setting_parts)" 1 "Disp(No_setting_parts)" 0 "No_Disp" ;
VAL_ 843 ADAS34B_27_2_ACC_LEVEL_DISP_CONT 3 "Grey_out" 2 "Disp(With_setting_parts)" 1 "Disp(No_setting_parts)" 0 "No_Disp" ;
VAL_ 843 ADAS34B_27_4_ACC_OVERTAKE_DISP 3 "Grey_out" 2 "Disp(With_setting_parts)" 1 "Disp(No_setting_parts)" 0 "No_Disp" ;
VAL_ 843 ADAS34B_27_6_ACC_LEVEL_PTN_DISP 3 "Grey_out" 2 "Disp(With_setting_parts)" 1 "Disp(No_setting_parts)" 0 "No_Disp" ;
VAL_ 843 ADAS34B_25_0_CSTM_ACTIVE_LKS 1 "ON" 0 "OFF" ;
VAL_ 843 ADAS34B_25_1_CSTM_A_LKS_AUTOPASS 1 "ON" 0 "OFF" ;
VAL_ 843 ADAS34B_25_2_CSTM_A_LKS_NAVI 1 "ON" 0 "OFF" ;
VAL_ 843 ADAS34B_25_3_CSTM_A_LKS_OFFSET 1 "ON" 0 "OFF" ;
VAL_ 843 ADAS34B_25_4_CSTM_A_LKS_OPT_CONT 1 "ON" 0 "OFF" ;
VAL_ 843 ADAS34B_23_0_A_LKS_OPTION_DISP 3 "Grey_out" 2 "Disp(With_setting_parts)" 1 "Disp(No_setting_parts)" 0 "No_Disp" ;
VAL_ 843 ADAS34B_23_2_A_LKS_AUTOPASS_DISP 3 "Grey_out" 2 "Disp(With_setting_parts)" 1 "Disp(No_setting_parts)" 0 "No_Disp" ;
VAL_ 843 ADAS34B_23_4_A_LKS_NAVI_DISP 3 "Grey_out" 2 "Disp(With_setting_parts)" 1 "Disp(No_setting_parts)" 0 "No_Disp" ;
VAL_ 843 ADAS34B_23_6_A_LKS_OFFSET_DISP 3 "Grey_out" 2 "Disp(With_setting_parts)" 1 "Disp(No_setting_parts)" 0 "No_Disp" ;
VAL_ 843 ADAS34B_22_0_ACTIVE_LKS_DISP 3 "Grey_out" 2 "Disp(With_setting_parts)" 1 "Disp(No_setting_parts)" 0 "No_Disp" ;
VAL_ 843 ADAS34B_21_0_CSTM_LDW_TMG_CNT 1 "ON" 0 "OFF" ;
VAL_ 843 ADAS34B_21_1_CSTM_LDPTARGET_CONT 1 "ON" 0 "OFF" ;
VAL_ 843 ADAS34B_21_2_ELK_ASSISTTYPE_CONT 1 "ON" 0 "OFF" ;
VAL_ 843 ADAS34B_20_0_CSTM_ELK 1 "ON" 0 "OFF" ;
VAL_ 843 ADAS34B_20_1_CSTM_ELK_SOUND 1 "ON" 0 "OFF" ;
VAL_ 843 ADAS34B_20_2_CSTM_ELK_VIB 1 "ON" 0 "OFF" ;
VAL_ 843 ADAS34B_20_3_CSTM_ELK_CTRL 1 "ON" 0 "OFF" ;
VAL_ 843 ADAS34B_20_4_CSTM_LDW_TIMING 3 "No_Definition" 2 "Early" 1 "Late" 0 "Middle" ;
VAL_ 843 ADAS34B_20_6_LDW_SOUND_ON_OFF_SW 1 "ON" 0 "OFF" ;
VAL_ 843 ADAS34B_20_7_CSTM_LD_ASSISTTYPE 1 "ON" 0 "OFF" ;
VAL_ 843 ADAS34B_19_0_CSTM_LANE_DEPARTURE 1 "ON" 0 "OFF" ;
VAL_ 843 ADAS34B_19_1_CSTM_LDW_SOUND 1 "ON" 0 "OFF" ;
VAL_ 843 ADAS34B_19_2_CSTM_LDW_VIB 1 "ON" 0 "OFF" ;
VAL_ 843 ADAS34B_19_3_CSTM_LDP 1 "ON" 0 "OFF" ;
VAL_ 843 ADAS34B_19_4_LDP_TGT_SOLIDLINE 1 "ON" 0 "OFF" ;
VAL_ 843 ADAS34B_19_5_LDP_TGT_DASHLINE 1 "ON" 0 "OFF" ;
VAL_ 843 ADAS34B_19_6_LDP_TGT_SIDE_OBJ 1 "ON" 0 "OFF" ;
VAL_ 843 ADAS34B_19_7_LDP_TGT_SIDE_VHCL 1 "ON" 0 "OFF" ;
VAL_ 843 ADAS34B_17_0_ELK_ASSISTTYPE_DISP 3 "Grey_out" 2 "Disp(With_setting_parts)" 1 "Disp(No_setting_parts)" 0 "No_Disp" ;
VAL_ 843 ADAS34B_17_2_ELK_SOUND_DISP_CONT 3 "Grey_out" 2 "Disp(With_setting_parts)" 1 "Disp(No_setting_parts)" 0 "No_Disp" ;
VAL_ 843 ADAS34B_17_4_ELK_VIB_DISP_CONT 3 "Grey_out" 2 "Disp(With_setting_parts)" 1 "Disp(No_setting_parts)" 0 "No_Disp" ;
VAL_ 843 ADAS34B_17_6_ELK_CTRL_DISP_CONT 3 "Grey_out" 2 "Disp(With_setting_parts)" 1 "Disp(No_setting_parts)" 0 "No_Disp" ;
VAL_ 843 ADAS34B_16_0_LDW_TIMING_DISP 3 "Grey_out" 2 "Disp(With_setting_parts)" 1 "Disp(No_setting_parts)" 0 "No_Disp" ;
VAL_ 843 ADAS34B_16_2_LDW_TIMING_PTN 7 "No_Definition" 6 "No_Definition" 5 "No_Definition" 4 "Pattern⑤(Late/Middle/Early/Intelligent)" 3 "Pattern④(Late/Early)" 2 "Pattern③(Middle/Early)" 1 "Pattern②(Late/Middle)" 0 "Pattern①(Late/Middle/Early)" ;
VAL_ 843 ADAS34B_16_6_LDW_TIMING_PTN_DISP 3 "Grey_out" 2 "Disp(With_setting_parts)" 1 "Disp(No_setting_parts)" 0 "No_Disp" ;
VAL_ 843 ADAS34B_15_0_TGT_SOLIDLINE_DISP 3 "Grey_out" 2 "Disp(With_setting_parts)" 1 "Disp(No_setting_parts)" 0 "No_Disp" ;
VAL_ 843 ADAS34B_15_2_TGT_DASHLINE_DISP 3 "Grey_out" 2 "Disp(With_setting_parts)" 1 "Disp(No_setting_parts)" 0 "No_Disp" ;
VAL_ 843 ADAS34B_15_4_TGT_SIDE_OBJ_DISP 3 "Grey_out" 2 "Disp(With_setting_parts)" 1 "Disp(No_setting_parts)" 0 "No_Disp" ;
VAL_ 843 ADAS34B_15_6_TGT_SIDE_VHCL_DISP 3 "Grey_out" 2 "Disp(With_setting_parts)" 1 "Disp(No_setting_parts)" 0 "No_Disp" ;
VAL_ 843 ADAS34B_14_0_LD_ASSISTTYPE_DISP 3 "Grey_out" 2 "Disp(With_setting_parts)" 1 "Disp(No_setting_parts)" 0 "No_Disp" ;
VAL_ 843 ADAS34B_14_2_LDW_SOUND_DISP_CONT 3 "Grey_out" 2 "Disp(With_setting_parts)" 1 "Disp(No_setting_parts)" 0 "No_Disp" ;
VAL_ 843 ADAS34B_14_4_LDW_VIB_DISP_CONT 3 "Grey_out" 2 "Disp(With_setting_parts)" 1 "Disp(No_setting_parts)" 0 "No_Disp" ;
VAL_ 843 ADAS34B_14_6_LDP_DISP_CONT 3 "Grey_out" 2 "Disp(With_setting_parts)" 1 "Disp(No_setting_parts)" 0 "No_Disp" ;
VAL_ 843 ADAS34B_13_0_LANE_DEPARTURE_DISP 3 "Grey_out" 2 "Disp(With_setting_parts)" 1 "Disp(No_setting_parts)" 0 "No_Disp" ;
VAL_ 843 ADAS34B_13_2_LDPTARGET_DISP_CONT 3 "Grey_out" 2 "Disp(With_setting_parts)" 1 "Disp(No_setting_parts)" 0 "No_Disp" ;
VAL_ 843 ADAS34B_13_4_LDW_SOUND_SW_DISP 3 "Grey_out" 2 "Disp(With_setting_parts)" 1 "Disp(No_setting_parts)" 0 "No_Disp" ;
VAL_ 843 ADAS34B_13_6_ELK_DISP_CONT 3 "Grey_out" 2 "Disp(With_setting_parts)" 1 "Disp(No_setting_parts)" 0 "No_Disp" ;
VAL_ 843 ADAS34B_11_0_CSTM_MIS_AT_BACK 1 "ON" 0 "OFF" ;
VAL_ 843 ADAS34B_11_1_MIS_AT_BACK_SPD_LIM 3 "No_Definition" 2 "High(20km/h)/(15mph)" 1 "Middle(15km/h)/(10mph)" 0 "Low(10km/h)/(5mph)" ;
VAL_ 843 ADAS34B_11_3_CSTM_FCW_TYPE_CONT 1 "ON" 0 "OFF" ;
VAL_ 843 ADAS34B_11_4_FCTI_NOTICE_CONT 1 "ON" 0 "OFF" ;
VAL_ 843 ADAS34B_11_5_CSTM_SAFTY_MOD_SENS 1 "ON" 0 "OFF" ;
VAL_ 843 ADAS34B_11_6_MIS_AT_BACK_CONT 1 "ON" 0 "OFF" ;
VAL_ 843 ADAS34B_10_0_CSTM_FCTI_CONT 1 "ON" 0 "OFF" ;
VAL_ 843 ADAS34B_10_1_CSTM_FCTI_SOUND 1 "ON" 0 "OFF" ;
VAL_ 843 ADAS34B_10_2_CSTM_FCTI_PULSE 1 "ON" 0 "OFF" ;
VAL_ 843 ADAS34B_10_3_CSTM_SAFTY_MODE 1 "ON" 0 "OFF" ;
VAL_ 843 ADAS34B_10_4_CSTM_SAFTY_MODE_LV 3 "No_Definition" 2 "High" 1 "Low" 0 "Middle" ;
VAL_ 843 ADAS34B_10_6_CSTM_BRK_TIMING_CUR 1 "ON" 0 "OFF" ;
VAL_ 843 ADAS34B_10_7_CSTM_FCW_CONT_CUR 1 "ON" 0 "OFF" ;
VAL_ 843 ADAS34B_9_0_CSTM_P_CR 1 "ON" 0 "OFF" ;
VAL_ 843 ADAS34B_9_1_FCW_SOUND_ON_OFF_SW 1 "ON" 0 "OFF" ;
VAL_ 843 ADAS34B_9_2_CSTM_FCW_TIMING 3 "No_Definition" 2 "Far" 1 "Near" 0 "Middle" ;
VAL_ 843 ADAS34B_9_4_CSTM_FCW_TYPE_SOUND 1 "ON" 0 "OFF" ;
VAL_ 843 ADAS34B_9_5_CSTM_FCW_TYPE_PULSE 1 "ON" 0 "OFF" ;
VAL_ 843 ADAS34B_9_6_CSTM_BRAKE_TIMING 3 "No_Definition" 2 "No_Definition" 1 "Far" 0 "Middle" ;
VAL_ 843 ADAS34B_8_0_SAFTY_MODE_SENS_DISP 3 "Grey_out" 2 "Disp(With_setting_parts)" 1 "Disp(No_setting_parts)" 0 "No_Disp" ;
VAL_ 843 ADAS34B_8_2_MIS_AT_BACK_PTN_DISP 3 "Grey_out" 2 "Disp(With_setting_parts)" 1 "Disp(No_setting_parts)" 0 "No_Disp" ;
VAL_ 843 ADAS34B_7_0_MIS_AT_BACK_DISP 3 "Grey_out" 2 "Disp(With_setting_parts)" 1 "Disp(No_setting_parts)" 0 "No_Disp" ;
VAL_ 843 ADAS34B_7_2_MIS_AT_BACK_LIM_DISP 3 "Grey_out" 2 "Disp(With_setting_parts)" 1 "Disp(No_setting_parts)" 0 "No_Disp" ;
VAL_ 843 ADAS34B_7_4_BRK_TIMING_PTN_DISP 3 "Grey_out" 2 "Disp(With_setting_parts)" 1 "Disp(No_setting_parts)" 0 "No_Disp" ;
VAL_ 843 ADAS34B_7_6_FCW_TIMING_PTN_DISP 3 "Grey_out" 2 "Disp(With_setting_parts)" 1 "Disp(No_setting_parts)" 0 "No_Disp" ;
VAL_ 843 ADAS34B_6_0_SAFTY_MODE_DISP_CONT 3 "Grey_out" 2 "Disp(With_setting_parts)" 1 "Disp(No_setting_parts)" 0 "No_Disp" ;
VAL_ 843 ADAS34B_6_2_SAFTY_MODE_LV_DISP 3 "Grey_out" 2 "Disp(With_setting_parts)" 1 "Disp(No_setting_parts)" 0 "No_Disp" ;
VAL_ 843 ADAS34B_6_4_SAFTY_MODE_LV_PTN 7 "No_Definition" 6 "No_Definition" 5 "No_Definition" 4 "No_Definition" 3 "Pattern④(Low/High)" 2 "Pattern③(Low/Middle)" 1 "Pattern②(Middle/High)" 0 "Pattern①(Low/Middle/High)" ;
VAL_ 843 ADAS34B_5_0_FCTI_DISP_CONT 3 "Grey_out" 2 "Disp(With_setting_parts)" 1 "Disp(No_setting_parts)" 0 "No_Disp" ;
VAL_ 843 ADAS34B_5_2_FCTI_NOTICE_DISP 3 "Grey_out" 2 "Disp(With_setting_parts)" 1 "Disp(No_setting_parts)" 0 "No_Disp" ;
VAL_ 843 ADAS34B_5_4_FCTI_SOUND_DISP_CONT 3 "Grey_out" 2 "Disp(With_setting_parts)" 1 "Disp(No_setting_parts)" 0 "No_Disp" ;
VAL_ 843 ADAS34B_5_6_FCTI_PULSE_DISP_CONT 3 "Grey_out" 2 "Disp(With_setting_parts)" 1 "Disp(No_setting_parts)" 0 "No_Disp" ;
VAL_ 843 ADAS34B_4_0_FCW_TYPE_DISP_CONT 3 "Grey_out" 2 "Disp(With_setting_parts)" 1 "Disp(No_setting_parts)" 0 "No_Disp" ;
VAL_ 843 ADAS34B_4_2_FCW_TYPE_SOUND_DISP 3 "Grey_out" 2 "Disp(With_setting_parts)" 1 "Disp(No_setting_parts)" 0 "No_Disp" ;
VAL_ 843 ADAS34B_4_4_FCW_TYPE_PULSE_DISP 3 "Grey_out" 2 "Disp(With_setting_parts)" 1 "Disp(No_setting_parts)" 0 "No_Disp" ;
VAL_ 843 ADAS34B_4_6_FCW_SOUND_SW_DISP 3 "Grey_out" 2 "Disp(With_setting_parts)" 1 "Disp(No_setting_parts)" 0 "No_Disp" ;
VAL_ 843 ADAS34B_3_0_P_CR_DISP_CONT 3 "Grey_out" 2 "Disp(With_setting_parts)" 1 "Disp(No_setting_parts)" 0 "No_Disp" ;
VAL_ 843 ADAS34B_3_2_BRAKE_TIMING_DISP 3 "Grey_out" 2 "Disp(With_setting_parts)" 1 "Disp(No_setting_parts)" 0 "No_Disp" ;
VAL_ 843 ADAS34B_3_4_FCW_DISP_CONT 3 "Grey_out" 2 "Disp(With_setting_parts)" 1 "Disp(No_setting_parts)" 0 "No_Disp" ;
VAL_ 843 ADAS34B_3_6_FCW_TIMING_DISP_PTN 3 "Pattern④(Near/Far)" 2 "Pattern③(Middle/Far)" 1 "Pattern②(Near/Middle)" 0 "Pattern①(Near/Middle/Far)" ;
VAL_ 841 ADAS349_4_0_AAOS_AEB_STATE 4 "USER_OVERRIDE" 2 "ACTIVATED" 1 "ENABLED" 0 "OTHER" ;
VAL_ 841 ADAS349_3_0_CID_MRM_DISP 9 "No_Definition" 8 "Pattern8" 7 "Pattern7" 6 "Pattern6" 5 "Pattern5" 4 "Pattern4" 3 "Pattern3" 2 "Pattern2" 1 "Pattern1" 0 "OFF" ;
